VERSION ""

NS_ :

BS_:

BU_: APIM_CISM FCIMB RACM_RCIM DSP WCM DACMC HUD_ADV TRM_ITRM ACM GWM _delete APIM IPC GENERIC TSTR

BO_ 1056 SelectDriveModeData_HS3: 8 GWM
 SG_ AutoEpbButtnOn_B_Stat : 48|1@0+ (1,0) [0|1] "SED"  APIM,APIM_CISM
 SG_ PrkBrkElRleas_B_RqApa : 38|1@0+ (1,0) [0|0] "SED"  GENERIC
 SG_ AutoEpbMsgTxt_D_Rq : 58|3@0+ (1,0) [0|7] "SED"  APIM_CISM,APIM
 SG_ AutoEpbDsply_D_Stat : 37|2@0+ (1,0) [0|3] "SED"  APIM,APIM_CISM
 SG_ SelDrvMdePos12_B_Avail : 54|1@0+ (1,0) [0|1] "SED"  APIM_CISM,APIM,IPC
 SG_ SelDrvMdePos11_B_Avail : 55|1@0+ (1,0) [0|1] "SED"  APIM_CISM,APIM,IPC
 SG_ SelDrvMdePos10_B_Avail : 40|1@0+ (1,0) [0|1] "SED"  APIM_CISM,APIM,IPC
 SG_ SelDrvMdePos09_B_Avail : 41|1@0+ (1,0) [0|1] "SED"  APIM_CISM,APIM,IPC
 SG_ SelDrvMdePos08_B_Avail : 42|1@0+ (1,0) [0|1] "SED"  APIM_CISM,APIM,IPC
 SG_ SelDrvMdePos07_B_Avail : 43|1@0+ (1,0) [0|1] "SED"  APIM_CISM,APIM,IPC
 SG_ SelDrvMdePos06_B_Avail : 44|1@0+ (1,0) [0|1] "SED"  APIM_CISM,APIM,IPC
 SG_ SelDrvMdePos05_B_Avail : 45|1@0+ (1,0) [0|1] "SED"  APIM_CISM,APIM,IPC
 SG_ SelDrvMdePos04_B_Avail : 46|1@0+ (1,0) [0|1] "SED"  APIM_CISM,APIM,IPC
 SG_ SelDrvMdePos03_B_Avail : 47|1@0+ (1,0) [0|1] "SED"  APIM_CISM,APIM,IPC
 SG_ SelDrvMdePos02_B_Avail : 32|1@0+ (1,0) [0|1] "SED"  APIM_CISM,APIM,IPC
 SG_ SelDrvMdePos01_B_Avail : 24|1@0+ (1,0) [0|1] "SED"  APIM_CISM,APIM,IPC
 SG_ ActvDrvMde_D2_Stat : 53|5@0+ (1,0) [0|31] "SED"  APIM_CISM,HUD_ADV,APIM,DACMC,ACM,IPC
 SG_ SelDrvMde_D2_Rq : 63|5@0+ (1,0) [0|31] "SED"  APIM_CISM,APIM,IPC
 SG_ AwdMde_D_RqBrk : 35|3@0+ (1,0) [0|7] "SED"  GENERIC
 SG_ SelDrvMdeHmi03_D_Rq : 12|5@0+ (1,0) [0|31] "SED"  GENERIC
 SG_ SelDrvMdeMsgTxt2_D_Rq : 23|4@0+ (1,0) [0|15] "SED"  APIM_CISM,APIM
 SG_ SelDrvMdePt_D_Rq : 31|5@0+ (1,0) [0|31] "SED"  GENERIC
 SG_ SelDrvMdeMsgTxt_D_Rq : 19|4@0+ (1,0) [0|15] "SED"  IPC
 SG_ SelDrvMde_D_Stat : 26|2@0+ (1,0) [0|3] "SED"  APIM_CISM,APIM,IPC

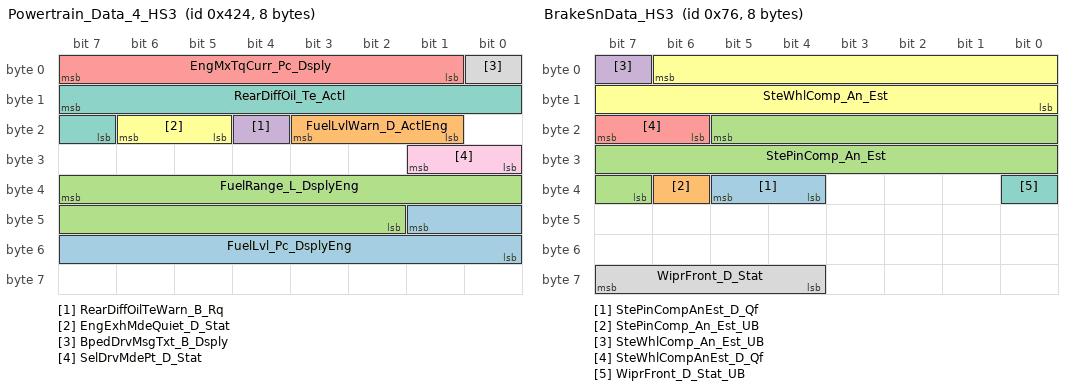
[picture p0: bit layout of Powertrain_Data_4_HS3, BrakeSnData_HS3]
BO_ 1060 Powertrain_Data_4_HS3: 8 GWM
 SG_ FuelLvl_Pc_DsplyEng : 41|10@0+ (0.108696,-5.217408) [-5.217408|105.9786] "percent"  APIM_CISM,APIM,IPC
 SG_ FuelLvlWarn_D_ActlEng : 19|3@0+ (1,0) [0|7] "SED"  APIM_CISM,APIM,IPC
 SG_ FuelRange_L_DsplyEng : 39|14@0+ (0.1,0) [0|1638.3] "kilometer"  IPC
 SG_ RearDiffOilTeWarn_B_Rq : 20|1@0+ (1,0) [0|1] "SED"  IPC
 SG_ EngMxTqCurr_Pc_Dsply : 7|7@0+ (1,0) [0|100] "percent"  IPC
 SG_ EngExhMdeQuiet_D_Stat : 22|2@0+ (1,0) [0|3] "SED"  APIM_CISM,ACM,IPC
 SG_ RearDiffOil_Te_Actl : 15|9@0+ (1,-40) [-40|470] "degC"  APIM_CISM,APIM,IPC
 SG_ BpedDrvMsgTxt_B_Dsply : 0|1@0+ (1,0) [0|1] "SED"  IPC
 SG_ SelDrvMdePt_D_Stat : 25|2@0+ (1,0) [0|3] "SED"  GENERIC

BO_ 118 BrakeSnData_HS3: 8 GWM
 SG_ StePinCompAnEst_D_Qf : 37|2@0+ (1,0) [0|3] "SED"  APIM,APIM_CISM,IPC
 SG_ StePinComp_An_Est_UB : 38|1@0+ (1,0) [0|1] "SED"  APIM,APIM_CISM,IPC
 SG_ StePinComp_An_Est : 21|15@0+ (0.1,-1600) [-1600|1676.7] "degrees"  APIM,APIM_CISM,IPC
 SG_ SteWhlComp_An_Est_UB : 7|1@0+ (1,0) [0|1] "SED"  APIM_CISM,APIM,IPC
 SG_ SteWhlCompAnEst_D_Qf : 23|2@0+ (1,0) [0|3] "SED"  IPC
 SG_ SteWhlComp_An_Est : 6|15@0+ (0.1,-1600) [-1600|1676.7] "deg"  APIM_CISM,APIM,IPC
 SG_ WiprFront_D_Stat_UB : 32|1@0+ (1,0) [0|1] "SED"  APIM_CISM,APIM
 SG_ WiprFront_D_Stat : 63|4@0+ (1,0) [0|15] "SED"  APIM_CISM,APIM

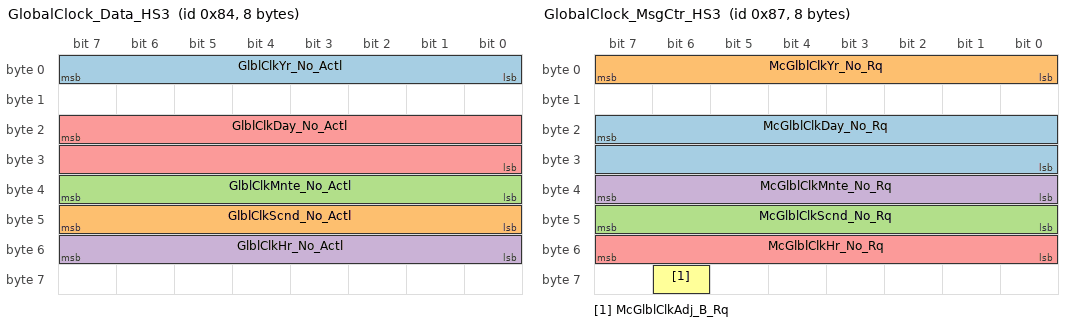
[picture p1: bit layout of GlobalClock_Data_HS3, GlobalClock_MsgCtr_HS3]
BO_ 132 GlobalClock_Data_HS3: 8 GWM
 SG_ GlblClkYr_No_Actl : 7|8@0+ (1,2000) [2000|2255] "year"  APIM_CISM,RACM_RCIM,HUD_ADV,APIM,IPC
 SG_ GlblClkScnd_No_Actl : 47|8@0+ (1,0) [0|255] "second"  APIM_CISM,RACM_RCIM,HUD_ADV,APIM,IPC
 SG_ GlblClkMnte_No_Actl : 39|8@0+ (1,0) [0|255] "minute"  APIM_CISM,RACM_RCIM,HUD_ADV,APIM,IPC
 SG_ GlblClkHr_No_Actl : 55|8@0+ (1,0) [0|255] "hour"  APIM_CISM,RACM_RCIM,HUD_ADV,APIM,IPC
 SG_ GlblClkDay_No_Actl : 23|16@0+ (1,0) [0|65535] "julian day"  APIM_CISM,RACM_RCIM,HUD_ADV,APIM,IPC

BO_ 135 GlobalClock_MsgCtr_HS3: 8 IPC
 SG_ McGlblClkDay_No_Rq : 23|16@0+ (1,0) [0|65535] "julian day"  GWM
 SG_ McGlblClkYr_No_Rq : 7|8@0+ (1,2000) [2000|2255] "year"  GWM
 SG_ McGlblClkScnd_No_Rq : 47|8@0+ (1,0) [0|255] "second"  GWM
 SG_ McGlblClkMnte_No_Rq : 39|8@0+ (1,0) [0|255] "minute"  GWM
 SG_ McGlblClkHr_No_Rq : 55|8@0+ (1,0) [0|255] "hour"  GWM
 SG_ McGlblClkAdj_B_Rq : 62|1@0+ (1,0) [0|1] "SED"  GWM

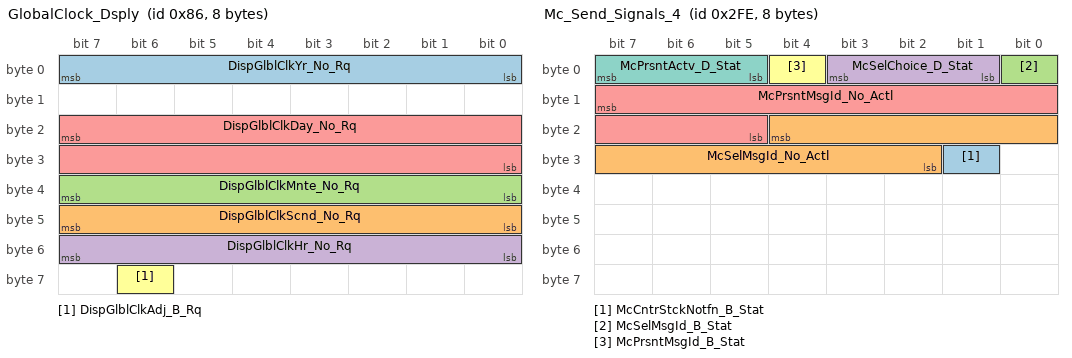
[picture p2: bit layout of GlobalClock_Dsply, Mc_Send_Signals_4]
BO_ 134 GlobalClock_Dsply: 8 APIM
 SG_ DispGlblClkYr_No_Rq : 7|8@0+ (1,2000) [2000|2255] "year"  IPC,GWM
 SG_ DispGlblClkScnd_No_Rq : 47|8@0+ (1,0) [0|255] "second"  IPC,GWM
 SG_ DispGlblClkMnte_No_Rq : 39|8@0+ (1,0) [0|255] "minute"  IPC,GWM
 SG_ DispGlblClkHr_No_Rq : 55|8@0+ (1,0) [0|255] "hour"  IPC,GWM
 SG_ DispGlblClkDay_No_Rq : 23|16@0+ (1,0) [0|65535] "julian day"  IPC,GWM
 SG_ DispGlblClkAdj_B_Rq : 62|1@0+ (1,0) [0|1] "SED"  IPC,GWM

BO_ 766 Mc_Send_Signals_4: 8 APIM
 SG_ McCntrStckNotfn_B_Stat : 25|1@0+ (1,0) [0|1] "SED"  IPC
 SG_ McSelMsgId_No_Actl : 20|11@0+ (1,0) [0|2047] "unitless"  IPC
 SG_ McSelMsgId_B_Stat : 0|1@0+ (1,0) [0|1] "SED"  IPC
 SG_ McSelChoice_D_Stat : 3|3@0+ (1,0) [0|7] "SED"  IPC
 SG_ McPrsntMsgId_No_Actl : 15|11@0+ (1,0) [0|2047] "unitless"  IPC
 SG_ McPrsntMsgId_B_Stat : 4|1@0+ (1,0) [0|1] "SED"  IPC
 SG_ McPrsntActv_D_Stat : 7|3@0+ (1,0) [0|7] "SED"  IPC

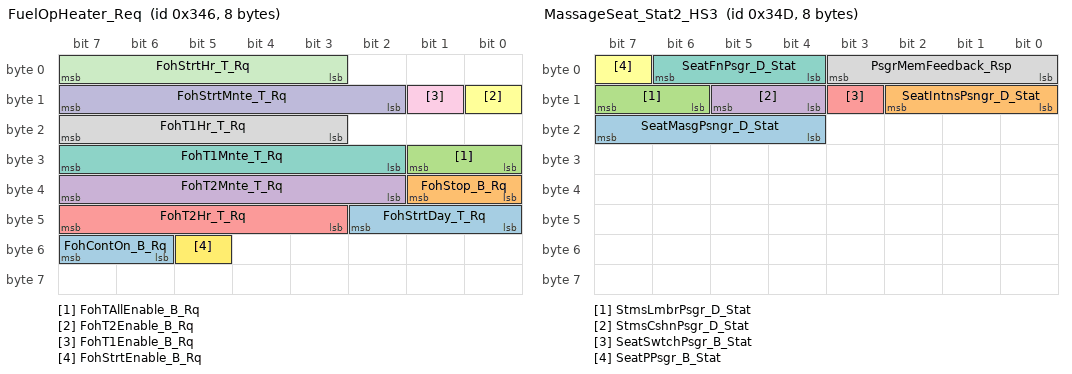
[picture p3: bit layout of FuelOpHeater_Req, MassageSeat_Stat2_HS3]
BO_ 838 FuelOpHeater_Req: 8 IPC
 SG_ FohStrtDay_T_Rq : 42|3@0+ (1,0) [0|7] "SED"  GWM
 SG_ FohStop_B_Rq : 33|2@0+ (1,0) [0|3] "SED"  GWM
 SG_ FohTAllEnable_B_Rq : 25|2@0+ (1,0) [0|3] "SED"  GWM
 SG_ FohT2Mnte_T_Rq : 39|6@0+ (1,0) [0|63] "minute"  GWM
 SG_ FohT2Hr_T_Rq : 47|5@0+ (1,0) [0|31] "hour"  GWM
 SG_ FohT2Enable_B_Rq : 8|1@0+ (1,0) [0|1] "SED"  GWM
 SG_ FohT1Mnte_T_Rq : 31|6@0+ (1,0) [0|63] "minute"  GWM
 SG_ FohT1Hr_T_Rq : 23|5@0+ (1,0) [0|31] "hour"  GWM
 SG_ FohT1Enable_B_Rq : 9|1@0+ (1,0) [0|1] "SED"  GWM
 SG_ FohStrtMnte_T_Rq : 15|6@0+ (1,0) [0|63] "minute"  GWM
 SG_ FohStrtHr_T_Rq : 7|5@0+ (1,0) [0|31] "hour"  GWM
 SG_ FohStrtEnable_B_Rq : 53|1@0+ (1,0) [0|1] "SED"  GWM
 SG_ FohContOn_B_Rq : 55|2@0+ (1,0) [0|3] "SED"  GWM

BO_ 559 ElecHorizon_Data2: 8 APIM
 SG_ EhData2_No_Actl : 7|64@0+ (1,0) [0|1.84467440737096E+019] "unitless"  HUD_ADV,GWM

BO_ 558 ElecHorizon_Data1: 8 APIM
 SG_ EhData1_No_Actl : 7|64@0+ (1,0) [0|1.84467440737096E+019] "unitless"  HUD_ADV,GWM

BO_ 939 ParkAid_Aud_Warn_Stat2_HS3: 8 GWM
 SG_ PrkAidSnsRlSide_D_Stat : 23|4@0+ (1,0) [0|15] "SED"  APIM_CISM,APIM,IPC
 SG_ SidePrkSnsR4_D_Stat : 55|4@0+ (1,0) [0|15] "SED"  APIM_CISM,APIM,IPC
 SG_ SidePrkSnsR3_D_Stat : 47|4@0+ (1,0) [0|15] "SED"  APIM_CISM,APIM,IPC
 SG_ SidePrkSnsL4_D_Stat : 43|4@0+ (1,0) [0|15] "SED"  APIM_CISM,APIM,IPC
 SG_ SidePrkSnsL3_D_Stat : 37|4@0+ (1,0) [0|15] "SED"  APIM_CISM,APIM,IPC
 SG_ PrkAidChime_D_Stat : 4|2@0+ (1,0) [0|3] "SED"  IPC
 SG_ PrkAidSnsRlCntr_D_Stat : 15|4@0+ (1,0) [0|15] "SED"  APIM_CISM,APIM,IPC
 SG_ PrkAidSnsRrCrnr_D_Stat : 31|4@0+ (1,0) [0|15] "SED"  APIM_CISM,APIM,IPC
 SG_ PrkAidSnsRrCntr_D_Stat : 19|4@0+ (1,0) [0|15] "SED"  APIM_CISM,APIM,IPC
 SG_ PrkAidSnsRlCrnr_D_Stat : 11|4@0+ (1,0) [0|15] "SED"  APIM_CISM,APIM,IPC
 SG_ PrkAidRear_D_Stat : 39|2@0+ (1,0) [0|3] "SED"  APIM_CISM,APIM,IPC
 SG_ PrkAidFront_D_Stat : 2|2@0+ (1,0) [0|3] "SED"  APIM_CISM,APIM,IPC
 SG_ PrkAid_D_Falt : 7|3@0+ (1,0) [0|7] "SED"  IPC
 SG_ PrkAidSnsRrSide_D_Stat : 27|4@0+ (1,0) [0|15] "SED"  APIM_CISM,APIM,IPC
 SG_ PrkAidLamp_D_Rq : 33|2@0+ (1,0) [0|3] "SED"  FCIMB
 SG_ ApaLongCtrlEnbl_D_Rq : 0|1@0+ (1,0) [0|1] "SED"  GENERIC
 SG_ ApaBrk_A_Rq : 63|8@0+ (0.05,-12.75) [-12.75|0] "m/sec^2"  GENERIC
 SG_ ApaBrk_D_Rq : 51|2@0+ (1,0) [0|3] "SED"  GENERIC

BO_ 938 ParkAid_Aud_Warn_Stat_HS3: 8 GWM
 SG_ SidePrkSnsR2_D_Stat : 59|4@0+ (1,0) [0|15] "SED"  APIM_CISM,APIM,IPC
 SG_ SidePrkSnsR1_D_Stat : 63|4@0+ (1,0) [0|15] "SED"  APIM_CISM,APIM,IPC
 SG_ SidePrkSnsL2_D_Stat : 51|4@0+ (1,0) [0|15] "SED"  APIM_CISM,APIM,IPC
 SG_ SidePrkSnsL1_D_Stat : 55|4@0+ (1,0) [0|15] "SED"  APIM_CISM,APIM,IPC
 SG_ ApaMde_D_Stat : 23|3@0+ (1,0) [0|7] "SED"  APIM_CISM,APIM,IPC
 SG_ ApaActvSd_D_Actl : 14|2@0+ (1,0) [0|3] "SED"  APIM_CISM,APIM,IPC
 SG_ PrkAidSwtch_B_Stat : 8|1@0+ (1,0) [0|1] "SED"  APIM_CISM,APIM,IPC
 SG_ PrkAidMsgTxt_D_Rq : 19|4@0+ (1,0) [0|15] "SED"  APIM_CISM,APIM,IPC
 SG_ ApaMde_D_Avail : 12|4@0+ (1,0) [0|15] "SED"  APIM_CISM,APIM
 SG_ PrkAidSnsFrSide_D_Stat : 43|4@0+ (1,0) [0|15] "SED"  APIM_CISM,APIM,IPC
 SG_ PrkAidSnsFrCrnr_D_Stat : 47|4@0+ (1,0) [0|15] "SED"  APIM_CISM,APIM,IPC
 SG_ PrkAidSnsFrCntr_D_Stat : 35|4@0+ (1,0) [0|15] "SED"  APIM_CISM,APIM,IPC
 SG_ PrkAidSnsFlSide_D_Stat : 39|4@0+ (1,0) [0|15] "SED"  APIM_CISM,APIM,IPC
 SG_ PrkAidSnsFlCrnr_D_Stat : 27|4@0+ (1,0) [0|15] "SED"  APIM_CISM,APIM,IPC
 SG_ PrkAidSnsFlCntr_D_Stat : 31|4@0+ (1,0) [0|15] "SED"  APIM,APIM_CISM,IPC
 SG_ RpaChime_D_Rq : 7|4@0+ (1,0) [0|15] "SED"  APIM_CISM,APIM,IPC
 SG_ FpaChime_D_Rq : 3|4@0+ (1,0) [0|15] "SED"  APIM_CISM,APIM,IPC
 SG_ PrkAidAudioMute_B_Rq : 15|1@0+ (1,0) [0|1] "SED"  IPC
 SG_ PrkBrkEl_B_RqFap : 20|1@0+ (1,0) [0|1] "SED"  GENERIC

BO_ 952 Tire_Pressure_Data_DRW_HS3: 8 GWM
 SG_ Tire_Press_IRR_Data : 23|16@0+ (1,0) [0|65533] "kilopascal"  APIM_CISM,APIM,IPC
 SG_ Tire_Press_ILR_Data : 7|16@0+ (1,0) [0|65533] "kilopascal"  APIM_CISM,APIM,IPC

BO_ 845 MassageSeat_Stat2_HS3: 8 GWM
 SG_ SeatMasgPsngr_D_Stat : 23|4@0+ (1,0) [0|15] "SED"  APIM_CISM,APIM
 SG_ SeatIntnsPsngr_D_Stat : 10|3@0+ (1,0) [0|7] "SED"  APIM_CISM,APIM
 SG_ StmsLmbrPsgr_D_Stat : 15|2@0+ (1,0) [0|3] "SED"  APIM_CISM,APIM
 SG_ StmsCshnPsgr_D_Stat : 13|2@0+ (1,0) [0|3] "SED"  APIM_CISM,APIM
 SG_ SeatSwtchPsgr_B_Stat : 11|1@0+ (1,0) [0|1] "SED"  APIM_CISM,APIM
 SG_ SeatPPsgr_B_Stat : 7|1@0+ (1,0) [0|1] "SED"  APIM_CISM,APIM
 SG_ SeatFnPsgr_D_Stat : 6|3@0+ (1,0) [0|7] "SED"  APIM_CISM,APIM
 SG_ PsgrMemFeedback_Rsp : 3|4@0+ (1,0) [0|15] "SED"  APIM_CISM,APIM

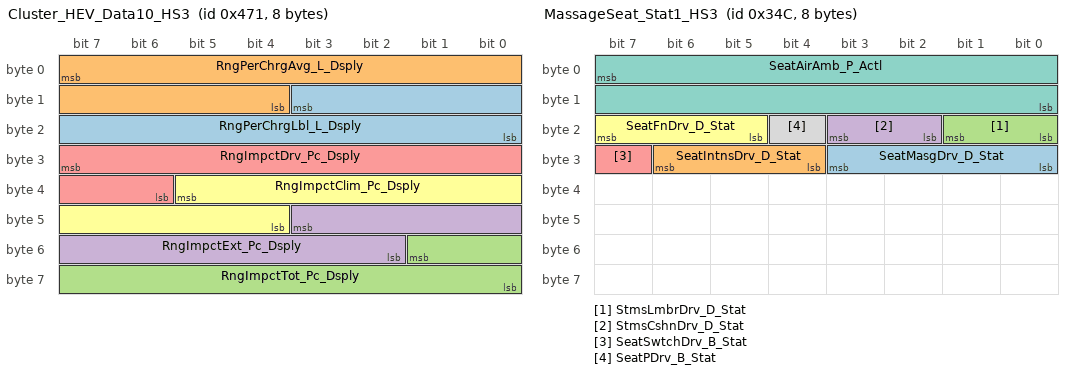
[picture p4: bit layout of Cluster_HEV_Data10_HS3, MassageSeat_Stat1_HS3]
BO_ 1137 Cluster_HEV_Data10_HS3: 8 GWM
 SG_ RngPerChrgLbl_L_Dsply : 11|12@0+ (0.1,0) [0|409.3] "km"  IPC
 SG_ RngPerChrgAvg_L_Dsply : 7|12@0+ (0.1,0) [0|409.3] "km"  APIM,IPC
 SG_ RngImpctTot_Pc_Dsply : 49|10@0+ (0.2,-102) [-102|102.4] "percent"  IPC
 SG_ RngImpctExt_Pc_Dsply : 43|10@0+ (0.2,-102) [-102|102.4] "percent"  IPC
 SG_ RngImpctDrv_Pc_Dsply : 31|10@0+ (0.2,-102) [-102|102.4] "percent"  IPC
 SG_ RngImpctClim_Pc_Dsply : 37|10@0+ (0.2,-102) [-102|102.4] "percent"  IPC

BO_ 1073 BodyEngGateway_1_HS3: 8 GWM
 SG_ AutoHoldMsgTxt_D_Rq : 62|4@0+ (1,0) [0|15] "SED"  IPC
 SG_ AutoHoldMde_D_Ind : 55|2@0+ (1,0) [0|3] "SED"  IPC
 SG_ SteEffort_D_Stat : 42|3@0+ (1,0) [0|7] "SED"  IPC
 SG_ TbsLamp_D_RqDsply : 33|2@0+ (1,0) [0|3] "SED"  IPC
 SG_ TrnMsgTxt_D_Rq : 30|4@0+ (1,0) [0|15] "SED"  IPC
 SG_ TrnGearNtmAllow_B_Stat : 22|1@0+ (1,0) [0|1] "SED"  APIM,IPC
 SG_ TrnGearMsgTxt_D_Rq : 20|5@0+ (1,0) [0|31] "SED"  APIM_CISM,IPC
 SG_ FuelFlw_Vl_ActlFoh : 7|16@0+ (25,0) [0|1638375] "microlitre"  APIM_CISM,APIM,IPC
 SG_ PdstrnAlrt_B_Falt_UB : 47|1@0+ (1,0) [0|1] "SED"  IPC
 SG_ PdstrnAlrt_B_Falt : 34|1@0+ (1,0) [0|1] "SED"  IPC
 SG_ TrnMsgTxt_D_Rq_UB : 26|1@0+ (1,0) [0|1] "SED"  IPC
 SG_ TrnMsgTxt2_D_Rq_UB : 25|1@0+ (1,0) [0|1] "SED"  IPC
 SG_ TrnGearNtmAllow_B_Stat_UB : 21|1@0+ (1,0) [0|1] "SED"  APIM,IPC
 SG_ TrnGearMsgTxt_D_Rq_UB : 31|1@0+ (1,0) [0|1] "SED"  APIM_CISM,APIM,IPC
 SG_ TbsLamp_D_RqDsply_UB : 24|1@0+ (1,0) [0|1] "SED"  IPC
 SG_ SteEffort_D_Stat_UB : 43|1@0+ (1,0) [0|1] "SED"  IPC
 SG_ RvrseMirrorChime_B_Rq_UB : 35|1@0+ (1,0) [0|1] "SED"  IPC
 SG_ FuelFlw_Vl_ActlFoh_UB : 23|1@0+ (1,0) [0|1] "SED"  APIM_CISM,APIM,IPC
 SG_ AutoHoldMsgTxt_D_Rq_UB : 58|1@0+ (1,0) [0|1] "SED"  IPC
 SG_ AutoHoldMde_D_Ind_UB : 63|1@0+ (1,0) [0|1] "SED"  IPC
 SG_ RvrseMirrorChime_B_Rq : 36|1@0+ (1,0) [0|1] "SED"  IPC
 SG_ TrnMsgTxt2_D_Rq : 39|3@0+ (1,0) [0|7] "SED"  IPC

BO_ 844 MassageSeat_Stat1_HS3: 8 GWM
 SG_ SeatMasgDrv_D_Stat : 27|4@0+ (1,0) [0|15] "SED"  APIM_CISM,APIM
 SG_ SeatIntnsDrv_D_Stat : 30|3@0+ (1,0) [0|7] "SED"  APIM_CISM,APIM
 SG_ StmsLmbrDrv_D_Stat : 17|2@0+ (1,0) [0|3] "SED"  APIM_CISM,APIM
 SG_ StmsCshnDrv_D_Stat : 19|2@0+ (1,0) [0|3] "SED"  APIM_CISM,APIM
 SG_ SeatSwtchDrv_B_Stat : 31|1@0+ (1,0) [0|1] "SED"  APIM_CISM,APIM
 SG_ SeatFnDrv_D_Stat : 23|3@0+ (1,0) [0|7] "SED"  APIM_CISM,APIM
 SG_ SeatAirAmb_P_Actl : 7|16@0+ (0.01,0) [0|655.35] "KiloPascal"  APIM_CISM,APIM
 SG_ SeatPDrv_B_Stat : 20|1@0+ (1,0) [0|1] "SED"  APIM_CISM,APIM

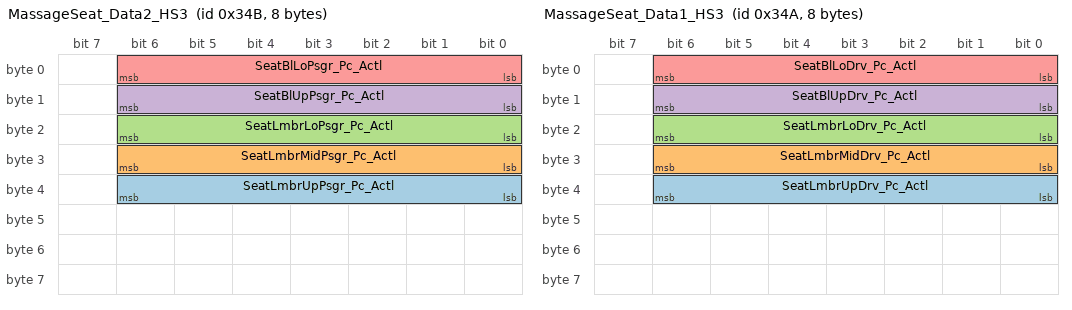
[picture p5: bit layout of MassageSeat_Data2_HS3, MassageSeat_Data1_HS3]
BO_ 843 MassageSeat_Data2_HS3: 8 GWM
 SG_ SeatLmbrUpPsgr_Pc_Actl : 38|7@0+ (1,0) [0|127] "Percent"  APIM_CISM,APIM
 SG_ SeatLmbrMidPsgr_Pc_Actl : 30|7@0+ (1,0) [0|127] "Percent"  APIM_CISM,APIM
 SG_ SeatLmbrLoPsgr_Pc_Actl : 22|7@0+ (1,0) [0|127] "Percent"  APIM_CISM,APIM
 SG_ SeatBlUpPsgr_Pc_Actl : 14|7@0+ (1,0) [0|126] "Percent"  APIM_CISM,APIM
 SG_ SeatBlLoPsgr_Pc_Actl : 6|7@0+ (1,0) [0|126] "Percent"  APIM_CISM,APIM

BO_ 842 MassageSeat_Data1_HS3: 8 GWM
 SG_ SeatLmbrUpDrv_Pc_Actl : 38|7@0+ (1,0) [0|127] "Percent"  APIM_CISM,APIM
 SG_ SeatLmbrMidDrv_Pc_Actl : 30|7@0+ (1,0) [0|127] "Percent"  APIM_CISM,APIM
 SG_ SeatLmbrLoDrv_Pc_Actl : 22|7@0+ (1,0) [0|127] "Percent"  APIM_CISM,APIM
 SG_ SeatBlUpDrv_Pc_Actl : 14|7@0+ (1,0) [0|126] "Percent"  APIM_CISM,APIM
 SG_ SeatBlLoDrv_Pc_Actl : 6|7@0+ (1,0) [0|126] "Percent"  APIM_CISM,APIM

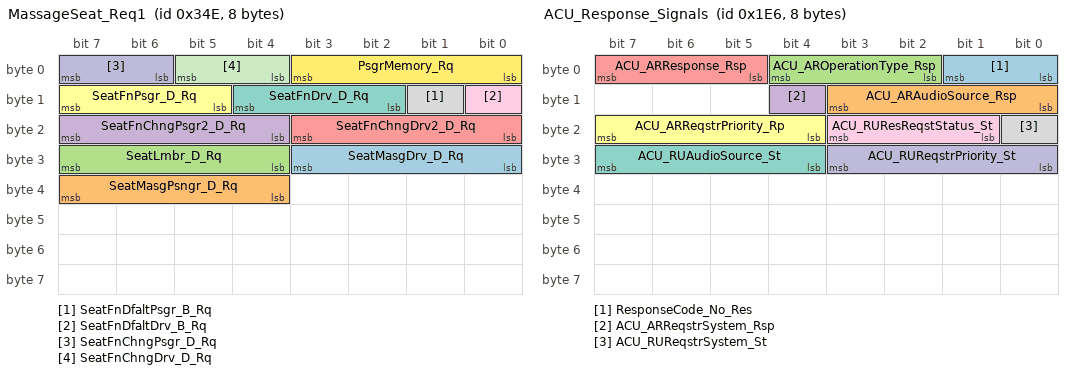
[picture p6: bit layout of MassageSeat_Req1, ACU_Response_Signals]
BO_ 846 MassageSeat_Req1: 8 APIM
 SG_ SeatMasgDrv_D_Rq : 27|4@0+ (1,0) [0|15] "SED"  GWM
 SG_ SeatMasgPsngr_D_Rq : 39|4@0+ (1,0) [0|15] "SED"  GWM
 SG_ SeatLmbr_D_Rq : 31|4@0+ (1,0) [0|15] "SED"  GWM
 SG_ SeatFnChngPsgr2_D_Rq : 23|4@0+ (1,0) [0|15] "SED"  GWM
 SG_ SeatFnChngDrv2_D_Rq : 19|4@0+ (1,0) [0|15] "SED"  GWM
 SG_ SeatFnPsgr_D_Rq : 15|3@0+ (1,0) [0|7] "SED"  GWM
 SG_ SeatFnDrv_D_Rq : 12|3@0+ (1,0) [0|7] "SED"  GWM
 SG_ SeatFnDfaltPsgr_B_Rq : 9|1@0+ (1,0) [0|1] "SED"  GWM
 SG_ SeatFnDfaltDrv_B_Rq : 8|1@0+ (1,0) [0|1] "SED"  GWM
 SG_ SeatFnChngPsgr_D_Rq : 7|2@0+ (1,0) [0|3] "SED"  GWM
 SG_ SeatFnChngDrv_D_Rq : 5|2@0+ (1,0) [0|3] "SED"  GWM
 SG_ PsgrMemory_Rq : 3|4@0+ (1,0) [0|15] "SED"  GWM

BO_ 935 Side_Detect_R_Stat_HS3: 8 GWM
 SG_ SodInnrRight_D_Stat : 20|2@0+ (1,0) [0|3] "SED"  APIM_CISM,GENERIC
 SG_ RbaCtaRight_D_Stat : 55|3@0+ (1,0) [0|7] "SED"  APIM_CISM,GENERIC
 SG_ LcwaRight_D_Stat : 52|3@0+ (1,0) [0|7] "SED"  APIM_CISM,GENERIC
 SG_ LcwaDetctRight2_B_Stat : 40|1@0+ (1,0) [0|1] "SED"  APIM_CISM,GENERIC
 SG_ LcwaDetctRight1_B_Stat : 41|1@0+ (1,0) [0|1] "SED"  APIM_CISM,GENERIC
 SG_ CtaInnrRight_D_Stat : 27|2@0+ (1,0) [0|3] "SED"  APIM_CISM,GENERIC
 SG_ CtaAlrtRight2_D_Stat : 30|3@0+ (1,0) [0|7] "SED"  APIM_CISM,IPC
 SG_ BttRight_D_Stat : 45|3@0+ (1,0) [0|7] "SED"  APIM_CISM,APIM,IPC
 SG_ BttRight_D_RqDrv : 47|2@0+ (1,0) [0|3] "SED"  APIM_CISM,APIM,IPC
 SG_ CtaBrkRightMsgTxt_B_Rq : 42|1@0+ (1,0) [0|1] "SED"  APIM_CISM,IPC
 SG_ CtaRightBrkEnbl_B_Rq : 31|1@0+ (1,0) [0|1] "SED"  APIM_CISM,GENERIC
 SG_ Side_Detect_R_Illum : 39|8@0+ (1,0) [0|255] "Percent"  APIM_CISM,IPC
 SG_ CtaSnsRight_D_Stat : 25|2@0+ (1,0) [0|3] "SED"  APIM_CISM,IPC
 SG_ CtaAlrtRight_D_Stat : 8|1@0+ (1,0) [0|1] "SED"  APIM_CISM,APIM,IPC
 SG_ CtaRight_D_Stat : 18|3@0+ (1,0) [0|7] "SED"  APIM_CISM,IPC
 SG_ SodRight_D_Stat : 15|3@0+ (1,0) [0|7] "SED"  APIM_CISM,IPC
 SG_ SodSnsRight_D_Stat : 12|2@0+ (1,0) [0|3] "SED"  APIM_CISM,IPC
 SG_ CtaRightBrkDecel_B_Rq : 7|1@0+ (1,0) [0|1] "SED"  APIM_CISM,GENERIC
 SG_ SodAlrtRight_D_Stat : 10|2@0+ (1,0) [0|3] "SED"  APIM_CISM,IPC
 SG_ SodDetctRight_D_Stat : 23|3@0+ (1,0) [0|7] "SED"  APIM_CISM,IPC
 SG_ SodWarnRight_Prd_Rq : 6|7@0+ (1,0) [0|127] "millisecond"  APIM_CISM,GENERIC

BO_ 934 Side_Detect_L_Stat_HS3: 8 GWM
 SG_ SodInnrLeft_D_Stat : 20|2@0+ (1,0) [0|3] "SED"  GENERIC
 SG_ RbaCtaLeft_D_Stat : 55|3@0+ (1,0) [0|7] "SED"  GENERIC
 SG_ LcwaDetctLeft2_B_Stat : 40|1@0+ (1,0) [0|1] "SED"  GENERIC
 SG_ LcwaDetctLeft1_B_Stat : 41|1@0+ (1,0) [0|1] "SED"  GENERIC
 SG_ CtaInnrLeft_D_Stat : 27|2@0+ (1,0) [0|3] "SED"  GENERIC
 SG_ LcwaLeft_D_Stat : 52|3@0+ (1,0) [0|7] "SED"  GENERIC
 SG_ CtaAlrtLeft2_D_Stat : 30|3@0+ (1,0) [0|7] "SED"  IPC
 SG_ BttLeft_D_Stat : 45|3@0+ (1,0) [0|7] "SED"  APIM,APIM_CISM,IPC
 SG_ BttLeft_D_RqDrv : 47|2@0+ (1,0) [0|3] "SED"  APIM_CISM,APIM,IPC
 SG_ CtaBrkLeftMsgTxt_B_Rq : 42|1@0+ (1,0) [0|1] "SED"  IPC
 SG_ CtaLeftBrkDecel_B_Rq : 7|1@0+ (1,0) [0|1] "SED"  GENERIC
 SG_ CtaLeftBrkEnbl_B_Rq : 31|1@0+ (1,0) [0|1] "SED"  GENERIC
 SG_ Side_Detect_L_Illum : 39|8@0+ (1,0) [0|255] "Percent"  IPC
 SG_ CtaSnsLeft_D_Stat : 25|2@0+ (1,0) [0|3] "SED"  IPC
 SG_ SodDetctLeft_D_Stat : 23|3@0+ (1,0) [0|7] "SED"  IPC
 SG_ CtaLeft_D_Stat : 18|3@0+ (1,0) [0|7] "SED"  IPC
 SG_ CtaAlrtLeft_D_Stat : 8|1@0+ (1,0) [0|1] "SED"  APIM_CISM,APIM,IPC
 SG_ SodLeft_D_Stat : 15|3@0+ (1,0) [0|7] "SED"  IPC
 SG_ SodSnsLeft_D_Stat : 12|2@0+ (1,0) [0|3] "SED"  IPC
 SG_ SodAlrtLeft_D_Stat : 10|2@0+ (1,0) [0|3] "SED"  IPC
 SG_ SodWarnLeft_Prd_Rq : 6|7@0+ (1,0) [0|127] "millisecond"  GENERIC

BO_ 486 ACU_Response_Signals: 8 ACM
 SG_ ResponseCode_No_Res : 1|2@0+ (1,0) [0|3] "SED"  APIM
 SG_ ACU_ARAudioSource_Rsp : 11|4@0+ (1,0) [0|15] "SED"  APIM,DSP,IPC
 SG_ ACU_AROperationType_Rsp : 4|3@0+ (1,0) [0|7] "SED"  APIM,DSP,IPC
 SG_ ACU_ARReqstrSystem_Rsp : 12|1@0+ (1,0) [0|1] "SED"  APIM,DSP,IPC
 SG_ ACU_ARResponse_Rsp : 7|3@0+ (1,0) [0|6] "SED"  APIM,DSP,IPC
 SG_ ACU_ARReqstrPriority_Rp : 23|4@0+ (1,0) [0|15] "SED"  APIM,DSP,IPC
 SG_ ACU_RUAudioSource_St : 31|4@0+ (1,0) [0|15] "SED"  GWM,RACM_RCIM,APIM,DSP,WCM,IPC
 SG_ ACU_RUReqstrSystem_St : 16|1@0+ (1,0) [0|1] "SED"  RACM_RCIM,APIM,DSP,IPC
 SG_ ACU_RUResReqstStatus_St : 19|3@0+ (1,0) [0|7] "SED"  GWM,RACM_RCIM,APIM,DSP,WCM,IPC
 SG_ ACU_RUReqstrPriority_St : 27|4@0+ (1,0) [0|15] "SED"  RACM_RCIM,APIM,DSP,WCM,IPC

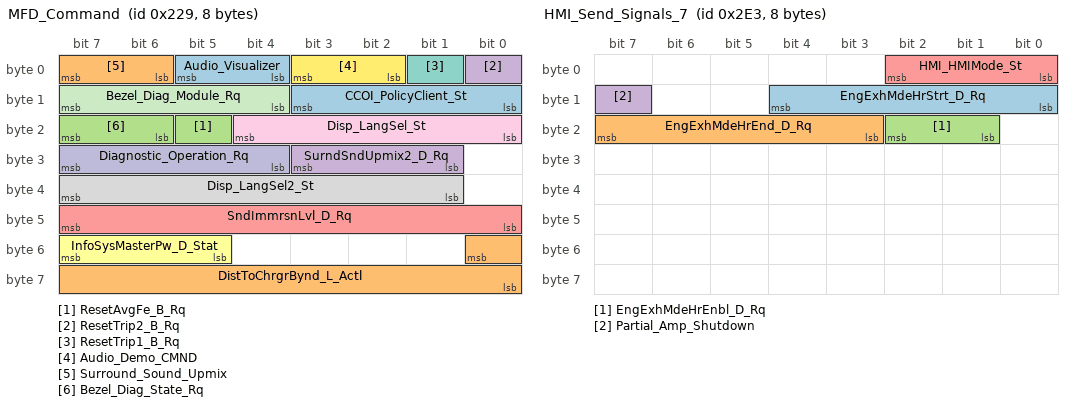
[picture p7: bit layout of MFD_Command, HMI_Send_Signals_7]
BO_ 553 MFD_Command: 8 APIM
 SG_ CCOI_PolicyClient_St : 11|4@0+ (1,0) [0|15] "SED"  GWM
 SG_ DistToChrgrBynd_L_Actl : 48|9@0+ (1,0) [0|509] "kilometer"  GWM
 SG_ ResetAvgFe_B_Rq : 21|1@0+ (1,0) [0|1] "SED"  IPC,GWM
 SG_ ResetTrip2_B_Rq : 0|1@0+ (1,0) [0|1] "SED"  GWM,IPC
 SG_ SndImmrsnLvl_D_Rq : 47|8@0+ (1,0) [0|255] "SED"  DSP,GWM
 SG_ InfoSysMasterPw_D_Stat : 55|3@0+ (1,0) [0|7] "SED"  GWM
 SG_ ResetTrip1_B_Rq : 1|1@0+ (1,0) [0|1] "SED"  GWM,IPC
 SG_ Disp_LangSel2_St : 39|7@0+ (1,0) [0|127] "SED"  GWM
 SG_ Disp_LangSel_St : 20|5@0+ (1,0) [0|31] "SED"  GWM,RACM_RCIM,IPC
 SG_ Diagnostic_Operation_Rq : 31|4@0+ (1,0) [0|15] "SED"  GWM,DSP,ACM
 SG_ Bezel_Diag_Module_Rq : 15|4@0+ (1,0) [0|15] "SED"  GWM,DSP,ACM
 SG_ Audio_Demo_CMND : 3|2@0+ (1,0) [0|3] "SED"  GWM,DSP,ACM
 SG_ Audio_Visualizer : 5|2@0+ (1,0) [0|3] "SED"  GWM,DSP,ACM
 SG_ Surround_Sound_Upmix : 7|2@0+ (1,0) [0|3] "SED"  GWM,DSP
 SG_ Bezel_Diag_State_Rq : 23|2@0+ (1,0) [0|3] "SED"  GWM,DSP,ACM
 SG_ SurndSndUpmix2_D_Rq : 27|3@0+ (1,0) [0|7] "SED"  GWM,DSP

BO_ 739 HMI_Send_Signals_7: 8 APIM
 SG_ EngExhMdeHrStrt_D_Rq : 12|5@0+ (1,0) [0|31] "SED"  GWM
 SG_ EngExhMdeHrEnd_D_Rq : 23|5@0+ (1,0) [0|31] "SED"  GWM
 SG_ EngExhMdeHrEnbl_D_Rq : 18|2@0+ (1,0) [0|3] "SED"  GWM
 SG_ Partial_Amp_Shutdown : 15|1@0+ (1,0) [0|1] "SED"  GWM,ACM
 SG_ HMI_HMIMode_St : 2|3@0+ (1,0) [0|7] "SED"  ACM,WCM,DSP,IPC,GWM

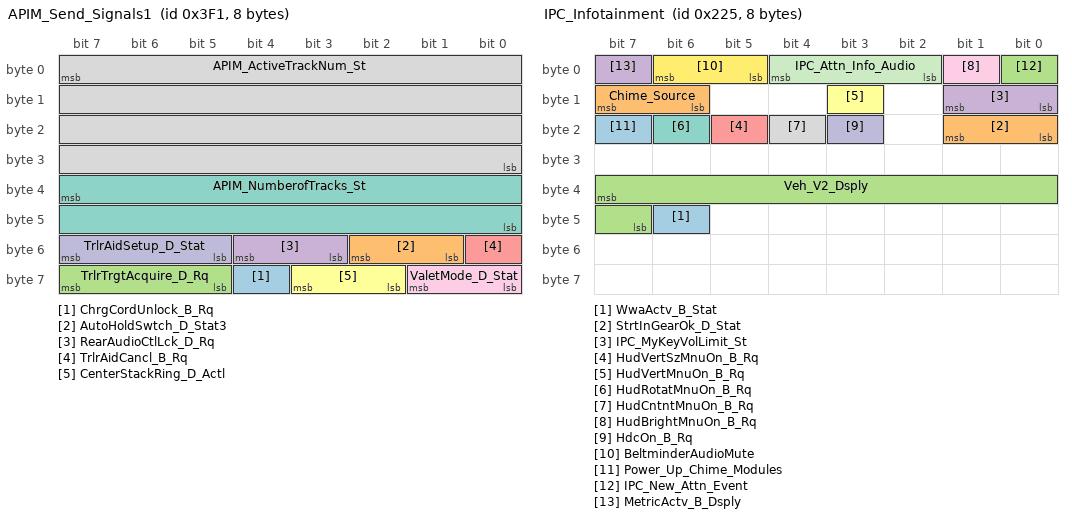
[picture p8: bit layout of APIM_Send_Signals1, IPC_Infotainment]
BO_ 1009 APIM_Send_Signals1: 8 APIM
 SG_ ChrgCordUnlock_B_Rq : 60|1@0+ (1,0) [0|1] "SED"  GWM
 SG_ AutoHoldSwtch_D_Stat3 : 50|2@0+ (1,0) [0|3] "SED"  GWM
 SG_ TrlrTrgtAcquire_D_Rq : 63|3@0+ (1,0) [0|7] "SED"  GWM
 SG_ RearAudioCtlLck_D_Rq : 52|2@0+ (1,0) [0|3] "SED"  RACM_RCIM
 SG_ TrlrAidCancl_B_Rq : 48|1@0+ (1,0) [0|1] "SED"  GWM
 SG_ CenterStackRing_D_Actl : 59|2@0+ (1,0) [0|3] "SED"  GWM
 SG_ APIM_NumberofTracks_St : 39|16@0+ (1,0) [0|65535] "unitless"  RACM_RCIM,GWM,HUD_ADV,IPC
 SG_ APIM_ActiveTrackNum_St : 7|32@0+ (1,0) [0|4294967295] "unitless"  RACM_RCIM,GWM,HUD_ADV,IPC
 SG_ ValetMode_D_Stat : 57|2@0+ (1,0) [0|3] "SED"  GWM
 SG_ TrlrAidSetup_D_Stat : 55|3@0+ (1,0) [0|7] "SED"  GWM,IPC

BO_ 531 DesiredTorqBrk_HS3: 8 GWM
 SG_ VehStop_D_Stat : 28|2@0+ (1,0) [0|3] "SED"  GENERIC
 SG_ TracCtlPtActv_B_Actl : 31|1@0+ (1,0) [0|1] "SED"  GENERIC
 SG_ PrkBrkYwLamp_D_Rq : 38|2@0+ (1,0) [0|3] "SED"  IPC
 SG_ PrkBrkRedLamp_D_Rq : 30|2@0+ (1,0) [0|3] "SED"  IPC
 SG_ PrkBrkMsgTxt_D_Rq : 36|4@0+ (1,0) [0|15] "SED"  IPC
 SG_ PrkBrkStatus : 26|3@0+ (1,0) [0|7] "SED"  APIM_CISM,APIM
 SG_ LscmbbMntr_B_Err : 17|1@0+ (1,0) [0|1] "SED"  IPC
 SG_ LscmbbBrkDis_B_Actl : 19|1@0+ (1,0) [0|1] "SED"  GENERIC
 SG_ StabCtlBrkActv_B_Actl : 23|1@0+ (1,0) [0|1] "SED"  APIM_CISM,APIM
 SG_ CmbbBrkPrchg_B_Actl : 59|1@0+ (1,0) [0|1] "SED"  TRM_ITRM
 SG_ CmbbBrkDecel_B_Actl : 58|1@0+ (1,0) [0|1] "SED"  TRM_ITRM
 SG_ CmbbBaSensInc_B_Actl : 57|1@0+ (1,0) [0|1] "SED"  GENERIC
 SG_ AccBrkWarm_B_Actl : 63|1@0+ (1,0) [0|1] "SED"  GENERIC
 SG_ AccBrkTotTqMn_B_Actl : 62|1@0+ (1,0) [0|1] "SED"  TRM_ITRM
 SG_ AccBrkPrchgActv_B_Actl : 61|1@0+ (1,0) [0|1] "SED"  GENERIC
 SG_ AccBrkDis_B_Actl : 44|1@0+ (1,0) [0|1] "SED"  GENERIC
 SG_ AccBrkDeny_B_Actl : 42|1@0+ (1,0) [0|1] "SED"  GENERIC
 SG_ AccBrkActv_B_Actl : 43|1@0+ (1,0) [0|1] "SED"  GENERIC
 SG_ PrplDrgCtlActv_B_Actl : 46|1@0+ (1,0) [0|1] "SED"  GENERIC
 SG_ PrplWhlTot_Tq_RqMx : 7|16@0+ (4,-131072) [-131072|131068] "Nm"  GENERIC
 SG_ AbsActv_B_Actl : 45|1@0+ (1,0) [0|1] "SED"  APIM_CISM,APIM,TRM_ITRM
 SG_ CmbbBrkDis_B_Actl : 56|1@0+ (1,0) [0|1] "SED"  GENERIC
 SG_ CmbbDeny_B_ActlBrk : 60|1@0+ (1,0) [0|1] "SED"  GENERIC
 SG_ CcDis_B_Cmd : 47|1@0+ (1,0) [0|1] "SED"  GENERIC
 SG_ VehLongOvrGnd_A_Est : 41|10@0+ (0.035,-17.9) [-17.9|17.835] "m/s^2"  TRM_ITRM
 SG_ AccStopActv_B_ActlBrk : 22|1@0+ (1,0) [0|1] "SED"  GENERIC
 SG_ AccDis_B_ActlEpb : 32|1@0+ (1,0) [0|1] "SED"  GENERIC
 SG_ LscmbbDeny_B_ActlBrk : 18|1@0+ (1,0) [0|1] "SED"  GENERIC
 SG_ LscmbbBrkDecel_B_Actl : 20|1@0+ (1,0) [0|1] "SED"  GENERIC
 SG_ LscmbbBaSensInc_B_Actl : 21|1@0+ (1,0) [0|1] "SED"  GENERIC
 SG_ LscmbBrkPrchg_B_Actl : 16|1@0+ (1,0) [0|1] "SED"  GENERIC
 SG_ VehicleStationary : 39|1@0+ (1,0) [0|1] "SED"  GENERIC

BO_ 702 PHONE_MC_WORD_Rx: 8 IPC
 SG_ PHONE_MC_WORD_Rx : 7|64@0+ (1,0) [0|1.84467440737096E+019] "unitless"  APIM_CISM,APIM

BO_ 711 MyKeySrvr_MyKeyClient_Word: 8 IPC
 SG_ MyKeySrvr_Clnt_Word_Tx : 7|64@0+ (1,0) [0|1.84467440737096E+019] "unitless"  APIM_CISM,APIM

BO_ 549 IPC_Infotainment: 8 IPC
 SG_ WwaActv_B_Stat : 46|1@0+ (1,0) [0|1] "SED"  APIM_CISM,GWM,ACM,APIM
 SG_ StrtInGearOk_D_Stat : 17|2@0+ (1,0) [0|3] "SED"  GWM
 SG_ Veh_V2_Dsply : 39|9@0+ (1,0) [0|511] "unitless"  APIM_CISM,APIM,GWM,HUD_ADV
 SG_ IPC_MyKeyVolLimit_St : 9|2@0+ (1,0) [0|3] "SED"  APIM_CISM,GWM,APIM,DSP,ACM
 SG_ HudVertSzMnuOn_B_Rq : 21|1@0+ (1,0) [0|1] "SED"  GWM,HUD_ADV
 SG_ HudVertMnuOn_B_Rq : 11|1@0+ (1,0) [0|1] "SED"  GWM,HUD_ADV
 SG_ HudRotatMnuOn_B_Rq : 22|1@0+ (1,0) [0|1] "SED"  GWM,HUD_ADV
 SG_ HudCntntMnuOn_B_Rq : 20|1@0+ (1,0) [0|1] "SED"  GWM,HUD_ADV
 SG_ HudBrightMnuOn_B_Rq : 1|1@0+ (1,0) [0|1] "SED"  GWM,HUD_ADV
 SG_ HdcOn_B_Rq : 19|1@0+ (1,0) [0|1] "SED"  GWM
 SG_ IPC_Attn_Info_Audio : 4|3@0+ (1,0) [0|7] "SED"  APIM_CISM,GWM,APIM,DSP,ACM
 SG_ BeltminderAudioMute : 6|2@0+ (1,0) [0|3] "SED"  APIM_CISM,GWM,APIM,DSP,ACM
 SG_ Power_Up_Chime_Modules : 23|1@0+ (1,0) [0|1] "SED"  APIM_CISM,GWM,DSP,ACM
 SG_ Chime_Source : 15|2@0+ (1,0) [0|3] "SED"  APIM_CISM,GWM,DSP,ACM
 SG_ IPC_New_Attn_Event : 0|1@0+ (1,0) [0|1] "SED"  APIM_CISM,GWM,APIM,DSP,ACM
 SG_ MetricActv_B_Dsply : 7|1@0+ (1,0) [0|1] "SED"  GWM,HUD_ADV,GENERIC

BO_ 765 Mc_Send_Signals_2: 8 IPC
 SG_ BalrSwtch_D_Stat : 57|2@0+ (1,0) [0|3] "SED"  GWM
 SG_ BalrMde_D_Rq : 59|2@0+ (1,0) [0|3] "SED"  GWM
 SG_ RstrnOnPsngr_D_RqMnu : 63|4@0+ (1,0) [0|15] "SED"  GWM
 SG_ WaitToStartLamp_D_Falt : 50|2@0+ (1,0) [0|3] "SED"  GWM
 SG_ EsaOn_B_Rq : 15|1@0+ (1,0) [0|1] "SED"  GWM
 SG_ BttOn_B_Rq : 26|1@0+ (1,0) [0|1] "SED"  GWM
 SG_ Btt_L_Actl : 39|7@0+ (0.1,0) [0|12.5] "meter"  GWM
 SG_ RearDiffLck_D_RqArb : 25|2@0+ (1,0) [0|3] "SED"  GWM
 SG_ AwdMde_D_RqArb : 47|3@0+ (1,0) [0|7] "SED"  GWM
 SG_ SelDrvMdeTxtReset_B_Rq : 40|1@0+ (1,0) [0|1] "SED"  GWM
 SG_ AutoTowAllw_D_RqMnu : 52|2@0+ (1,0) [0|3] "SED"  GWM
 SG_ DrvInputRequired_B_Rq : 32|1@0+ (1,0) [0|1] "SED"  GWM
 SG_ SelDrvMdeDsply_B_Avail : 41|1@0+ (1,0) [0|1] "SED"  GWM
 SG_ EngExhMdeQuiet_D_Rq : 17|2@0+ (1,0) [0|3] "SED"  GWM
 SG_ AirSusp_D_RqDrv : 31|2@0+ (1,0) [0|3] "SED"  GWM
 SG_ Mc_VehUntTrpCoUsrSel_St : 23|1@0+ (1,0) [0|1] "SED"  APIM_CISM,HUD_ADV,APIM,GWM
 SG_ Mc_VehUnitTempUsrSel_St : 22|1@0+ (1,0) [0|1] "SED"  APIM_CISM,HUD_ADV,APIM,RACM_RCIM,GWM
 SG_ Mc_VehDayNightUsrSel_St : 14|3@0+ (1,0) [0|7] "SED"  APIM_CISM,GWM,APIM,ACM
 SG_ Mc_VehTimeFrmtUsrSel_St : 1|2@0+ (1,0) [0|3] "SED"  APIM_CISM,GWM,HUD_ADV,APIM,RACM_RCIM,GENERIC
 SG_ Mc_VehThemeUsrSel_St : 11|4@0+ (1,0) [0|15] "SED"  APIM_CISM,GWM,APIM,GENERIC
 SG_ Mc_VehLangUsrSel_St : 7|6@0+ (1,0) [0|63] "SED"  APIM_CISM,HUD_ADV,APIM,ACM,GWM
 SG_ AwdRnge_D_ActlIpc : 29|3@0+ (1,0) [0|7] "SED"  GWM
 SG_ AwdDrvMde_D_Rq : 44|3@0+ (1,0) [0|7] "SED"  GWM
 SG_ EngExhMdeQuiet_D2_Rq : 55|3@0+ (1,0) [0|7] "SED"  GWM
 SG_ BrkLineLck_D_Rq : 19|2@0+ (1,0) [0|3] "SED"  GWM
 SG_ EdmSailMde_B_RqDrv : 48|1@0+ (1,0) [0|1] "SED"  GWM
 SG_ Running_Board_Cmd : 21|2@0+ (1,0) [0|3] "SED"  GWM

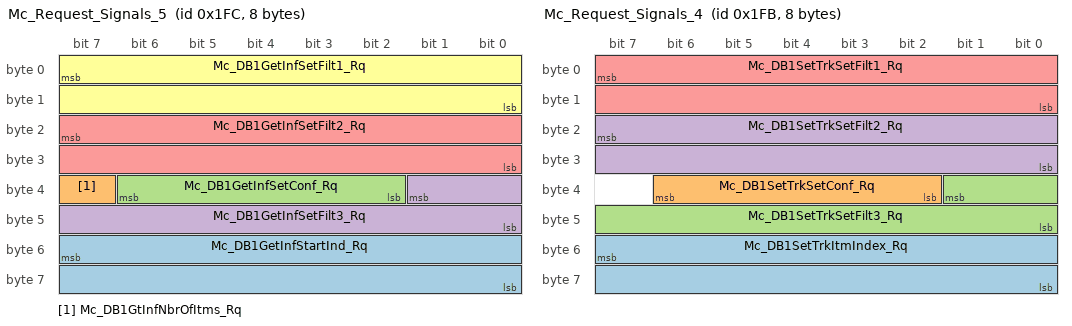
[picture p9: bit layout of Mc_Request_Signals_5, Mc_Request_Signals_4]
BO_ 508 Mc_Request_Signals_5: 8 IPC
 SG_ Mc_DB1GetInfStartInd_Rq : 55|16@0+ (1,0) [0|65535] "unitless"  ACM
 SG_ Mc_DB1GtInfNbrOfItms_Rq : 39|1@0+ (1,0) [0|1] "SED"  ACM
 SG_ Mc_DB1GetInfSetConf_Rq : 38|5@0+ (1,0) [0|31] "SED"  ACM
 SG_ Mc_DB1GetInfSetFilt3_Rq : 33|10@0+ (1,0) [0|1023] "unitless"  ACM
 SG_ Mc_DB1GetInfSetFilt2_Rq : 23|16@0+ (1,0) [0|65535] "unitless"  ACM
 SG_ Mc_DB1GetInfSetFilt1_Rq : 7|16@0+ (1,0) [0|65535] "unitless"  ACM

BO_ 507 Mc_Request_Signals_4: 8 IPC
 SG_ Mc_DB1SetTrkItmIndex_Rq : 55|16@0+ (1,0) [0|65535] "unitless"  ACM
 SG_ Mc_DB1SetTrkSetConf_Rq : 38|5@0+ (1,0) [0|31] "SED"  ACM
 SG_ Mc_DB1SetTrkSetFilt3_Rq : 33|10@0+ (1,0) [0|1023] "unitless"  ACM
 SG_ Mc_DB1SetTrkSetFilt2_Rq : 23|16@0+ (1,0) [0|65535] "unitless"  ACM
 SG_ Mc_DB1SetTrkSetFilt1_Rq : 7|16@0+ (1,0) [0|65535] "unitless"  ACM

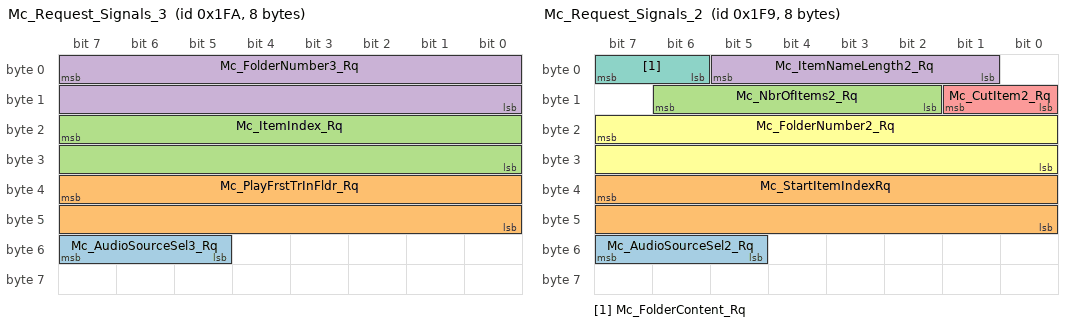
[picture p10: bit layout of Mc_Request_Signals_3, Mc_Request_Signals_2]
BO_ 506 Mc_Request_Signals_3: 8 IPC
 SG_ Mc_AudioSourceSel3_Rq : 55|3@0+ (1,0) [0|7] "SED"  ACM
 SG_ Mc_PlayFrstTrInFldr_Rq : 39|16@0+ (1,0) [0|65535] "unitless"  ACM
 SG_ Mc_ItemIndex_Rq : 23|16@0+ (1,0) [0|65535] "unitless"  ACM
 SG_ Mc_FolderNumber3_Rq : 7|16@0+ (1,0) [0|65535] "unitless"  ACM

BO_ 505 Mc_Request_Signals_2: 8 IPC
 SG_ Mc_AudioSourceSel2_Rq : 55|3@0+ (1,0) [0|7] "SED"  ACM
 SG_ Mc_StartItemIndexRq : 39|16@0+ (1,0) [0|65535] "unitless"  ACM
 SG_ Mc_NbrOfItems2_Rq : 14|5@0+ (1,0) [0|20] "SED"  ACM
 SG_ Mc_ItemNameLength2_Rq : 5|5@0+ (1,0) [0|20] "SED"  ACM
 SG_ Mc_CutItem2_Rq : 9|2@0+ (1,0) [0|3] "SED"  ACM
 SG_ Mc_FolderNumber2_Rq : 23|16@0+ (1,0) [0|65535] "unitless"  ACM
 SG_ Mc_FolderContent_Rq : 7|2@0+ (1,0) [0|3] "SED"  ACM

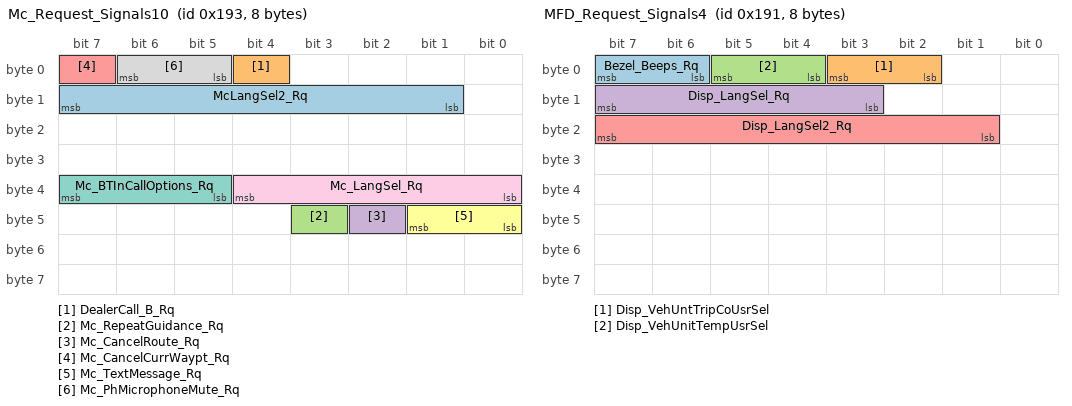
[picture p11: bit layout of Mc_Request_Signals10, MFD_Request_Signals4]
BO_ 403 Mc_Request_Signals10: 8 IPC
 SG_ McLangSel2_Rq : 15|7@0+ (1,0) [0|7] "SED"  APIM_CISM,APIM
 SG_ DealerCall_B_Rq : 4|1@0+ (1,0) [0|1] "SED"  APIM_CISM,APIM
 SG_ Mc_RepeatGuidance_Rq : 43|1@0+ (1,0) [0|1] "SED"  APIM_CISM,APIM
 SG_ Mc_CancelRoute_Rq : 42|1@0+ (1,0) [0|1] "SED"  APIM_CISM,APIM
 SG_ Mc_CancelCurrWaypt_Rq : 7|1@0+ (1,0) [0|1] "SED"  APIM_CISM,APIM
 SG_ Mc_TextMessage_Rq : 41|2@0+ (1,0) [0|3] "SED"  APIM_CISM,APIM
 SG_ Mc_BTInCallOptions_Rq : 39|3@0+ (1,0) [0|7] "SED"  APIM_CISM,APIM
 SG_ Mc_PhMicrophoneMute_Rq : 6|2@0+ (1,0) [0|3] "SED"  APIM_CISM,APIM
 SG_ Mc_LangSel_Rq : 36|5@0+ (1,0) [0|31] "SED"  APIM_CISM,APIM

BO_ 401 MFD_Request_Signals4: 8 APIM
 SG_ Bezel_Beeps_Rq : 7|2@0+ (1,0) [0|3] "SED"  FCIMB,GWM
 SG_ Disp_VehUntTripCoUsrSel : 3|2@0+ (1,0) [0|3] "SED"  IPC
 SG_ Disp_VehUnitTempUsrSel : 5|2@0+ (1,0) [0|3] "SED"  IPC
 SG_ Disp_LangSel_Rq : 15|5@0+ (1,0) [0|31] "SED"  IPC
 SG_ Disp_LangSel2_Rq : 23|7@0+ (1,0) [0|127] "SED"  IPC

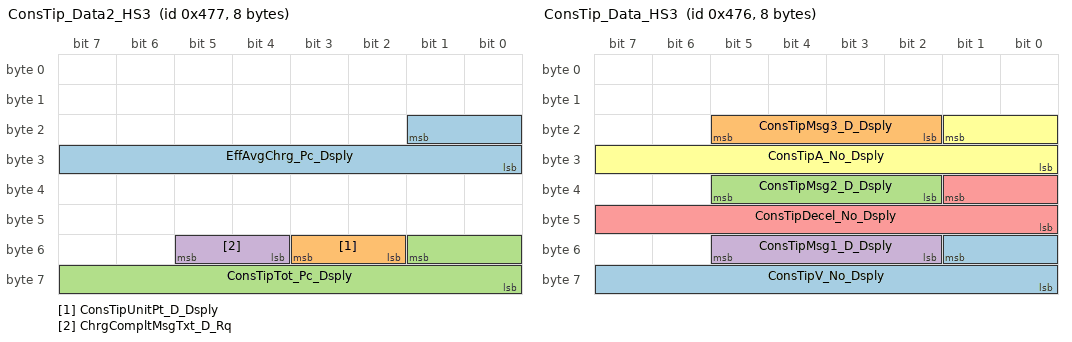
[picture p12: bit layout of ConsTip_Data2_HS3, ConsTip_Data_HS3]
BO_ 1143 ConsTip_Data2_HS3: 8 GWM
 SG_ EffAvgChrg_Pc_Dsply : 17|10@0+ (0.1,0) [0|102.3] "percent"  IPC
 SG_ ConsTipUnitPt_D_Dsply : 51|2@0+ (1,0) [0|3] "SED"  APIM_CISM,IPC,APIM
 SG_ ConsTipTot_Pc_Dsply : 49|10@0+ (0.1,0) [0|102.1] "percent"  IPC
 SG_ ChrgCompltMsgTxt_D_Rq : 53|2@0+ (1,0) [0|3] "SED"  APIM_CISM,APIM,IPC

BO_ 1142 ConsTip_Data_HS3: 8 GWM
 SG_ ConsTipV_No_Dsply : 49|10@0+ (0.1,0) [0|102.1] "percent"  APIM_CISM,IPC,APIM
 SG_ ConsTipMsg3_D_Dsply : 21|4@0+ (1,0) [0|15] "SED"  APIM_CISM,IPC,APIM
 SG_ ConsTipMsg2_D_Dsply : 37|4@0+ (1,0) [0|15] "SED"  APIM_CISM,IPC,APIM
 SG_ ConsTipMsg1_D_Dsply : 53|4@0+ (1,0) [0|15] "SED"  APIM_CISM,IPC,APIM
 SG_ ConsTipDecel_No_Dsply : 33|10@0+ (0.1,0) [0|102.1] "percent"  APIM_CISM,IPC,APIM
 SG_ ConsTipA_No_Dsply : 17|10@0+ (0.1,0) [0|102.1] "percent"  APIM_CISM,IPC,APIM

BO_ 947 OutsideAirTempStat: 8 GWM
 SG_ Outside_Air_Temp_Stat_UB : 48|1@0+ (1,0) [0|1] "SED"  APIM_CISM,APIM,WCM,IPC
 SG_ Outside_Air_Temp_Stat : 39|8@0+ (0.5,-40) [-40|86.5] "Degrees C"  APIM_CISM,APIM,WCM,IPC

BO_ 973 Traffic_RecogitionData_HS3: 8 GWM
 SG_ LaSysOffStat_D_Dsply : 58|2@0+ (1,0) [0|3] "SED"  IPC
 SG_ TsrVl1RstrcMsgTxt2_D_Rq : 51|3@0+ (1,0) [0|7] "SED"  HUD_ADV,IPC
 SG_ TsrVl2RstrcMsgTxt2_D_Rq : 63|3@0+ (1,0) [0|7] "SED"  HUD_ADV,IPC
 SG_ TsrVl2PrmntMsgTxt_D_Rq : 60|2@0+ (1,0) [0|3] "SED"  HUD_ADV,IPC
 SG_ TsrVl1PrmntMsgTxt_D_Rq : 41|2@0+ (1,0) [0|3] "SED"  HUD_ADV,IPC
 SG_ TsrOvtkMsgTxt2_D_Rq : 55|4@0+ (1,0) [0|15] "SED"  HUD_ADV,IPC
 SG_ WwaWarn_B_Rq : 48|1@0+ (1,0) [0|1] "SED"  HUD_ADV,IPC
 SG_ TsrVlUnitMsgTxt_D_Rq : 43|2@0+ (1,0) [0|3] "SED"  APIM_CISM,HUD_ADV,APIM,IPC
 SG_ TsrVLim2MsgTxt_D_Rq : 39|8@0+ (1,0) [0|255] "SED"  HUD_ADV,IPC
 SG_ TsrVLim1MsgTxt_D_Rq : 31|8@0+ (1,0) [0|255] "SED"  HUD_ADV,IPC
 SG_ TsrVl2StatMsgTxt_D_Rq : 47|2@0+ (1,0) [0|3] "SED"  HUD_ADV,IPC
 SG_ TsrVl2RstrcMsgTxt_D_Rq : 17|2@0+ (1,0) [0|3] "SED"  IPC
 SG_ TsrVl1StatMsgTxt_D_Rq : 21|2@0+ (1,0) [0|3] "SED"  HUD_ADV,IPC
 SG_ TsrVl1RstrcMsgTxt_D_Rq : 23|2@0+ (1,0) [0|3] "SED"  IPC
 SG_ TsrStatMsgTxt_D_Rq : 10|3@0+ (1,0) [0|7] "SED"  IPC
 SG_ TsrOvtkStatMsgTxt_D_Rq : 1|2@0+ (1,0) [0|3] "SED"  HUD_ADV,IPC
 SG_ TsrOvtkMsgTxt_D_Rq : 15|3@0+ (1,0) [0|7] "SED"  HUD_ADV,IPC
 SG_ TsrOswWarnMsgTxt_D_Rq : 3|2@0+ (1,0) [0|3] "SED"  HUD_ADV,IPC
 SG_ TsrMsgTxt_D_Rq : 7|4@0+ (1,0) [0|15] "SED"  IPC

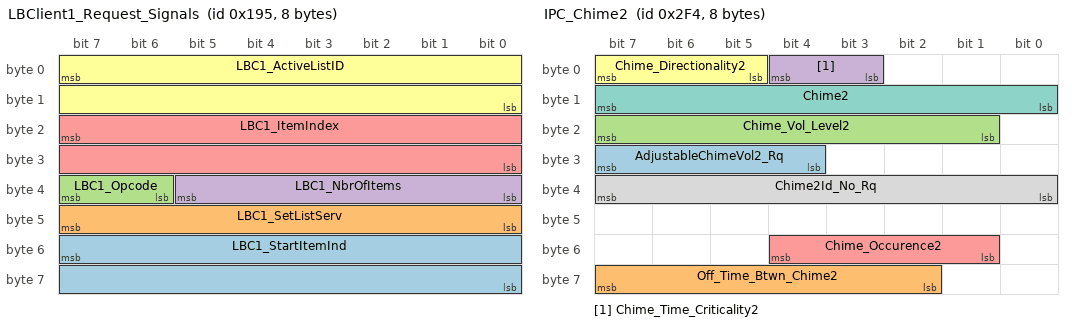
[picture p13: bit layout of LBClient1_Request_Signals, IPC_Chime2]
BO_ 405 LBClient1_Request_Signals: 8 IPC
 SG_ LBC1_StartItemInd : 55|16@0+ (1,0) [0|65535] "unitless"  APIM_CISM,ACM,APIM
 SG_ LBC1_SetListServ : 47|8@0+ (1,0) [0|255] "unitless"  APIM_CISM,ACM,APIM
 SG_ LBC1_Opcode : 39|2@0+ (1,0) [0|3] "SED"  APIM_CISM,ACM,APIM
 SG_ LBC1_NbrOfItems : 37|6@0+ (1,0) [0|63] "unitless"  APIM_CISM,ACM,APIM
 SG_ LBC1_ItemIndex : 23|16@0+ (1,0) [0|65535] "unitless"  APIM_CISM,ACM,APIM
 SG_ LBC1_ActiveListID : 7|16@0+ (1,0) [0|65535] "unitless"  APIM_CISM,APIM,ACM

BO_ 756 IPC_Chime2: 8 IPC
 SG_ AdjustableChimeVol2_Rq : 31|4@0+ (1,0) [0|15] "SED"  APIM_CISM,ACM,DSP
 SG_ Off_Time_Btwn_Chime2 : 63|6@0+ (1,0) [0|52] "unitless"  APIM_CISM,ACM,DSP
 SG_ Chime_Vol_Level2 : 23|7@0+ (1,0) [0|127] "unitless"  APIM_CISM,ACM,DSP
 SG_ Chime_Time_Criticality2 : 4|2@0+ (1,0) [0|3] "SED"  APIM_CISM,ACM,DSP
 SG_ Chime_Occurence2 : 52|4@0+ (1,0) [0|15] "SED"  APIM_CISM,ACM,DSP
 SG_ Chime_Directionality2 : 7|3@0+ (1,0) [0|7] "SED"  APIM_CISM,ACM,DSP
 SG_ Chime2 : 15|8@0+ (1,0) [0|255] "unitless"  APIM_CISM,ACM,DSP
 SG_ Chime2Id_No_Rq : 39|8@0+ (1,0) [0|255] "SED"  APIM_CISM,DSP,ACM

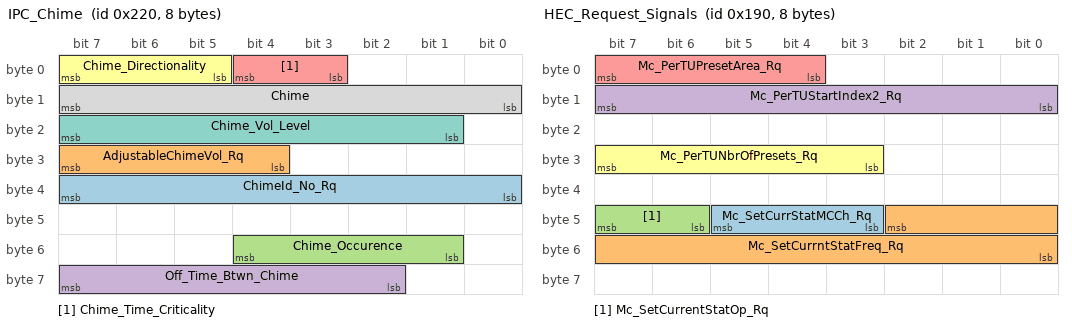
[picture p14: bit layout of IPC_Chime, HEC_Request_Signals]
BO_ 544 IPC_Chime: 8 IPC
 SG_ ChimeId_No_Rq : 39|8@0+ (1,0) [0|255] "SED"  ACM
 SG_ AdjustableChimeVol_Rq : 31|4@0+ (1,0) [0|15] "SED"  ACM,DSP
 SG_ Chime_Occurence : 52|4@0+ (1,0) [0|15] "SED"  APIM_CISM,DSP,ACM
 SG_ Off_Time_Btwn_Chime : 63|6@0+ (1,0) [0|52] "unitless"  APIM_CISM,DSP,ACM
 SG_ Chime_Time_Criticality : 4|2@0+ (1,0) [0|3] "SED"  APIM_CISM,DSP,ACM
 SG_ Chime_Directionality : 7|3@0+ (1,0) [0|7] "SED"  APIM_CISM,DSP,ACM
 SG_ Chime_Vol_Level : 23|7@0+ (1,0) [0|127] "unitless"  APIM_CISM,DSP,ACM
 SG_ Chime : 15|8@0+ (1,0) [0|255] "unitless"  APIM_CISM,DSP,ACM

BO_ 291 HEC_Response_Signals: 8 IPC
 SG_ LangUpdate_Rsp : 7|2@0+ (1,0) [0|3] "SED"  APIM_CISM,APIM

BO_ 400 HEC_Request_Signals: 8 IPC
 SG_ Mc_SetCurrStatMCCh_Rq : 45|3@0+ (1,0) [0|7] "SED"  ACM
 SG_ Mc_SetCurrntStatFreq_Rq : 42|11@0+ (1,0) [0|1557] "unitless"  ACM
 SG_ Mc_SetCurrentStatOp_Rq : 47|2@0+ (1,0) [0|3] "SED"  ACM
 SG_ Mc_PerTUStartIndex2_Rq : 15|8@0+ (1,0) [0|255] "unitless"  ACM,APIM_CISM,APIM
 SG_ Mc_PerTUPresetArea_Rq : 7|4@0+ (1,0) [0|15] "SED"  ACM,APIM_CISM,APIM
 SG_ Mc_PerTUNbrOfPresets_Rq : 31|5@0+ (1,0) [0|31] "SED"  ACM,APIM_CISM,APIM

BO_ 647 HEC_DispDimm: 8 IPC
 SG_ HEC_BTIncomingCall_Rq : 23|2@0+ (1,0) [0|3] "SED"  APIM
 SG_ HEC_BTEndTelService_Rq : 3|2@0+ (1,0) [0|3] "SED"  APIM

BO_TX_BU_ 134 : APIM_CISM,APIM;
BO_TX_BU_ 558 : APIM_CISM,APIM;
BO_TX_BU_ 846 : APIM_CISM,APIM;
BO_TX_BU_ 553 : APIM_CISM,APIM;
BO_TX_BU_ 739 : APIM_CISM,APIM;
BO_TX_BU_ 1009 : APIM_CISM,APIM;
BO_TX_BU_ 401 : APIM_CISM,APIM;
CM_ SG_ 118 SteWhlCompAnEst_D_Qf "Legacy signal not supported, reserving bit locations for commodity BCM, PAM, RCM, APIM dbc files.  GWM to Tx Init value, no valid data. ";
CM_ SG_ 118 SteWhlComp_An_Est "Legacy signal not supported, reserving bit locations for commodity BCM, PAM, RCM, APIM dbc files.  GWM to Tx Init value, no valid data. ";
CM_ BO_ 134 "FCDIM APIM TX";
CM_ BO_ 559 "APIM Tx";
CM_ BO_ 558 "APIM Tx";
CM_ SG_ 1073 TrnGearNtmAllow_B_Stat "Signal not transmitted on vehicles that do not have shift by wire.";
CM_ SG_ 1073 TrnGearMsgTxt_D_Rq "Signal not transmitted on vehicles that do not have shift by wire.";
CM_ SG_ 1073 FuelFlw_Vl_ActlFoh "Signal not transmitted on vehicles that do not have the Fuel operated heater feature.";
CM_ BO_ 846 "APIM Tx";
CM_ SG_ 935 CtaInnrRight_D_Stat "IPCGenSigTimeoutTime=1600";
CM_ SG_ 935 Side_Detect_R_Illum "DDMGenSigTimeoutTime=2000";
CM_ SG_ 935 SodRight_D_Stat "IPCGenSigTimeoutTime=1600";
CM_ SG_ 935 SodSnsRight_D_Stat "IPCGenSigTimeoutTime=1600";
CM_ SG_ 935 SodAlrtRight_D_Stat "DDMGenSigTimeoutTime=2000";
CM_ SG_ 934 CtaInnrLeft_D_Stat "IPCGenSigTimeoutTime=1600";
CM_ SG_ 934 Side_Detect_L_Illum "DDMGenSigTimeoutTime=2000";
CM_ SG_ 934 SodLeft_D_Stat "IPCGenSigTimeoutTime=1600";
CM_ SG_ 934 SodSnsLeft_D_Stat "IPCGenSigTimeoutTime=1600";
CM_ SG_ 934 SodAlrtLeft_D_Stat "DDMGenSigTimeoutTime=2000";
CM_ BO_ 486 "ACM Tx";
CM_ SG_ 486 ACU_ARAudioSource_Rsp "Object Audio Management AudioClient.AudioRequest.Requested Audio Source";
CM_ SG_ 486 ACU_AROperationType_Rsp "Object Audio Management AudioClient.AudioRequest.Operation Type";
CM_ SG_ 486 ACU_ARReqstrSystem_Rsp "Object Audio Management AudioClient.AudioRequest.Requester System";
CM_ SG_ 486 ACU_ARResponse_Rsp "Object Audio Management AudioClient.AudioRequest.Response";
CM_ SG_ 486 ACU_ARReqstrPriority_Rp "AR = Audio Request (this signal belongs to the logical signal AudioRequest.Rsp)
Object = AudioClient
Logical Signal = AudioRequest
Parameter = Requester Priority

Disc shall be used for both CD and MC";
CM_ SG_ 486 ACU_RUAudioSource_St "Object Audio Management Audio Client.ResourceUpdate.Requested Audio Source
";
CM_ SG_ 486 ACU_RUReqstrSystem_St "Object Audio Management Audio Client.ResourceUpdate.Requester System";
CM_ SG_ 486 ACU_RUResReqstStatus_St "Object Audio Management Audio Client.ResourceUpdate.Resource Request Status";
CM_ SG_ 486 ACU_RUReqstrPriority_St "Object Audio Management Audio Client.ResourceUpdate.Requester Priority";
CM_ BO_ 553 "FCDIM, APIM Tx";
CM_ SG_ 553 SndImmrsnLvl_D_Rq "ImmersionLevel_D_Rq";
CM_ SG_ 553 Disp_LangSel2_St "Reference GSDB for encoding: 009522/B;2-ZZ_LangSel";
CM_ SG_ 553 Disp_LangSel_St "Object.VehicleSettings.Disp_LangSel.St.Language";
CM_ SG_ 553 Diagnostic_Operation_Rq "Object:BezelDiagnostics.MFD_Bezel_Diagnostic.St";
CM_ SG_ 553 Bezel_Diag_Module_Rq "Object:BezelDiagnostics.MFD_Bezel_Diagnostic.St";
CM_ SG_ 553 Audio_Demo_CMND "Object. AudioSettings.Audio Demo_CMND";
CM_ SG_ 553 Audio_Visualizer "Object.AudioSettings.Audio_Visualizer
";
CM_ SG_ 553 Surround_Sound_Upmix "Object.AudioSettings.Surround_Sound_Upmix

";
CM_ SG_ 553 Bezel_Diag_State_Rq "Object:BezelDiagnostics.MFD_Bezel_Diagnostic.Rq";
CM_ SG_ 553 SurndSndUpmix2_D_Rq "Object:Surround_Sound_Upmix2_Rq";
CM_ BO_ 739 "FCDIM Tx";
CM_ SG_ 739 Partial_Amp_Shutdown "Method Partial_Amp_Shutdown";
CM_ SG_ 739 HMI_HMIMode_St "Object ACU System Master.HMIMode
OR
Object NAV System Master.HMIMode

Refer Method HMIAudioMode in the SPSS";
CM_ BO_ 1009 "APIM Tx";
CM_ SG_ 1009 CenterStackRing_D_Actl "The Center Stack sends the CPLR a signal to turn On or Off the light Ring, This is a customer selectable preference switch";
CM_ SG_ 1009 APIM_NumberofTracks_St "Object NumberofTracks";
CM_ SG_ 1009 APIM_ActiveTrackNum_St "Object.ActiveTrackNum";
CM_ BO_ 531 "IC is NOT to use data in this message for displays, Used data from 415 instead.";
CM_ SG_ 531 VehLongOvrGnd_A_Est "CCMGenSigTimeoutTime=1000";
CM_ SG_ 702 PHONE_MC_WORD_Rx "MM ISO 15765-2 Message Catalogue
Section MC - PHONE";
CM_ SG_ 711 MyKeySrvr_Clnt_Word_Tx "TP-LOG-GTPC-201379-SID-7C";
CM_ BO_ 549 "Method IPC _Infotainment";
CM_ SG_ 549 BeltminderAudioMute "Object.MyKey.BeltMinderAudioMute.St";
CM_ SG_ 549 Power_Up_Chime_Modules "Object.AlertMethod.IPC _Infotainment";
CM_ SG_ 549 Chime_Source "Object.AlertMethod.IPC_infotainment";
CM_ SG_ 765 Mc_VehUntTrpCoUsrSel_St "Object.VehicleSettings.Disp_Miles_Kilometers.Rq";
CM_ SG_ 765 Mc_VehUnitTempUsrSel_St "Object.VehicleSettings.Disp_Temperature.Rq";
CM_ SG_ 765 Mc_VehDayNightUsrSel_St "Object.BodyInterface.Settings.VehicleDayNightUserSelection
Object.BodyInterface.Status.AMDayNightSensitivity";
CM_ SG_ 765 Mc_VehTimeFrmtUsrSel_St "Object.BodyInterface.Settings.VehicleTimeFormatUserSelection";
CM_ SG_ 765 Mc_VehThemeUsrSel_St "Object.BodyInterface.Settings.VehicleThemeUserSelection";
CM_ SG_ 765 Mc_VehLangUsrSel_St "Object.BodyInterface.Settings.VehicleLanguageUserSelection
Object Vehicle Settings.Disp_LangSel
";
CM_ SG_ 508 Mc_DB1GetInfStartInd_Rq "Object Media Player iPod.GetMDBInfo.MDBStartItemInd
";
CM_ SG_ 508 Mc_DB1GtInfNbrOfItms_Rq "Object Media Player iPod.GetMDBInfo.MDBNbrOfItems
";
CM_ SG_ 508 Mc_DB1GetInfSetConf_Rq "Object Media Player iPod.GetMDBInfo.MDBSetFilterConf
";
CM_ SG_ 508 Mc_DB1GetInfSetFilt3_Rq "Object Media Player iPod.GetMDBInfo.MDBSetFilter3
";
CM_ SG_ 508 Mc_DB1GetInfSetFilt2_Rq "Object Media Player iPod.GetMDBInfo.MDBSetFilter2
";
CM_ SG_ 508 Mc_DB1GetInfSetFilt1_Rq "Object Media Player iPod.GetMDBInfo.MDBSetFilter1 ";
CM_ SG_ 507 Mc_DB1SetTrkItmIndex_Rq "Object Media Player iPod.MDBSetTrack.MDBItemIndex
";
CM_ SG_ 507 Mc_DB1SetTrkSetConf_Rq "Object Media Player iPod.MDBSetTrack.MDBSetFilterConf";
CM_ SG_ 507 Mc_DB1SetTrkSetFilt3_Rq "Object Media Player iPod.MDBSetTrack.MDBSetFilter3";
CM_ SG_ 507 Mc_DB1SetTrkSetFilt2_Rq "Object Media Player iPod.MDBSetTrack.MDBSetFilter2";
CM_ SG_ 507 Mc_DB1SetTrkSetFilt1_Rq "Object Media Player iPod.MDBSetTrack.MDBSetFilter1";
CM_ SG_ 506 Mc_AudioSourceSel3_Rq "Object Media Player BTAudio.GetDetailedMPInfo.AudioSource
Object Media Player BTAudio.PlayFirstTrackInFolder.AudioSource
Object Media Player USB.GetDetailedMPInfo.AudioSource
Object Media Player USB.PlayFirstTrackInFolder.AudioSource";
CM_ SG_ 506 Mc_PlayFrstTrInFldr_Rq "Object Media Player BTAudio.PlayFirstTrackInFolder.FolderNumber
Object Media Player USB.PlayFirstTrackinFolder.FolderNumber

$FFFF: Inactive";
CM_ SG_ 506 Mc_ItemIndex_Rq "Object Media Player BTAudio.GetDetailedMPInfo.ItemIndex
Object Media Player USB.GetDetailedMPInfo.ItemIndex";
CM_ SG_ 506 Mc_FolderNumber3_Rq "Object Media Player BTAudio.GetDetailedMPInfo.FolderNumber
Object Media Player USB.GetDetailedMPInfo.FolderNumber";
CM_ SG_ 505 Mc_AudioSourceSel2_Rq "Object Media Player BTAudio.GetMPInfo.AudioSouce
Object Media Player USB.GetMPInfo.AudioSouce
Object Media Player SDCard.GetMPInfo.AudioSouce";
CM_ SG_ 505 Mc_StartItemIndexRq "Object Media Player BTAudio.GetMPInfo.StartingItemIndex
Object Media Player USB.GetMPInfo.StartingItemIndex
Object Media Player SDCard.GetMPInfo.StartingItemIndex

$FFFF: Inactive";
CM_ SG_ 505 Mc_NbrOfItems2_Rq "Object Media Player BTAudio.GetMPInfo.NbrOfItems
Object Media Player USB.GetMPInfo.NbrOfItems
Object Media Player SDCard.GetMPInfo.NbrOfItems";
CM_ SG_ 505 Mc_ItemNameLength2_Rq "Object Media Player BTAudio.GetMPInfo.ItemNameLength
Object Media Player USB.GetMPInfo.ItemNameLength
Object Media Player SDCard.GetMPInfo.ItemNameLength";
CM_ SG_ 505 Mc_CutItem2_Rq "Object Media Player BTAudio.GetMPInfo.CutItemName
Object Media Player USB.GetMPInfo.CutItemName
Object Media Player SDCard.GetMPInfo.CutItemName";
CM_ SG_ 505 Mc_FolderNumber2_Rq "Object Media Player BTAudio.GetMPInfo.FolderNumber 
Object Media Player USB.GetMPInfo.FolderNumber
Object Media Player SDCard.GetMPInfo.FolderNumber

$FFFF: Inactive";
CM_ SG_ 505 Mc_FolderContent_Rq "Object Media Player USB.GetMPInfo.FolderContent
Object Media Player SDCard.GetMPInfo.FolderContent

Note: Value table entries were truncated from:
$0: RequestContentFromParameterFolderNumber
$1: RequestContentFromParentFolderOfParameterFolderNumber";
CM_ SG_ 403 Mc_RepeatGuidance_Rq "Object.NavigationRepeater.Guidance_Repeat.Rq.RepeatGuidance";
CM_ SG_ 403 Mc_CancelRoute_Rq "Object.NavigationRepater.CancelRoute.Rq.CancelRoute";
CM_ SG_ 403 Mc_CancelCurrWaypt_Rq "Object.NavigationRepeater.CancelCurrentWayPoint.Rq.Cancelwaypoint";
CM_ SG_ 403 Mc_TextMessage_Rq "Object. BTPhoneClient.TextMessage.Rq";
CM_ SG_ 403 Mc_BTInCallOptions_Rq "Object.BTPhoneClient.BTInCallOptions.Rq.SingleParam";
CM_ SG_ 403 Mc_PhMicrophoneMute_Rq "Object Blueetoth Phone.PhMicrophoneMute";
CM_ SG_ 403 Mc_LangSel_Rq "Object.VehicleSettings.Disp_LangSel.Rq.Language";
CM_ BO_ 401 "APIM Tx";
CM_ SG_ 401 Bezel_Beeps_Rq "Vehicle Settings";
CM_ SG_ 401 Disp_VehUntTripCoUsrSel "Obect.VehicleSettings.Disp_Miles_Kilometers.Rq.Mode";
CM_ SG_ 401 Disp_VehUnitTempUsrSel "Obect.VehicleSettings.Disp_Temperature.Rq.Mode";
CM_ SG_ 401 Disp_LangSel_Rq "Object.VehicleSettings.Disp_LangSel.Rq.Language";
CM_ SG_ 401 Disp_LangSel2_Rq "Reference GSDB for encoding: 009522/B;2-ZZ_LangSel";
CM_ BO_ 947 "Reserve InfoCAN Legacy signals from $3B3";
CM_ SG_ 947 Outside_Air_Temp_Stat "Filtered value, i.e. same as disply for customer";
CM_ SG_ 405 LBC1_StartItemInd "Object. ListBrowser.ItemInf.Rq.StartItemInd
0x0000:Inactive
0x0001:1
0xFFFE:65634
0xFFFF:Reserved";
CM_ SG_ 405 LBC1_SetListServ "Object. ListBrowser.ItemInf.Rq.SetListServ
0x00:Inactive
0x01:ServerID_1
0xFF:ALL";
CM_ SG_ 405 LBC1_Opcode "Object. ListBrowser.ItemInf.Rq.Opcode";
CM_ SG_ 405 LBC1_NbrOfItems "Object. ListBrowser.ItemInf.Rq.NbrOfItems
0x00:Inactive
0x01:1Item
0x3F:63Items";
CM_ SG_ 405 LBC1_ItemIndex "Object. ListBrowser.ItemInf.Rq.ItemIndex
0x0000:BrowseActiveListID
0x0001:EntryIndex_1
0xFFFF:ParentOfActiveListID";
CM_ SG_ 405 LBC1_ActiveListID "Object. ListBrowser.ItemInf.Rq.ActiveListID
0x0000:Root
0xFFFF:Reserved";
CM_ BO_ 756 "IPC_Chime2";
CM_ SG_ 756 Off_Time_Btwn_Chime2 "Object.AlertMethod.IPC_Chime
0x0 Inactive
0x1 Continuously (repeat continuously) 
0x2 5 msec
0x3 10 msec
0x4 15 msec
0x5 20 msec
0x6 40 msec
0x7 60 msec (increment is 20 msec steps until 800 msec)
cont....Refer SPSS for rest of encodings";
CM_ SG_ 756 Chime_Vol_Level2 "Object.AlertMethod. IPC_Chime
0x0 Inactive (no change to stored chime volume - 100% of stored chime volume)
0x1 99% (of stored chime volume)
....
0x63 1% (of stored chime volume)
0x64 Reserved";
CM_ SG_ 756 Chime_Time_Criticality2 "Object.AlertMethod. IPC_Chime";
CM_ SG_ 756 Chime_Occurence2 "Object.AlertMethod. IPC_Chime";
CM_ SG_ 756 Chime_Directionality2 "Object.AlertMethod. IPC_Chime";
CM_ SG_ 756 Chime2 "Object.AlertMethod. IPC_Chime
0x0 No_Chime  (note: if >No Chime< is selected then ignore other signals in this message)
0x1 Chime_1
0x2 Chime_2
0x3 Chime_3
cont.
0x3F Chime_63

";
CM_ BO_ 544 "Method IPC_Chime";
CM_ SG_ 544 Chime_Occurence "Object.AlertMethod. IPC_Chime";
CM_ SG_ 544 Off_Time_Btwn_Chime "Object.AlertMethod.IPC_Chime
0x0 Inactive
0x1 Continuously (repeat continuously) 
0x2 5 msec
0x3 10 msec
0x4 15 msec
0x5 20 msec
0x6 40 msec
0x7 60 msec (increment is 20 msec steps until 800 msec)
cont....Refer SPSS for rest of the encodings.
";
CM_ SG_ 544 Chime_Time_Criticality "Object.AlertMethod. IPC_Chime";
CM_ SG_ 544 Chime_Directionality "Object.AlertMethod. IPC_Chime";
CM_ SG_ 544 Chime_Vol_Level "Object.AlertMethod. IPC_Chime
0x0 Inactive (no change to stored chime volume - 100% of stored chime volume)
0x1 99% (of stored chime volume)
....
0x63 1% (of stored chime volume)
0x64 Reserved";
CM_ SG_ 544 Chime "Object.AlertMethod. IPC_Chime
0x0 No_Chime  (note: if >No Chime< is selected then ignore other signals in this message)
0x1 Chime_1
0x2 Chime_2
0x3 Chime_3
cont.
0x3F Chime_63
";
CM_ SG_ 291 LangUpdate_Rsp "Object. LanguageUpdate.Rsp";
CM_ SG_ 400 Mc_SetCurrStatMCCh_Rq "Object Tuner.SetCurrentStation.MCChannel";
CM_ SG_ 400 Mc_SetCurrntStatFreq_Rq "Object Tuner.SetCurrentStat.Request.Frequency

AM: Freq = 153+ Offset kHz.
Offset 0..1557

FM: Freq = 76+ Offset*0.05 MHz. Offset 0..640
Selected tuned band determine frequency (kHz or MHz).";
CM_ SG_ 400 Mc_SetCurrentStatOp_Rq "Object Tuner.SetCurrentStat.Request.Operation";
CM_ SG_ 400 Mc_PerTUStartIndex2_Rq "Object Personalization. DAB.GetTUPresetInfo.StartIndex2

$1-$FF: Preset 1 to 255";
CM_ SG_ 400 Mc_PerTUPresetArea_Rq "Object Personalization.DAB.GetTUPresetInfo.PresetArea

$5: Get AMAST (MW) Preset Data
$6: Get AM (LW) Preset Data";
CM_ SG_ 400 Mc_PerTUNbrOfPresets_Rq "Object Personalization. DAB.GetTUPresetInfo.NumberOfPresets

$1-$1E: Preset 1 to 30";
CM_ SG_ 647 HEC_BTIncomingCall_Rq "Object Bluetooth Phone.BTIncomingCall";
CM_ SG_ 647 HEC_BTEndTelService_Rq "Object Bluetooth Phone.BTEndTelService";
BA_DEF_ BO_  "FrameRouting" STRING ;
BA_DEF_ BO_  "FrameGatewayNetwork" STRING ;
BA_DEF_ BO_  "NetworkInitialization" ENUM  "No","Yes";
BA_DEF_ BO_  "FrameGatewayId" HEX 0 1407;
BA_DEF_ BO_  "EventRateOfChange" INT 10 10000;
BA_DEF_ BO_  "GenMsgStartDelayTime" INT 0 10000;
BA_DEF_ BO_  "GenMsgNrOfRepetition" INT 0 100;
BA_DEF_ BO_  "GenMsgDelayTime" INT 0 1000;
BA_DEF_ BO_  "GenMsgCycleTime" INT 0 100000;
BA_DEF_ BO_  "GenMsgSendType" ENUM  "FixedPeriodic","Event","EnabledPeriodic","NotUsed","NotUsed","EventPeriodic","NotUsed","NotUsed","NoMsgSendType";
BA_DEF_ SG_  "U_U55X_MY2022_Tx" ENUM  "No","Yes";
BA_DEF_ SG_  "U_CD542_MY2021_Tx" ENUM  "No","Yes";
BA_DEF_ SG_  "ECGUsedTxSignal" ENUM  "No","Yes";
BA_DEF_ SG_  "U_T6_MCA_MY2020_Tx" ENUM  "No","Yes";
BA_DEF_ SG_  "U_P702_MY2021_Tx" ENUM  "No","Yes";
BA_DEF_ SG_  "U_CX727_MY2021_Tx" ENUM  "No","Yes";
BA_DEF_ SG_  "U_FNV2_IVI_Rx" ENUM  "No","Yes";
BA_DEF_ SG_  "U_U55X_MY2022_Rx" ENUM  "No","Yes";
BA_DEF_ SG_  "U_CD542_MY2021_Rx" ENUM  "No","Yes";
BA_DEF_ SG_  "ECGUsedRxSignal" ENUM  "No","Yes";
BA_DEF_ SG_  "U_T6_MCA_MY2020_Rx" ENUM  "No","Yes";
BA_DEF_ SG_  "U_P702_MY2021_Rx" ENUM  "No","Yes";
BA_DEF_ SG_  "U_CX727_MY2021_Rx" ENUM  "No","Yes";
BA_DEF_ SG_  "GenSigStartValue" HEX 0 268435455;
BA_DEF_ SG_  "MetaData" ENUM  "No","Yes";
BA_DEF_ SG_  "ContentDependant" ENUM  "No","Yes";
BA_DEF_ SG_  "GenSigStartValueInteger" INT 0 1000000000;
BA_DEF_ SG_  "UsedOnPgmDBC" ENUM  "No","Yes";
BA_DEF_ SG_  "WakeupSignal" ENUM  "No","Yes";
BA_DEF_ SG_  "GenSigInactiveValue" INT 0 100000;
BA_DEF_ SG_  "GenSigSendType" ENUM  "Cyclic","OnWrite","vector_leerstring","OnChange","vector_leerstring","IfActive","vector_leerstring","NoSigSendType";
BA_DEF_ BO_  "OvtpPushApplication" ENUM  "FALSE","TRUE";
BA_DEF_ BO_  "SCP_FreshnessValueLength" INT 0 512;
BA_DEF_ BO_  "SCP_FreshnessValueTxLength" INT 0 512;
BA_DEF_ BO_  "SCP_AuthInfoTxLength" INT 0 512;
BA_DEF_ BO_  "GenMsgRoutingTimeoutTime" INT 0 5000;
BA_DEF_ BO_  "MessageGateway" ENUM  "No","Yes";
BA_DEF_ BO_  "NmAsrMessage" ENUM  "No","Yes";
BA_DEF_ BO_  "DiagState" ENUM  "No","Yes";
BA_DEF_ BO_  "TpTxIndex" INT 0 536870911;
BA_DEF_ BO_  "DiagRequest" ENUM  "No","Yes";
BA_DEF_ BO_  "DiagResponse" ENUM  "No","Yes";
BA_DEF_ BO_  "GenMsgILSupport" ENUM  "No","Yes";
BA_DEF_DEF_  "FrameRouting" "";
BA_DEF_DEF_  "FrameGatewayNetwork" "NONE";
BA_DEF_DEF_  "NetworkInitialization" "Yes";
BA_DEF_DEF_  "FrameGatewayId" 0;
BA_DEF_DEF_  "EventRateOfChange" 10000;
BA_DEF_DEF_  "GenMsgStartDelayTime" 0;
BA_DEF_DEF_  "GenMsgNrOfRepetition" 1;
BA_DEF_DEF_  "GenMsgDelayTime" 20;
BA_DEF_DEF_  "GenMsgCycleTime" 0;
BA_DEF_DEF_  "GenMsgSendType" "NoMsgSendType";
BA_DEF_DEF_  "U_U55X_MY2022_Tx" "No";
BA_DEF_DEF_  "U_CD542_MY2021_Tx" "No";
BA_DEF_DEF_  "ECGUsedTxSignal" "No";
BA_DEF_DEF_  "U_T6_MCA_MY2020_Tx" "No";
BA_DEF_DEF_  "U_P702_MY2021_Tx" "No";
BA_DEF_DEF_  "U_CX727_MY2021_Tx" "No";
BA_DEF_DEF_  "U_FNV2_IVI_Rx" "No";
BA_DEF_DEF_  "U_U55X_MY2022_Rx" "No";
BA_DEF_DEF_  "U_CD542_MY2021_Rx" "No";
BA_DEF_DEF_  "ECGUsedRxSignal" "No";
BA_DEF_DEF_  "U_T6_MCA_MY2020_Rx" "No";
BA_DEF_DEF_  "U_P702_MY2021_Rx" "No";
BA_DEF_DEF_  "U_CX727_MY2021_Rx" "No";
BA_DEF_DEF_  "GenSigStartValue" 0;
BA_DEF_DEF_  "MetaData" "No";
BA_DEF_DEF_  "ContentDependant" "No";
BA_DEF_DEF_  "GenSigStartValueInteger" 0;
BA_DEF_DEF_  "UsedOnPgmDBC" "Yes";
BA_DEF_DEF_  "WakeupSignal" "No";
BA_DEF_DEF_  "GenSigInactiveValue" 0;
BA_DEF_DEF_  "GenSigSendType" "NoSigSendType";
BA_DEF_DEF_  "OvtpPushApplication" "FALSE";
BA_DEF_DEF_  "SCP_FreshnessValueLength" 64;
BA_DEF_DEF_  "SCP_FreshnessValueTxLength" 11;
BA_DEF_DEF_  "SCP_AuthInfoTxLength" 53;
BA_DEF_DEF_  "GenMsgRoutingTimeoutTime" 0;
BA_DEF_DEF_  "MessageGateway" "No";
BA_DEF_DEF_  "NmAsrMessage" "No";
BA_DEF_DEF_  "DiagState" "No";
BA_DEF_DEF_  "TpTxIndex" 0;
BA_DEF_DEF_  "DiagRequest" "No";
BA_DEF_DEF_  "DiagResponse" "No";
BA_DEF_DEF_  "GenMsgILSupport" "Yes";
BA_ "FrameRouting" BO_ 1056 "FD1_CAN,0x420;";
BA_ "FrameGatewayNetwork" BO_ 1056 "FD1_CAN";
BA_ "FrameGatewayId" BO_ 1056 1056;
BA_ "GenMsgCycleTime" BO_ 1060 1000;
BA_ "GenMsgSendType" BO_ 1060 5;
BA_ "GenMsgRoutingTimeoutTime" BO_ 1060 300;
BA_ "MessageGateway" BO_ 1060 1;
BA_ "GenMsgDelayTime" BO_ 118 10;
BA_ "GenMsgCycleTime" BO_ 118 20;
BA_ "GenMsgSendType" BO_ 118 0;
BA_ "FrameRouting" BO_ 132 "HS1_CAN,0x84;";
BA_ "FrameGatewayNetwork" BO_ 132 "HS1_CAN";
BA_ "FrameGatewayId" BO_ 132 132;
BA_ "GenMsgSendType" BO_ 135 1;
BA_ "GenMsgSendType" BO_ 134 1;
BA_ "GenMsgCycleTime" BO_ 766 1000;
BA_ "GenMsgSendType" BO_ 766 5;
BA_ "GenMsgCycleTime" BO_ 838 100;
BA_ "GenMsgSendType" BO_ 838 0;
BA_ "GenMsgSendType" BO_ 559 1;
BA_ "GenMsgSendType" BO_ 558 1;
BA_ "FrameRouting" BO_ 939 "FD1_CAN,0x3AB;HS2_CAN,0x3AB";
BA_ "FrameRouting" BO_ 938 "FD1_CAN,0x3AA;HS2_CAN,0x3AA";
BA_ "FrameRouting" BO_ 952 "HS1_CAN,0x3B8;";
BA_ "FrameGatewayNetwork" BO_ 952 "HS1_CAN";
BA_ "FrameGatewayId" BO_ 952 952;
BA_ "FrameRouting" BO_ 845 "MS1_CAN,0x34D;";
BA_ "FrameGatewayNetwork" BO_ 845 "MS1_CAN";
BA_ "FrameGatewayId" BO_ 845 845;
BA_ "FrameRouting" BO_ 1137 "FD1_CAN,0x471;HS1_CAN,0x471";
BA_ "GenMsgCycleTime" BO_ 1073 1000;
BA_ "GenMsgSendType" BO_ 1073 5;
BA_ "FrameRouting" BO_ 844 "MS1_CAN,0x34C;";
BA_ "FrameGatewayNetwork" BO_ 844 "MS1_CAN";
BA_ "FrameGatewayId" BO_ 844 844;
BA_ "FrameRouting" BO_ 843 "MS1_CAN,0x34B;";
BA_ "FrameGatewayNetwork" BO_ 843 "MS1_CAN";
BA_ "FrameGatewayId" BO_ 843 843;
BA_ "FrameRouting" BO_ 842 "MS1_CAN,0x34A;";
BA_ "FrameGatewayNetwork" BO_ 842 "MS1_CAN";
BA_ "FrameGatewayId" BO_ 842 842;
BA_ "GenMsgCycleTime" BO_ 846 1000;
BA_ "GenMsgSendType" BO_ 846 5;
BA_ "FrameRouting" BO_ 935 "FD1_CAN,0x3A7;MS1_CAN,0x3A7";
BA_ "FrameRouting" BO_ 934 "FD1_CAN,0x3A6;MS1_CAN,0x3A6";
BA_ "GenMsgSendType" BO_ 486 1;
BA_ "GenMsgCycleTime" BO_ 553 1000;
BA_ "GenMsgSendType" BO_ 553 5;
BA_ "GenMsgCycleTime" BO_ 739 1000;
BA_ "GenMsgSendType" BO_ 739 5;
BA_ "GenMsgCycleTime" BO_ 1009 1000;
BA_ "GenMsgSendType" BO_ 1009 5;
BA_ "FrameRouting" BO_ 531 "FD1_CAN,0x213;";
BA_ "FrameGatewayNetwork" BO_ 531 "FD1_CAN";
BA_ "FrameGatewayId" BO_ 531 531;
BA_ "GenMsgRoutingTimeoutTime" BO_ 531 60;
BA_ "MessageGateway" BO_ 531 1;
BA_ "TpTxIndex" BO_ 702 17;
BA_ "TpTxIndex" BO_ 711 24;
BA_ "GenMsgCycleTime" BO_ 549 1000;
BA_ "GenMsgSendType" BO_ 549 5;
BA_ "GenMsgCycleTime" BO_ 765 1000;
BA_ "GenMsgSendType" BO_ 765 5;
BA_ "GenMsgSendType" BO_ 508 1;
BA_ "GenMsgSendType" BO_ 507 1;
BA_ "GenMsgSendType" BO_ 506 1;
BA_ "GenMsgSendType" BO_ 505 1;
BA_ "GenMsgSendType" BO_ 403 1;
BA_ "GenMsgSendType" BO_ 401 1;
BA_ "FrameRouting" BO_ 1143 "FD1_CAN,0x477;HS1_CAN,0x477";
BA_ "FrameRouting" BO_ 1142 "FD1_CAN,0x476;HS1_CAN,0x476";
BA_ "GenMsgCycleTime" BO_ 947 1000;
BA_ "GenMsgSendType" BO_ 947 5;
BA_ "FrameRouting" BO_ 973 "FD1_CAN,0x3CD;HS2_CAN,0x3CD";
BA_ "GenMsgSendType" BO_ 405 1;
BA_ "GenMsgCycleTime" BO_ 756 1000;
BA_ "GenMsgSendType" BO_ 756 5;
BA_ "GenMsgCycleTime" BO_ 544 1000;
BA_ "GenMsgSendType" BO_ 544 5;
BA_ "GenMsgSendType" BO_ 291 1;
BA_ "GenMsgSendType" BO_ 400 1;
BA_ "GenMsgCycleTime" BO_ 647 200;
BA_ "GenMsgSendType" BO_ 647 5;
BA_ "U_CD542_MY2021_Rx" SG_ 1056 AutoEpbButtnOn_B_Stat 1;
BA_ "U_T6_MCA_MY2020_Rx" SG_ 1056 AutoEpbButtnOn_B_Stat 1;
BA_ "U_CD542_MY2021_Rx" SG_ 1056 AutoEpbMsgTxt_D_Rq 1;
BA_ "U_T6_MCA_MY2020_Rx" SG_ 1056 AutoEpbMsgTxt_D_Rq 1;
BA_ "U_CD542_MY2021_Rx" SG_ 1056 AutoEpbDsply_D_Stat 1;
BA_ "U_T6_MCA_MY2020_Rx" SG_ 1056 AutoEpbDsply_D_Stat 1;
BA_ "U_CD542_MY2021_Rx" SG_ 1056 SelDrvMdePos12_B_Avail 1;
BA_ "U_P702_MY2021_Rx" SG_ 1056 SelDrvMdePos12_B_Avail 1;
BA_ "U_T6_MCA_MY2020_Rx" SG_ 1056 SelDrvMdePos12_B_Avail 1;
BA_ "U_CD542_MY2021_Rx" SG_ 1056 SelDrvMdePos11_B_Avail 1;
BA_ "U_T6_MCA_MY2020_Rx" SG_ 1056 SelDrvMdePos11_B_Avail 1;
BA_ "U_P702_MY2021_Rx" SG_ 1056 SelDrvMdePos11_B_Avail 1;
BA_ "U_CD542_MY2021_Rx" SG_ 1056 SelDrvMdePos10_B_Avail 1;
BA_ "U_T6_MCA_MY2020_Rx" SG_ 1056 SelDrvMdePos10_B_Avail 1;
BA_ "U_P702_MY2021_Rx" SG_ 1056 SelDrvMdePos10_B_Avail 1;
BA_ "U_CD542_MY2021_Rx" SG_ 1056 SelDrvMdePos09_B_Avail 1;
BA_ "U_T6_MCA_MY2020_Rx" SG_ 1056 SelDrvMdePos09_B_Avail 1;
BA_ "U_P702_MY2021_Rx" SG_ 1056 SelDrvMdePos09_B_Avail 1;
BA_ "U_CD542_MY2021_Rx" SG_ 1056 SelDrvMdePos08_B_Avail 1;
BA_ "U_T6_MCA_MY2020_Rx" SG_ 1056 SelDrvMdePos08_B_Avail 1;
BA_ "U_P702_MY2021_Rx" SG_ 1056 SelDrvMdePos08_B_Avail 1;
BA_ "U_CD542_MY2021_Rx" SG_ 1056 SelDrvMdePos07_B_Avail 1;
BA_ "U_T6_MCA_MY2020_Rx" SG_ 1056 SelDrvMdePos07_B_Avail 1;
BA_ "U_P702_MY2021_Rx" SG_ 1056 SelDrvMdePos07_B_Avail 1;
BA_ "U_CD542_MY2021_Rx" SG_ 1056 SelDrvMdePos06_B_Avail 1;
BA_ "U_T6_MCA_MY2020_Rx" SG_ 1056 SelDrvMdePos06_B_Avail 1;
BA_ "U_P702_MY2021_Rx" SG_ 1056 SelDrvMdePos06_B_Avail 1;
BA_ "U_CD542_MY2021_Rx" SG_ 1056 SelDrvMdePos05_B_Avail 1;
BA_ "U_T6_MCA_MY2020_Rx" SG_ 1056 SelDrvMdePos05_B_Avail 1;
BA_ "U_P702_MY2021_Rx" SG_ 1056 SelDrvMdePos05_B_Avail 1;
BA_ "U_CD542_MY2021_Rx" SG_ 1056 SelDrvMdePos04_B_Avail 1;
BA_ "U_T6_MCA_MY2020_Rx" SG_ 1056 SelDrvMdePos04_B_Avail 1;
BA_ "U_P702_MY2021_Rx" SG_ 1056 SelDrvMdePos04_B_Avail 1;
BA_ "U_CD542_MY2021_Rx" SG_ 1056 SelDrvMdePos03_B_Avail 1;
BA_ "U_T6_MCA_MY2020_Rx" SG_ 1056 SelDrvMdePos03_B_Avail 1;
BA_ "U_P702_MY2021_Rx" SG_ 1056 SelDrvMdePos03_B_Avail 1;
BA_ "U_CD542_MY2021_Rx" SG_ 1056 SelDrvMdePos02_B_Avail 1;
BA_ "U_T6_MCA_MY2020_Rx" SG_ 1056 SelDrvMdePos02_B_Avail 1;
BA_ "U_P702_MY2021_Rx" SG_ 1056 SelDrvMdePos02_B_Avail 1;
BA_ "U_CD542_MY2021_Rx" SG_ 1056 SelDrvMdePos01_B_Avail 1;
BA_ "U_T6_MCA_MY2020_Rx" SG_ 1056 SelDrvMdePos01_B_Avail 1;
BA_ "U_P702_MY2021_Rx" SG_ 1056 SelDrvMdePos01_B_Avail 1;
BA_ "U_P702_MY2021_Rx" SG_ 1056 ActvDrvMde_D2_Stat 1;
BA_ "U_CD542_MY2021_Rx" SG_ 1056 ActvDrvMde_D2_Stat 1;
BA_ "U_T6_MCA_MY2020_Rx" SG_ 1056 ActvDrvMde_D2_Stat 1;
BA_ "GenSigStartValue" SG_ 1056 ActvDrvMde_D2_Stat 31;
BA_ "GenSigStartValueInteger" SG_ 1056 ActvDrvMde_D2_Stat 31;
BA_ "U_CD542_MY2021_Rx" SG_ 1056 SelDrvMde_D2_Rq 1;
BA_ "U_T6_MCA_MY2020_Rx" SG_ 1056 SelDrvMde_D2_Rq 1;
BA_ "U_P702_MY2021_Rx" SG_ 1056 SelDrvMde_D2_Rq 1;
BA_ "GenSigStartValue" SG_ 1056 SelDrvMde_D2_Rq 31;
BA_ "GenSigStartValueInteger" SG_ 1056 SelDrvMde_D2_Rq 31;
BA_ "GenSigStartValue" SG_ 1056 AwdMde_D_RqBrk 5;
BA_ "GenSigStartValueInteger" SG_ 1056 AwdMde_D_RqBrk 5;
BA_ "U_T6_MCA_MY2020_Rx" SG_ 1056 SelDrvMdeMsgTxt2_D_Rq 1;
BA_ "U_CD542_MY2021_Rx" SG_ 1056 SelDrvMdeMsgTxt_D_Rq 1;
BA_ "U_T6_MCA_MY2020_Rx" SG_ 1056 SelDrvMdeMsgTxt_D_Rq 1;
BA_ "U_P702_MY2021_Rx" SG_ 1056 SelDrvMdeMsgTxt_D_Rq 1;
BA_ "U_CD542_MY2021_Rx" SG_ 1056 SelDrvMde_D_Stat 1;
BA_ "U_T6_MCA_MY2020_Rx" SG_ 1056 SelDrvMde_D_Stat 1;
BA_ "U_P702_MY2021_Rx" SG_ 1056 SelDrvMde_D_Stat 1;
BA_ "U_CD542_MY2021_Rx" SG_ 1060 FuelLvl_Pc_DsplyEng 1;
BA_ "U_T6_MCA_MY2020_Rx" SG_ 1060 FuelLvl_Pc_DsplyEng 1;
BA_ "U_P702_MY2021_Rx" SG_ 1060 FuelLvl_Pc_DsplyEng 1;
BA_ "GenSigStartValueInteger" SG_ 1060 FuelLvl_Pc_DsplyEng 48;
BA_ "U_CD542_MY2021_Rx" SG_ 1060 FuelLvlWarn_D_ActlEng 1;
BA_ "U_T6_MCA_MY2020_Rx" SG_ 1060 FuelLvlWarn_D_ActlEng 1;
BA_ "U_P702_MY2021_Rx" SG_ 1060 FuelLvlWarn_D_ActlEng 1;
BA_ "GenSigSendType" SG_ 1060 FuelLvlWarn_D_ActlEng 3;
BA_ "U_CD542_MY2021_Rx" SG_ 1060 FuelRange_L_DsplyEng 1;
BA_ "U_T6_MCA_MY2020_Rx" SG_ 1060 FuelRange_L_DsplyEng 1;
BA_ "U_P702_MY2021_Rx" SG_ 1060 FuelRange_L_DsplyEng 1;
BA_ "U_CD542_MY2021_Rx" SG_ 1060 RearDiffOilTeWarn_B_Rq 1;
BA_ "U_T6_MCA_MY2020_Rx" SG_ 1060 RearDiffOilTeWarn_B_Rq 1;
BA_ "GenSigSendType" SG_ 1060 RearDiffOilTeWarn_B_Rq 3;
BA_ "U_CD542_MY2021_Rx" SG_ 1060 EngMxTqCurr_Pc_Dsply 1;
BA_ "U_T6_MCA_MY2020_Rx" SG_ 1060 EngMxTqCurr_Pc_Dsply 1;
BA_ "U_P702_MY2021_Rx" SG_ 1060 EngExhMdeQuiet_D_Stat 1;
BA_ "U_CD542_MY2021_Rx" SG_ 1060 EngExhMdeQuiet_D_Stat 1;
BA_ "U_T6_MCA_MY2020_Rx" SG_ 1060 EngExhMdeQuiet_D_Stat 1;
BA_ "GenSigSendType" SG_ 1060 EngExhMdeQuiet_D_Stat 3;
BA_ "GenSigStartValue" SG_ 1060 EngExhMdeQuiet_D_Stat 2;
BA_ "GenSigStartValueInteger" SG_ 1060 EngExhMdeQuiet_D_Stat 2;
BA_ "U_P702_MY2021_Rx" SG_ 1060 RearDiffOil_Te_Actl 1;
BA_ "U_CD542_MY2021_Rx" SG_ 1060 RearDiffOil_Te_Actl 1;
BA_ "U_T6_MCA_MY2020_Rx" SG_ 1060 RearDiffOil_Te_Actl 1;
BA_ "GenSigStartValue" SG_ 1060 RearDiffOil_Te_Actl 77;
BA_ "GenSigStartValueInteger" SG_ 1060 RearDiffOil_Te_Actl 77;
BA_ "U_CD542_MY2021_Rx" SG_ 1060 BpedDrvMsgTxt_B_Dsply 1;
BA_ "U_T6_MCA_MY2020_Rx" SG_ 1060 BpedDrvMsgTxt_B_Dsply 1;
BA_ "U_P702_MY2021_Rx" SG_ 1060 BpedDrvMsgTxt_B_Dsply 1;
BA_ "GenSigSendType" SG_ 1060 BpedDrvMsgTxt_B_Dsply 3;
BA_ "GenSigSendType" SG_ 1060 SelDrvMdePt_D_Stat 3;
BA_ "U_T6_MCA_MY2020_Rx" SG_ 118 StePinCompAnEst_D_Qf 1;
BA_ "U_P702_MY2021_Rx" SG_ 118 StePinCompAnEst_D_Qf 1;
BA_ "GenSigStartValue" SG_ 118 StePinCompAnEst_D_Qf 1;
BA_ "GenSigStartValueInteger" SG_ 118 StePinCompAnEst_D_Qf 1;
BA_ "U_T6_MCA_MY2020_Rx" SG_ 118 StePinComp_An_Est_UB 1;
BA_ "U_P702_MY2021_Rx" SG_ 118 StePinComp_An_Est_UB 1;
BA_ "U_T6_MCA_MY2020_Rx" SG_ 118 StePinComp_An_Est 1;
BA_ "U_P702_MY2021_Rx" SG_ 118 StePinComp_An_Est 1;
BA_ "GenSigStartValueInteger" SG_ 118 StePinComp_An_Est 16000;
BA_ "U_P702_MY2021_Rx" SG_ 118 SteWhlComp_An_Est_UB 1;
BA_ "U_CD542_MY2021_Rx" SG_ 118 SteWhlComp_An_Est_UB 1;
BA_ "U_T6_MCA_MY2020_Rx" SG_ 118 SteWhlComp_An_Est_UB 1;
BA_ "U_CD542_MY2021_Rx" SG_ 118 SteWhlCompAnEst_D_Qf 1;
BA_ "U_T6_MCA_MY2020_Rx" SG_ 118 SteWhlCompAnEst_D_Qf 1;
BA_ "MetaData" SG_ 118 SteWhlCompAnEst_D_Qf 1;
BA_ "ContentDependant" SG_ 118 SteWhlCompAnEst_D_Qf 1;
BA_ "U_P702_MY2021_Rx" SG_ 118 SteWhlComp_An_Est 1;
BA_ "U_CD542_MY2021_Rx" SG_ 118 SteWhlComp_An_Est 1;
BA_ "U_T6_MCA_MY2020_Rx" SG_ 118 SteWhlComp_An_Est 1;
BA_ "ContentDependant" SG_ 118 SteWhlComp_An_Est 1;
BA_ "U_CD542_MY2021_Rx" SG_ 118 WiprFront_D_Stat_UB 1;
BA_ "U_T6_MCA_MY2020_Rx" SG_ 118 WiprFront_D_Stat_UB 1;
BA_ "U_P702_MY2021_Rx" SG_ 118 WiprFront_D_Stat_UB 1;
BA_ "U_CD542_MY2021_Rx" SG_ 118 WiprFront_D_Stat 1;
BA_ "U_T6_MCA_MY2020_Rx" SG_ 118 WiprFront_D_Stat 1;
BA_ "U_P702_MY2021_Rx" SG_ 118 WiprFront_D_Stat 1;
BA_ "GenSigStartValue" SG_ 118 WiprFront_D_Stat 15;
BA_ "GenSigStartValueInteger" SG_ 118 WiprFront_D_Stat 15;
BA_ "U_CD542_MY2021_Rx" SG_ 132 GlblClkYr_No_Actl 1;
BA_ "U_T6_MCA_MY2020_Rx" SG_ 132 GlblClkYr_No_Actl 1;
BA_ "U_P702_MY2021_Rx" SG_ 132 GlblClkYr_No_Actl 1;
BA_ "U_P702_MY2021_Rx" SG_ 132 GlblClkScnd_No_Actl 1;
BA_ "U_CD542_MY2021_Rx" SG_ 132 GlblClkScnd_No_Actl 1;
BA_ "U_T6_MCA_MY2020_Rx" SG_ 132 GlblClkScnd_No_Actl 1;
BA_ "U_P702_MY2021_Rx" SG_ 132 GlblClkMnte_No_Actl 1;
BA_ "U_CD542_MY2021_Rx" SG_ 132 GlblClkMnte_No_Actl 1;
BA_ "U_T6_MCA_MY2020_Rx" SG_ 132 GlblClkMnte_No_Actl 1;
BA_ "U_P702_MY2021_Rx" SG_ 132 GlblClkHr_No_Actl 1;
BA_ "U_CD542_MY2021_Rx" SG_ 132 GlblClkHr_No_Actl 1;
BA_ "U_T6_MCA_MY2020_Rx" SG_ 132 GlblClkHr_No_Actl 1;
BA_ "U_CD542_MY2021_Rx" SG_ 132 GlblClkDay_No_Actl 1;
BA_ "U_T6_MCA_MY2020_Rx" SG_ 132 GlblClkDay_No_Actl 1;
BA_ "U_P702_MY2021_Rx" SG_ 132 GlblClkDay_No_Actl 1;
BA_ "U_CD542_MY2021_Tx" SG_ 135 McGlblClkDay_No_Rq 1;
BA_ "U_T6_MCA_MY2020_Tx" SG_ 135 McGlblClkDay_No_Rq 1;
BA_ "WakeupSignal" SG_ 135 McGlblClkDay_No_Rq 1;
BA_ "U_CD542_MY2021_Tx" SG_ 135 McGlblClkYr_No_Rq 1;
BA_ "U_T6_MCA_MY2020_Tx" SG_ 135 McGlblClkYr_No_Rq 1;
BA_ "WakeupSignal" SG_ 135 McGlblClkYr_No_Rq 1;
BA_ "U_CD542_MY2021_Tx" SG_ 135 McGlblClkScnd_No_Rq 1;
BA_ "U_T6_MCA_MY2020_Tx" SG_ 135 McGlblClkScnd_No_Rq 1;
BA_ "WakeupSignal" SG_ 135 McGlblClkScnd_No_Rq 1;
BA_ "U_CD542_MY2021_Tx" SG_ 135 McGlblClkMnte_No_Rq 1;
BA_ "U_T6_MCA_MY2020_Tx" SG_ 135 McGlblClkMnte_No_Rq 1;
BA_ "WakeupSignal" SG_ 135 McGlblClkMnte_No_Rq 1;
BA_ "U_CD542_MY2021_Tx" SG_ 135 McGlblClkHr_No_Rq 1;
BA_ "U_T6_MCA_MY2020_Tx" SG_ 135 McGlblClkHr_No_Rq 1;
BA_ "WakeupSignal" SG_ 135 McGlblClkHr_No_Rq 1;
BA_ "U_CD542_MY2021_Tx" SG_ 135 McGlblClkAdj_B_Rq 1;
BA_ "U_T6_MCA_MY2020_Tx" SG_ 135 McGlblClkAdj_B_Rq 1;
BA_ "GenSigSendType" SG_ 135 McGlblClkAdj_B_Rq 3;
BA_ "WakeupSignal" SG_ 135 McGlblClkAdj_B_Rq 1;
BA_ "U_CD542_MY2021_Tx" SG_ 134 DispGlblClkYr_No_Rq 1;
BA_ "U_T6_MCA_MY2020_Tx" SG_ 134 DispGlblClkYr_No_Rq 1;
BA_ "U_P702_MY2021_Tx" SG_ 134 DispGlblClkYr_No_Rq 1;
BA_ "U_CD542_MY2021_Rx" SG_ 134 DispGlblClkYr_No_Rq 1;
BA_ "U_T6_MCA_MY2020_Rx" SG_ 134 DispGlblClkYr_No_Rq 1;
BA_ "WakeupSignal" SG_ 134 DispGlblClkYr_No_Rq 1;
BA_ "U_CD542_MY2021_Tx" SG_ 134 DispGlblClkScnd_No_Rq 1;
BA_ "U_T6_MCA_MY2020_Tx" SG_ 134 DispGlblClkScnd_No_Rq 1;
BA_ "U_P702_MY2021_Tx" SG_ 134 DispGlblClkScnd_No_Rq 1;
BA_ "U_CD542_MY2021_Rx" SG_ 134 DispGlblClkScnd_No_Rq 1;
BA_ "U_T6_MCA_MY2020_Rx" SG_ 134 DispGlblClkScnd_No_Rq 1;
BA_ "WakeupSignal" SG_ 134 DispGlblClkScnd_No_Rq 1;
BA_ "U_CD542_MY2021_Tx" SG_ 134 DispGlblClkMnte_No_Rq 1;
BA_ "U_T6_MCA_MY2020_Tx" SG_ 134 DispGlblClkMnte_No_Rq 1;
BA_ "U_P702_MY2021_Tx" SG_ 134 DispGlblClkMnte_No_Rq 1;
BA_ "U_CD542_MY2021_Rx" SG_ 134 DispGlblClkMnte_No_Rq 1;
BA_ "U_T6_MCA_MY2020_Rx" SG_ 134 DispGlblClkMnte_No_Rq 1;
BA_ "WakeupSignal" SG_ 134 DispGlblClkMnte_No_Rq 1;
BA_ "U_CD542_MY2021_Tx" SG_ 134 DispGlblClkHr_No_Rq 1;
BA_ "U_T6_MCA_MY2020_Tx" SG_ 134 DispGlblClkHr_No_Rq 1;
BA_ "U_P702_MY2021_Tx" SG_ 134 DispGlblClkHr_No_Rq 1;
BA_ "U_CD542_MY2021_Rx" SG_ 134 DispGlblClkHr_No_Rq 1;
BA_ "U_T6_MCA_MY2020_Rx" SG_ 134 DispGlblClkHr_No_Rq 1;
BA_ "WakeupSignal" SG_ 134 DispGlblClkHr_No_Rq 1;
BA_ "U_CD542_MY2021_Tx" SG_ 134 DispGlblClkDay_No_Rq 1;
BA_ "U_T6_MCA_MY2020_Tx" SG_ 134 DispGlblClkDay_No_Rq 1;
BA_ "U_P702_MY2021_Tx" SG_ 134 DispGlblClkDay_No_Rq 1;
BA_ "U_CD542_MY2021_Rx" SG_ 134 DispGlblClkDay_No_Rq 1;
BA_ "U_T6_MCA_MY2020_Rx" SG_ 134 DispGlblClkDay_No_Rq 1;
BA_ "WakeupSignal" SG_ 134 DispGlblClkDay_No_Rq 1;
BA_ "U_CD542_MY2021_Tx" SG_ 134 DispGlblClkAdj_B_Rq 1;
BA_ "U_T6_MCA_MY2020_Tx" SG_ 134 DispGlblClkAdj_B_Rq 1;
BA_ "U_P702_MY2021_Tx" SG_ 134 DispGlblClkAdj_B_Rq 1;
BA_ "U_CD542_MY2021_Rx" SG_ 134 DispGlblClkAdj_B_Rq 1;
BA_ "U_T6_MCA_MY2020_Rx" SG_ 134 DispGlblClkAdj_B_Rq 1;
BA_ "U_P702_MY2021_Rx" SG_ 134 DispGlblClkAdj_B_Rq 1;
BA_ "GenSigSendType" SG_ 134 DispGlblClkAdj_B_Rq 3;
BA_ "WakeupSignal" SG_ 134 DispGlblClkAdj_B_Rq 1;
BA_ "U_T6_MCA_MY2020_Rx" SG_ 766 McCntrStckNotfn_B_Stat 1;
BA_ "GenSigSendType" SG_ 766 McCntrStckNotfn_B_Stat 3;
BA_ "U_T6_MCA_MY2020_Tx" SG_ 766 McSelMsgId_No_Actl 1;
BA_ "U_T6_MCA_MY2020_Rx" SG_ 766 McSelMsgId_No_Actl 1;
BA_ "U_T6_MCA_MY2020_Tx" SG_ 766 McSelMsgId_B_Stat 1;
BA_ "U_T6_MCA_MY2020_Rx" SG_ 766 McSelMsgId_B_Stat 1;
BA_ "GenSigSendType" SG_ 766 McSelMsgId_B_Stat 3;
BA_ "U_T6_MCA_MY2020_Tx" SG_ 766 McSelChoice_D_Stat 1;
BA_ "U_T6_MCA_MY2020_Rx" SG_ 766 McSelChoice_D_Stat 1;
BA_ "U_T6_MCA_MY2020_Tx" SG_ 766 McPrsntMsgId_No_Actl 1;
BA_ "U_T6_MCA_MY2020_Rx" SG_ 766 McPrsntMsgId_No_Actl 1;
BA_ "GenSigSendType" SG_ 766 McPrsntMsgId_No_Actl 3;
BA_ "U_T6_MCA_MY2020_Tx" SG_ 766 McPrsntMsgId_B_Stat 1;
BA_ "U_T6_MCA_MY2020_Rx" SG_ 766 McPrsntMsgId_B_Stat 1;
BA_ "GenSigSendType" SG_ 766 McPrsntMsgId_B_Stat 3;
BA_ "U_T6_MCA_MY2020_Tx" SG_ 766 McPrsntActv_D_Stat 1;
BA_ "U_T6_MCA_MY2020_Rx" SG_ 766 McPrsntActv_D_Stat 1;
BA_ "GenSigSendType" SG_ 766 McPrsntActv_D_Stat 3;
BA_ "U_CD542_MY2021_Tx" SG_ 838 FohStrtDay_T_Rq 1;
BA_ "U_CD542_MY2021_Tx" SG_ 838 FohStop_B_Rq 1;
BA_ "GenSigStartValue" SG_ 838 FohStop_B_Rq 3;
BA_ "GenSigStartValueInteger" SG_ 838 FohStop_B_Rq 3;
BA_ "U_CD542_MY2021_Tx" SG_ 838 FohTAllEnable_B_Rq 1;
BA_ "GenSigStartValue" SG_ 838 FohTAllEnable_B_Rq 3;
BA_ "GenSigStartValueInteger" SG_ 838 FohTAllEnable_B_Rq 3;
BA_ "U_CD542_MY2021_Tx" SG_ 838 FohT2Mnte_T_Rq 1;
BA_ "U_CD542_MY2021_Tx" SG_ 838 FohT2Hr_T_Rq 1;
BA_ "U_CD542_MY2021_Tx" SG_ 838 FohT2Enable_B_Rq 1;
BA_ "U_CD542_MY2021_Tx" SG_ 838 FohT1Mnte_T_Rq 1;
BA_ "U_CD542_MY2021_Tx" SG_ 838 FohT1Hr_T_Rq 1;
BA_ "U_CD542_MY2021_Tx" SG_ 838 FohT1Enable_B_Rq 1;
BA_ "U_CD542_MY2021_Tx" SG_ 838 FohStrtMnte_T_Rq 1;
BA_ "U_CD542_MY2021_Tx" SG_ 838 FohStrtHr_T_Rq 1;
BA_ "U_CD542_MY2021_Tx" SG_ 838 FohStrtEnable_B_Rq 1;
BA_ "U_CD542_MY2021_Tx" SG_ 838 FohContOn_B_Rq 1;
BA_ "GenSigStartValue" SG_ 838 FohContOn_B_Rq 3;
BA_ "GenSigStartValueInteger" SG_ 838 FohContOn_B_Rq 3;
BA_ "U_CD542_MY2021_Tx" SG_ 559 EhData2_No_Actl 1;
BA_ "U_T6_MCA_MY2020_Tx" SG_ 559 EhData2_No_Actl 1;
BA_ "U_P702_MY2021_Tx" SG_ 559 EhData2_No_Actl 1;
BA_ "U_T6_MCA_MY2020_Rx" SG_ 559 EhData2_No_Actl 1;
BA_ "GenSigSendType" SG_ 559 EhData2_No_Actl 1;
BA_ "U_CD542_MY2021_Tx" SG_ 558 EhData1_No_Actl 1;
BA_ "U_T6_MCA_MY2020_Tx" SG_ 558 EhData1_No_Actl 1;
BA_ "U_P702_MY2021_Tx" SG_ 558 EhData1_No_Actl 1;
BA_ "U_T6_MCA_MY2020_Rx" SG_ 558 EhData1_No_Actl 1;
BA_ "GenSigSendType" SG_ 558 EhData1_No_Actl 1;
BA_ "U_CD542_MY2021_Rx" SG_ 939 PrkAidSnsRlSide_D_Stat 1;
BA_ "U_T6_MCA_MY2020_Rx" SG_ 939 PrkAidSnsRlSide_D_Stat 1;
BA_ "U_P702_MY2021_Rx" SG_ 939 SidePrkSnsR4_D_Stat 1;
BA_ "U_CD542_MY2021_Rx" SG_ 939 SidePrkSnsR4_D_Stat 1;
BA_ "U_T6_MCA_MY2020_Rx" SG_ 939 SidePrkSnsR4_D_Stat 1;
BA_ "U_P702_MY2021_Rx" SG_ 939 SidePrkSnsR3_D_Stat 1;
BA_ "U_CD542_MY2021_Rx" SG_ 939 SidePrkSnsR3_D_Stat 1;
BA_ "U_T6_MCA_MY2020_Rx" SG_ 939 SidePrkSnsR3_D_Stat 1;
BA_ "U_P702_MY2021_Rx" SG_ 939 SidePrkSnsL4_D_Stat 1;
BA_ "U_CD542_MY2021_Rx" SG_ 939 SidePrkSnsL4_D_Stat 1;
BA_ "U_T6_MCA_MY2020_Rx" SG_ 939 SidePrkSnsL4_D_Stat 1;
BA_ "U_P702_MY2021_Rx" SG_ 939 SidePrkSnsL3_D_Stat 1;
BA_ "U_CD542_MY2021_Rx" SG_ 939 SidePrkSnsL3_D_Stat 1;
BA_ "U_T6_MCA_MY2020_Rx" SG_ 939 SidePrkSnsL3_D_Stat 1;
BA_ "U_CD542_MY2021_Rx" SG_ 939 PrkAidChime_D_Stat 1;
BA_ "U_T6_MCA_MY2020_Rx" SG_ 939 PrkAidChime_D_Stat 1;
BA_ "U_CD542_MY2021_Rx" SG_ 939 PrkAidSnsRlCntr_D_Stat 1;
BA_ "U_T6_MCA_MY2020_Rx" SG_ 939 PrkAidSnsRlCntr_D_Stat 1;
BA_ "U_CD542_MY2021_Rx" SG_ 939 PrkAidSnsRrCrnr_D_Stat 1;
BA_ "U_T6_MCA_MY2020_Rx" SG_ 939 PrkAidSnsRrCrnr_D_Stat 1;
BA_ "U_CD542_MY2021_Rx" SG_ 939 PrkAidSnsRrCntr_D_Stat 1;
BA_ "U_T6_MCA_MY2020_Rx" SG_ 939 PrkAidSnsRrCntr_D_Stat 1;
BA_ "U_CD542_MY2021_Rx" SG_ 939 PrkAidSnsRlCrnr_D_Stat 1;
BA_ "U_T6_MCA_MY2020_Rx" SG_ 939 PrkAidSnsRlCrnr_D_Stat 1;
BA_ "U_CD542_MY2021_Rx" SG_ 939 PrkAidRear_D_Stat 1;
BA_ "U_T6_MCA_MY2020_Rx" SG_ 939 PrkAidRear_D_Stat 1;
BA_ "U_P702_MY2021_Rx" SG_ 939 PrkAidRear_D_Stat 1;
BA_ "U_P702_MY2021_Rx" SG_ 939 PrkAidFront_D_Stat 1;
BA_ "U_CD542_MY2021_Rx" SG_ 939 PrkAidFront_D_Stat 1;
BA_ "U_T6_MCA_MY2020_Rx" SG_ 939 PrkAidFront_D_Stat 1;
BA_ "U_CD542_MY2021_Rx" SG_ 939 PrkAid_D_Falt 1;
BA_ "U_T6_MCA_MY2020_Rx" SG_ 939 PrkAid_D_Falt 1;
BA_ "U_CD542_MY2021_Rx" SG_ 939 PrkAidSnsRrSide_D_Stat 1;
BA_ "U_T6_MCA_MY2020_Rx" SG_ 939 PrkAidSnsRrSide_D_Stat 1;
BA_ "GenSigStartValue" SG_ 939 ApaBrk_A_Rq 255;
BA_ "GenSigStartValueInteger" SG_ 939 ApaBrk_A_Rq 255;
BA_ "U_P702_MY2021_Rx" SG_ 938 SidePrkSnsR2_D_Stat 1;
BA_ "U_CD542_MY2021_Rx" SG_ 938 SidePrkSnsR2_D_Stat 1;
BA_ "U_T6_MCA_MY2020_Rx" SG_ 938 SidePrkSnsR2_D_Stat 1;
BA_ "U_P702_MY2021_Rx" SG_ 938 SidePrkSnsR1_D_Stat 1;
BA_ "U_CD542_MY2021_Rx" SG_ 938 SidePrkSnsR1_D_Stat 1;
BA_ "U_T6_MCA_MY2020_Rx" SG_ 938 SidePrkSnsR1_D_Stat 1;
BA_ "U_P702_MY2021_Rx" SG_ 938 SidePrkSnsL2_D_Stat 1;
BA_ "U_CD542_MY2021_Rx" SG_ 938 SidePrkSnsL2_D_Stat 1;
BA_ "U_T6_MCA_MY2020_Rx" SG_ 938 SidePrkSnsL2_D_Stat 1;
BA_ "U_P702_MY2021_Rx" SG_ 938 SidePrkSnsL1_D_Stat 1;
BA_ "U_CD542_MY2021_Rx" SG_ 938 SidePrkSnsL1_D_Stat 1;
BA_ "U_T6_MCA_MY2020_Rx" SG_ 938 SidePrkSnsL1_D_Stat 1;
BA_ "U_CD542_MY2021_Rx" SG_ 938 ApaMde_D_Stat 1;
BA_ "U_T6_MCA_MY2020_Rx" SG_ 938 ApaMde_D_Stat 1;
BA_ "U_CD542_MY2021_Rx" SG_ 938 ApaActvSd_D_Actl 1;
BA_ "U_T6_MCA_MY2020_Rx" SG_ 938 ApaActvSd_D_Actl 1;
BA_ "GenSigStartValue" SG_ 938 ApaActvSd_D_Actl 1;
BA_ "GenSigStartValueInteger" SG_ 938 ApaActvSd_D_Actl 1;
BA_ "U_CD542_MY2021_Rx" SG_ 938 PrkAidSwtch_B_Stat 1;
BA_ "U_T6_MCA_MY2020_Rx" SG_ 938 PrkAidSwtch_B_Stat 1;
BA_ "U_P702_MY2021_Rx" SG_ 938 PrkAidSwtch_B_Stat 1;
BA_ "U_CD542_MY2021_Rx" SG_ 938 PrkAidMsgTxt_D_Rq 1;
BA_ "U_T6_MCA_MY2020_Rx" SG_ 938 PrkAidMsgTxt_D_Rq 1;
BA_ "U_P702_MY2021_Rx" SG_ 938 PrkAidMsgTxt_D_Rq 1;
BA_ "U_CD542_MY2021_Rx" SG_ 938 ApaMde_D_Avail 1;
BA_ "U_T6_MCA_MY2020_Rx" SG_ 938 ApaMde_D_Avail 1;
BA_ "U_CD542_MY2021_Rx" SG_ 938 PrkAidSnsFrSide_D_Stat 1;
BA_ "U_T6_MCA_MY2020_Rx" SG_ 938 PrkAidSnsFrSide_D_Stat 1;
BA_ "U_CD542_MY2021_Rx" SG_ 938 PrkAidSnsFrCrnr_D_Stat 1;
BA_ "U_T6_MCA_MY2020_Rx" SG_ 938 PrkAidSnsFrCrnr_D_Stat 1;
BA_ "U_CD542_MY2021_Rx" SG_ 938 PrkAidSnsFrCntr_D_Stat 1;
BA_ "U_T6_MCA_MY2020_Rx" SG_ 938 PrkAidSnsFrCntr_D_Stat 1;
BA_ "U_CD542_MY2021_Rx" SG_ 938 PrkAidSnsFlSide_D_Stat 1;
BA_ "U_T6_MCA_MY2020_Rx" SG_ 938 PrkAidSnsFlSide_D_Stat 1;
BA_ "U_CD542_MY2021_Rx" SG_ 938 PrkAidSnsFlCrnr_D_Stat 1;
BA_ "U_T6_MCA_MY2020_Rx" SG_ 938 PrkAidSnsFlCrnr_D_Stat 1;
BA_ "U_CD542_MY2021_Rx" SG_ 938 PrkAidSnsFlCntr_D_Stat 1;
BA_ "U_T6_MCA_MY2020_Rx" SG_ 938 PrkAidSnsFlCntr_D_Stat 1;
BA_ "U_CD542_MY2021_Rx" SG_ 938 RpaChime_D_Rq 1;
BA_ "U_T6_MCA_MY2020_Rx" SG_ 938 RpaChime_D_Rq 1;
BA_ "U_P702_MY2021_Rx" SG_ 938 RpaChime_D_Rq 1;
BA_ "U_CD542_MY2021_Rx" SG_ 938 FpaChime_D_Rq 1;
BA_ "U_T6_MCA_MY2020_Rx" SG_ 938 FpaChime_D_Rq 1;
BA_ "U_P702_MY2021_Rx" SG_ 938 FpaChime_D_Rq 1;
BA_ "U_CD542_MY2021_Rx" SG_ 938 PrkAidAudioMute_B_Rq 1;
BA_ "U_T6_MCA_MY2020_Rx" SG_ 938 PrkAidAudioMute_B_Rq 1;
BA_ "U_P702_MY2021_Rx" SG_ 952 Tire_Press_IRR_Data 1;
BA_ "U_CD542_MY2021_Rx" SG_ 952 Tire_Press_IRR_Data 1;
BA_ "U_T6_MCA_MY2020_Rx" SG_ 952 Tire_Press_IRR_Data 1;
BA_ "GenSigStartValue" SG_ 952 Tire_Press_IRR_Data 65533;
BA_ "GenSigStartValueInteger" SG_ 952 Tire_Press_IRR_Data 65533;
BA_ "U_P702_MY2021_Rx" SG_ 952 Tire_Press_ILR_Data 1;
BA_ "U_CD542_MY2021_Rx" SG_ 952 Tire_Press_ILR_Data 1;
BA_ "U_T6_MCA_MY2020_Rx" SG_ 952 Tire_Press_ILR_Data 1;
BA_ "GenSigStartValue" SG_ 952 Tire_Press_ILR_Data 65533;
BA_ "GenSigStartValueInteger" SG_ 952 Tire_Press_ILR_Data 65533;
BA_ "U_CD542_MY2021_Rx" SG_ 845 SeatMasgPsngr_D_Stat 1;
BA_ "U_T6_MCA_MY2020_Rx" SG_ 845 SeatMasgPsngr_D_Stat 1;
BA_ "U_P702_MY2021_Rx" SG_ 845 SeatMasgPsngr_D_Stat 1;
BA_ "U_CD542_MY2021_Rx" SG_ 845 SeatIntnsPsngr_D_Stat 1;
BA_ "U_T6_MCA_MY2020_Rx" SG_ 845 SeatIntnsPsngr_D_Stat 1;
BA_ "U_P702_MY2021_Rx" SG_ 845 SeatIntnsPsngr_D_Stat 1;
BA_ "U_CD542_MY2021_Rx" SG_ 845 StmsLmbrPsgr_D_Stat 1;
BA_ "U_T6_MCA_MY2020_Rx" SG_ 845 StmsLmbrPsgr_D_Stat 1;
BA_ "U_P702_MY2021_Rx" SG_ 845 StmsLmbrPsgr_D_Stat 1;
BA_ "U_CD542_MY2021_Rx" SG_ 845 StmsCshnPsgr_D_Stat 1;
BA_ "U_T6_MCA_MY2020_Rx" SG_ 845 StmsCshnPsgr_D_Stat 1;
BA_ "U_P702_MY2021_Rx" SG_ 845 StmsCshnPsgr_D_Stat 1;
BA_ "U_CD542_MY2021_Rx" SG_ 845 SeatSwtchPsgr_B_Stat 1;
BA_ "U_T6_MCA_MY2020_Rx" SG_ 845 SeatSwtchPsgr_B_Stat 1;
BA_ "U_P702_MY2021_Rx" SG_ 845 SeatSwtchPsgr_B_Stat 1;
BA_ "U_CD542_MY2021_Rx" SG_ 845 SeatPPsgr_B_Stat 1;
BA_ "U_T6_MCA_MY2020_Rx" SG_ 845 SeatPPsgr_B_Stat 1;
BA_ "U_P702_MY2021_Rx" SG_ 845 SeatPPsgr_B_Stat 1;
BA_ "U_CD542_MY2021_Rx" SG_ 845 SeatFnPsgr_D_Stat 1;
BA_ "U_T6_MCA_MY2020_Rx" SG_ 845 SeatFnPsgr_D_Stat 1;
BA_ "U_P702_MY2021_Rx" SG_ 845 SeatFnPsgr_D_Stat 1;
BA_ "U_CD542_MY2021_Rx" SG_ 845 PsgrMemFeedback_Rsp 1;
BA_ "U_T6_MCA_MY2020_Rx" SG_ 845 PsgrMemFeedback_Rsp 1;
BA_ "U_P702_MY2021_Rx" SG_ 845 PsgrMemFeedback_Rsp 1;
BA_ "U_CD542_MY2021_Rx" SG_ 1137 RngPerChrgLbl_L_Dsply 1;
BA_ "U_T6_MCA_MY2020_Rx" SG_ 1137 RngPerChrgLbl_L_Dsply 1;
BA_ "GenSigStartValue" SG_ 1137 RngPerChrgLbl_L_Dsply 4093;
BA_ "GenSigStartValueInteger" SG_ 1137 RngPerChrgLbl_L_Dsply 4094;
BA_ "U_CD542_MY2021_Rx" SG_ 1137 RngPerChrgAvg_L_Dsply 1;
BA_ "U_T6_MCA_MY2020_Rx" SG_ 1137 RngPerChrgAvg_L_Dsply 1;
BA_ "GenSigStartValue" SG_ 1137 RngPerChrgAvg_L_Dsply 4093;
BA_ "GenSigStartValueInteger" SG_ 1137 RngPerChrgAvg_L_Dsply 4094;
BA_ "U_CD542_MY2021_Rx" SG_ 1137 RngImpctTot_Pc_Dsply 1;
BA_ "U_T6_MCA_MY2020_Rx" SG_ 1137 RngImpctTot_Pc_Dsply 1;
BA_ "GenSigStartValue" SG_ 1137 RngImpctTot_Pc_Dsply 1022;
BA_ "GenSigStartValueInteger" SG_ 1137 RngImpctTot_Pc_Dsply 1023;
BA_ "U_CD542_MY2021_Rx" SG_ 1137 RngImpctExt_Pc_Dsply 1;
BA_ "U_T6_MCA_MY2020_Rx" SG_ 1137 RngImpctExt_Pc_Dsply 1;
BA_ "GenSigStartValue" SG_ 1137 RngImpctExt_Pc_Dsply 1022;
BA_ "GenSigStartValueInteger" SG_ 1137 RngImpctExt_Pc_Dsply 1023;
BA_ "U_CD542_MY2021_Rx" SG_ 1137 RngImpctDrv_Pc_Dsply 1;
BA_ "U_T6_MCA_MY2020_Rx" SG_ 1137 RngImpctDrv_Pc_Dsply 1;
BA_ "GenSigStartValue" SG_ 1137 RngImpctDrv_Pc_Dsply 1022;
BA_ "GenSigStartValueInteger" SG_ 1137 RngImpctDrv_Pc_Dsply 1023;
BA_ "U_CD542_MY2021_Rx" SG_ 1137 RngImpctClim_Pc_Dsply 1;
BA_ "U_T6_MCA_MY2020_Rx" SG_ 1137 RngImpctClim_Pc_Dsply 1;
BA_ "GenSigStartValue" SG_ 1137 RngImpctClim_Pc_Dsply 1022;
BA_ "GenSigStartValueInteger" SG_ 1137 RngImpctClim_Pc_Dsply 1023;
BA_ "U_CD542_MY2021_Rx" SG_ 1073 AutoHoldMsgTxt_D_Rq 1;
BA_ "U_T6_MCA_MY2020_Rx" SG_ 1073 AutoHoldMsgTxt_D_Rq 1;
BA_ "GenSigSendType" SG_ 1073 AutoHoldMsgTxt_D_Rq 3;
BA_ "U_CD542_MY2021_Rx" SG_ 1073 AutoHoldMde_D_Ind 1;
BA_ "U_T6_MCA_MY2020_Rx" SG_ 1073 AutoHoldMde_D_Ind 1;
BA_ "GenSigSendType" SG_ 1073 AutoHoldMde_D_Ind 3;
BA_ "U_T6_MCA_MY2020_Rx" SG_ 1073 SteEffort_D_Stat 1;
BA_ "GenSigSendType" SG_ 1073 SteEffort_D_Stat 3;
BA_ "U_CD542_MY2021_Rx" SG_ 1073 TbsLamp_D_RqDsply 1;
BA_ "U_T6_MCA_MY2020_Rx" SG_ 1073 TbsLamp_D_RqDsply 1;
BA_ "GenSigSendType" SG_ 1073 TbsLamp_D_RqDsply 3;
BA_ "U_CD542_MY2021_Rx" SG_ 1073 TrnMsgTxt_D_Rq 1;
BA_ "U_T6_MCA_MY2020_Rx" SG_ 1073 TrnMsgTxt_D_Rq 1;
BA_ "U_P702_MY2021_Rx" SG_ 1073 TrnMsgTxt_D_Rq 1;
BA_ "GenSigSendType" SG_ 1073 TrnMsgTxt_D_Rq 3;
BA_ "U_CD542_MY2021_Rx" SG_ 1073 TrnGearNtmAllow_B_Stat 1;
BA_ "U_T6_MCA_MY2020_Rx" SG_ 1073 TrnGearNtmAllow_B_Stat 1;
BA_ "GenSigSendType" SG_ 1073 TrnGearNtmAllow_B_Stat 3;
BA_ "ContentDependant" SG_ 1073 TrnGearNtmAllow_B_Stat 1;
BA_ "U_CD542_MY2021_Rx" SG_ 1073 TrnGearMsgTxt_D_Rq 1;
BA_ "U_T6_MCA_MY2020_Rx" SG_ 1073 TrnGearMsgTxt_D_Rq 1;
BA_ "GenSigSendType" SG_ 1073 TrnGearMsgTxt_D_Rq 3;
BA_ "ContentDependant" SG_ 1073 TrnGearMsgTxt_D_Rq 1;
BA_ "U_CD542_MY2021_Rx" SG_ 1073 FuelFlw_Vl_ActlFoh 1;
BA_ "U_T6_MCA_MY2020_Rx" SG_ 1073 FuelFlw_Vl_ActlFoh 1;
BA_ "U_P702_MY2021_Rx" SG_ 1073 FuelFlw_Vl_ActlFoh 1;
BA_ "GenSigSendType" SG_ 1073 FuelFlw_Vl_ActlFoh 3;
BA_ "ContentDependant" SG_ 1073 FuelFlw_Vl_ActlFoh 1;
BA_ "U_CD542_MY2021_Rx" SG_ 1073 PdstrnAlrt_B_Falt_UB 1;
BA_ "U_T6_MCA_MY2020_Rx" SG_ 1073 PdstrnAlrt_B_Falt_UB 1;
BA_ "U_P702_MY2021_Rx" SG_ 1073 PdstrnAlrt_B_Falt_UB 1;
BA_ "U_CD542_MY2021_Rx" SG_ 1073 PdstrnAlrt_B_Falt 1;
BA_ "U_T6_MCA_MY2020_Rx" SG_ 1073 PdstrnAlrt_B_Falt 1;
BA_ "U_P702_MY2021_Rx" SG_ 1073 PdstrnAlrt_B_Falt 1;
BA_ "GenSigSendType" SG_ 1073 PdstrnAlrt_B_Falt 3;
BA_ "U_CD542_MY2021_Rx" SG_ 1073 TrnMsgTxt_D_Rq_UB 1;
BA_ "U_T6_MCA_MY2020_Rx" SG_ 1073 TrnMsgTxt_D_Rq_UB 1;
BA_ "U_P702_MY2021_Rx" SG_ 1073 TrnMsgTxt_D_Rq_UB 1;
BA_ "U_CD542_MY2021_Rx" SG_ 1073 TrnMsgTxt2_D_Rq_UB 1;
BA_ "U_T6_MCA_MY2020_Rx" SG_ 1073 TrnMsgTxt2_D_Rq_UB 1;
BA_ "U_P702_MY2021_Rx" SG_ 1073 TrnMsgTxt2_D_Rq_UB 1;
BA_ "U_CD542_MY2021_Rx" SG_ 1073 TrnGearNtmAllow_B_Stat_UB 1;
BA_ "U_T6_MCA_MY2020_Rx" SG_ 1073 TrnGearNtmAllow_B_Stat_UB 1;
BA_ "U_CD542_MY2021_Rx" SG_ 1073 TrnGearMsgTxt_D_Rq_UB 1;
BA_ "U_T6_MCA_MY2020_Rx" SG_ 1073 TrnGearMsgTxt_D_Rq_UB 1;
BA_ "U_CD542_MY2021_Rx" SG_ 1073 TbsLamp_D_RqDsply_UB 1;
BA_ "U_T6_MCA_MY2020_Rx" SG_ 1073 TbsLamp_D_RqDsply_UB 1;
BA_ "U_T6_MCA_MY2020_Rx" SG_ 1073 SteEffort_D_Stat_UB 1;
BA_ "U_T6_MCA_MY2020_Rx" SG_ 1073 RvrseMirrorChime_B_Rq_UB 1;
BA_ "U_CD542_MY2021_Rx" SG_ 1073 FuelFlw_Vl_ActlFoh_UB 1;
BA_ "U_T6_MCA_MY2020_Rx" SG_ 1073 FuelFlw_Vl_ActlFoh_UB 1;
BA_ "U_P702_MY2021_Rx" SG_ 1073 FuelFlw_Vl_ActlFoh_UB 1;
BA_ "U_CD542_MY2021_Rx" SG_ 1073 AutoHoldMsgTxt_D_Rq_UB 1;
BA_ "U_T6_MCA_MY2020_Rx" SG_ 1073 AutoHoldMsgTxt_D_Rq_UB 1;
BA_ "U_CD542_MY2021_Rx" SG_ 1073 AutoHoldMde_D_Ind_UB 1;
BA_ "U_T6_MCA_MY2020_Rx" SG_ 1073 AutoHoldMde_D_Ind_UB 1;
BA_ "U_T6_MCA_MY2020_Rx" SG_ 1073 RvrseMirrorChime_B_Rq 1;
BA_ "GenSigSendType" SG_ 1073 RvrseMirrorChime_B_Rq 3;
BA_ "U_CD542_MY2021_Rx" SG_ 1073 TrnMsgTxt2_D_Rq 1;
BA_ "U_T6_MCA_MY2020_Rx" SG_ 1073 TrnMsgTxt2_D_Rq 1;
BA_ "U_P702_MY2021_Rx" SG_ 1073 TrnMsgTxt2_D_Rq 1;
BA_ "GenSigSendType" SG_ 1073 TrnMsgTxt2_D_Rq 3;
BA_ "U_CD542_MY2021_Rx" SG_ 844 SeatMasgDrv_D_Stat 1;
BA_ "U_T6_MCA_MY2020_Rx" SG_ 844 SeatMasgDrv_D_Stat 1;
BA_ "U_P702_MY2021_Rx" SG_ 844 SeatMasgDrv_D_Stat 1;
BA_ "U_CD542_MY2021_Rx" SG_ 844 SeatIntnsDrv_D_Stat 1;
BA_ "U_T6_MCA_MY2020_Rx" SG_ 844 SeatIntnsDrv_D_Stat 1;
BA_ "U_P702_MY2021_Rx" SG_ 844 SeatIntnsDrv_D_Stat 1;
BA_ "U_CD542_MY2021_Rx" SG_ 844 StmsLmbrDrv_D_Stat 1;
BA_ "U_T6_MCA_MY2020_Rx" SG_ 844 StmsLmbrDrv_D_Stat 1;
BA_ "U_P702_MY2021_Rx" SG_ 844 StmsLmbrDrv_D_Stat 1;
BA_ "U_CD542_MY2021_Rx" SG_ 844 StmsCshnDrv_D_Stat 1;
BA_ "U_T6_MCA_MY2020_Rx" SG_ 844 StmsCshnDrv_D_Stat 1;
BA_ "U_P702_MY2021_Rx" SG_ 844 StmsCshnDrv_D_Stat 1;
BA_ "U_CD542_MY2021_Rx" SG_ 844 SeatSwtchDrv_B_Stat 1;
BA_ "U_T6_MCA_MY2020_Rx" SG_ 844 SeatSwtchDrv_B_Stat 1;
BA_ "U_P702_MY2021_Rx" SG_ 844 SeatSwtchDrv_B_Stat 1;
BA_ "U_CD542_MY2021_Rx" SG_ 844 SeatFnDrv_D_Stat 1;
BA_ "U_T6_MCA_MY2020_Rx" SG_ 844 SeatFnDrv_D_Stat 1;
BA_ "U_P702_MY2021_Rx" SG_ 844 SeatFnDrv_D_Stat 1;
BA_ "U_CD542_MY2021_Rx" SG_ 844 SeatAirAmb_P_Actl 1;
BA_ "U_T6_MCA_MY2020_Rx" SG_ 844 SeatAirAmb_P_Actl 1;
BA_ "U_P702_MY2021_Rx" SG_ 844 SeatAirAmb_P_Actl 1;
BA_ "U_CD542_MY2021_Rx" SG_ 844 SeatPDrv_B_Stat 1;
BA_ "U_T6_MCA_MY2020_Rx" SG_ 844 SeatPDrv_B_Stat 1;
BA_ "U_P702_MY2021_Rx" SG_ 844 SeatPDrv_B_Stat 1;
BA_ "U_CD542_MY2021_Rx" SG_ 843 SeatLmbrUpPsgr_Pc_Actl 1;
BA_ "U_T6_MCA_MY2020_Rx" SG_ 843 SeatLmbrUpPsgr_Pc_Actl 1;
BA_ "U_P702_MY2021_Rx" SG_ 843 SeatLmbrUpPsgr_Pc_Actl 1;
BA_ "GenSigStartValue" SG_ 843 SeatLmbrUpPsgr_Pc_Actl 127;
BA_ "GenSigStartValueInteger" SG_ 843 SeatLmbrUpPsgr_Pc_Actl 127;
BA_ "U_CD542_MY2021_Rx" SG_ 843 SeatLmbrMidPsgr_Pc_Actl 1;
BA_ "U_T6_MCA_MY2020_Rx" SG_ 843 SeatLmbrMidPsgr_Pc_Actl 1;
BA_ "U_P702_MY2021_Rx" SG_ 843 SeatLmbrMidPsgr_Pc_Actl 1;
BA_ "GenSigStartValue" SG_ 843 SeatLmbrMidPsgr_Pc_Actl 127;
BA_ "GenSigStartValueInteger" SG_ 843 SeatLmbrMidPsgr_Pc_Actl 127;
BA_ "U_CD542_MY2021_Rx" SG_ 843 SeatLmbrLoPsgr_Pc_Actl 1;
BA_ "U_T6_MCA_MY2020_Rx" SG_ 843 SeatLmbrLoPsgr_Pc_Actl 1;
BA_ "U_P702_MY2021_Rx" SG_ 843 SeatLmbrLoPsgr_Pc_Actl 1;
BA_ "GenSigStartValue" SG_ 843 SeatLmbrLoPsgr_Pc_Actl 127;
BA_ "GenSigStartValueInteger" SG_ 843 SeatLmbrLoPsgr_Pc_Actl 127;
BA_ "U_CD542_MY2021_Rx" SG_ 843 SeatBlUpPsgr_Pc_Actl 1;
BA_ "U_T6_MCA_MY2020_Rx" SG_ 843 SeatBlUpPsgr_Pc_Actl 1;
BA_ "U_P702_MY2021_Rx" SG_ 843 SeatBlUpPsgr_Pc_Actl 1;
BA_ "GenSigStartValue" SG_ 843 SeatBlUpPsgr_Pc_Actl 127;
BA_ "GenSigStartValueInteger" SG_ 843 SeatBlUpPsgr_Pc_Actl 127;
BA_ "U_CD542_MY2021_Rx" SG_ 843 SeatBlLoPsgr_Pc_Actl 1;
BA_ "U_T6_MCA_MY2020_Rx" SG_ 843 SeatBlLoPsgr_Pc_Actl 1;
BA_ "U_P702_MY2021_Rx" SG_ 843 SeatBlLoPsgr_Pc_Actl 1;
BA_ "GenSigStartValue" SG_ 843 SeatBlLoPsgr_Pc_Actl 127;
BA_ "GenSigStartValueInteger" SG_ 843 SeatBlLoPsgr_Pc_Actl 127;
BA_ "U_CD542_MY2021_Rx" SG_ 842 SeatLmbrUpDrv_Pc_Actl 1;
BA_ "U_T6_MCA_MY2020_Rx" SG_ 842 SeatLmbrUpDrv_Pc_Actl 1;
BA_ "U_P702_MY2021_Rx" SG_ 842 SeatLmbrUpDrv_Pc_Actl 1;
BA_ "GenSigStartValue" SG_ 842 SeatLmbrUpDrv_Pc_Actl 127;
BA_ "GenSigStartValueInteger" SG_ 842 SeatLmbrUpDrv_Pc_Actl 127;
BA_ "U_CD542_MY2021_Rx" SG_ 842 SeatLmbrMidDrv_Pc_Actl 1;
BA_ "U_T6_MCA_MY2020_Rx" SG_ 842 SeatLmbrMidDrv_Pc_Actl 1;
BA_ "U_P702_MY2021_Rx" SG_ 842 SeatLmbrMidDrv_Pc_Actl 1;
BA_ "GenSigStartValue" SG_ 842 SeatLmbrMidDrv_Pc_Actl 127;
BA_ "GenSigStartValueInteger" SG_ 842 SeatLmbrMidDrv_Pc_Actl 127;
BA_ "U_CD542_MY2021_Rx" SG_ 842 SeatLmbrLoDrv_Pc_Actl 1;
BA_ "U_T6_MCA_MY2020_Rx" SG_ 842 SeatLmbrLoDrv_Pc_Actl 1;
BA_ "U_P702_MY2021_Rx" SG_ 842 SeatLmbrLoDrv_Pc_Actl 1;
BA_ "GenSigStartValue" SG_ 842 SeatLmbrLoDrv_Pc_Actl 127;
BA_ "GenSigStartValueInteger" SG_ 842 SeatLmbrLoDrv_Pc_Actl 127;
BA_ "U_CD542_MY2021_Rx" SG_ 842 SeatBlUpDrv_Pc_Actl 1;
BA_ "U_T6_MCA_MY2020_Rx" SG_ 842 SeatBlUpDrv_Pc_Actl 1;
BA_ "U_P702_MY2021_Rx" SG_ 842 SeatBlUpDrv_Pc_Actl 1;
BA_ "GenSigStartValue" SG_ 842 SeatBlUpDrv_Pc_Actl 127;
BA_ "GenSigStartValueInteger" SG_ 842 SeatBlUpDrv_Pc_Actl 127;
BA_ "U_CD542_MY2021_Rx" SG_ 842 SeatBlLoDrv_Pc_Actl 1;
BA_ "U_T6_MCA_MY2020_Rx" SG_ 842 SeatBlLoDrv_Pc_Actl 1;
BA_ "U_P702_MY2021_Rx" SG_ 842 SeatBlLoDrv_Pc_Actl 1;
BA_ "GenSigStartValue" SG_ 842 SeatBlLoDrv_Pc_Actl 127;
BA_ "GenSigStartValueInteger" SG_ 842 SeatBlLoDrv_Pc_Actl 127;
BA_ "U_CD542_MY2021_Tx" SG_ 846 SeatMasgDrv_D_Rq 1;
BA_ "U_T6_MCA_MY2020_Tx" SG_ 846 SeatMasgDrv_D_Rq 1;
BA_ "U_P702_MY2021_Tx" SG_ 846 SeatMasgDrv_D_Rq 1;
BA_ "GenSigSendType" SG_ 846 SeatMasgDrv_D_Rq 3;
BA_ "U_CD542_MY2021_Tx" SG_ 846 SeatMasgPsngr_D_Rq 1;
BA_ "U_T6_MCA_MY2020_Tx" SG_ 846 SeatMasgPsngr_D_Rq 1;
BA_ "U_P702_MY2021_Tx" SG_ 846 SeatMasgPsngr_D_Rq 1;
BA_ "GenSigSendType" SG_ 846 SeatMasgPsngr_D_Rq 3;
BA_ "U_CD542_MY2021_Tx" SG_ 846 SeatLmbr_D_Rq 1;
BA_ "U_T6_MCA_MY2020_Tx" SG_ 846 SeatLmbr_D_Rq 1;
BA_ "U_P702_MY2021_Tx" SG_ 846 SeatLmbr_D_Rq 1;
BA_ "GenSigSendType" SG_ 846 SeatLmbr_D_Rq 3;
BA_ "U_CD542_MY2021_Tx" SG_ 846 SeatFnChngPsgr2_D_Rq 1;
BA_ "U_T6_MCA_MY2020_Tx" SG_ 846 SeatFnChngPsgr2_D_Rq 1;
BA_ "U_P702_MY2021_Tx" SG_ 846 SeatFnChngPsgr2_D_Rq 1;
BA_ "GenSigSendType" SG_ 846 SeatFnChngPsgr2_D_Rq 3;
BA_ "U_CD542_MY2021_Tx" SG_ 846 SeatFnChngDrv2_D_Rq 1;
BA_ "U_T6_MCA_MY2020_Tx" SG_ 846 SeatFnChngDrv2_D_Rq 1;
BA_ "U_P702_MY2021_Tx" SG_ 846 SeatFnChngDrv2_D_Rq 1;
BA_ "GenSigSendType" SG_ 846 SeatFnChngDrv2_D_Rq 3;
BA_ "U_CD542_MY2021_Tx" SG_ 846 SeatFnPsgr_D_Rq 1;
BA_ "U_T6_MCA_MY2020_Tx" SG_ 846 SeatFnPsgr_D_Rq 1;
BA_ "U_P702_MY2021_Tx" SG_ 846 SeatFnPsgr_D_Rq 1;
BA_ "GenSigSendType" SG_ 846 SeatFnPsgr_D_Rq 3;
BA_ "U_CD542_MY2021_Tx" SG_ 846 SeatFnDrv_D_Rq 1;
BA_ "U_T6_MCA_MY2020_Tx" SG_ 846 SeatFnDrv_D_Rq 1;
BA_ "U_P702_MY2021_Tx" SG_ 846 SeatFnDrv_D_Rq 1;
BA_ "GenSigSendType" SG_ 846 SeatFnDrv_D_Rq 3;
BA_ "U_CD542_MY2021_Tx" SG_ 846 SeatFnDfaltPsgr_B_Rq 1;
BA_ "U_T6_MCA_MY2020_Tx" SG_ 846 SeatFnDfaltPsgr_B_Rq 1;
BA_ "U_P702_MY2021_Tx" SG_ 846 SeatFnDfaltPsgr_B_Rq 1;
BA_ "GenSigSendType" SG_ 846 SeatFnDfaltPsgr_B_Rq 3;
BA_ "U_CD542_MY2021_Tx" SG_ 846 SeatFnDfaltDrv_B_Rq 1;
BA_ "U_T6_MCA_MY2020_Tx" SG_ 846 SeatFnDfaltDrv_B_Rq 1;
BA_ "U_P702_MY2021_Tx" SG_ 846 SeatFnDfaltDrv_B_Rq 1;
BA_ "GenSigSendType" SG_ 846 SeatFnDfaltDrv_B_Rq 3;
BA_ "U_CD542_MY2021_Tx" SG_ 846 SeatFnChngPsgr_D_Rq 1;
BA_ "U_T6_MCA_MY2020_Tx" SG_ 846 SeatFnChngPsgr_D_Rq 1;
BA_ "U_P702_MY2021_Tx" SG_ 846 SeatFnChngPsgr_D_Rq 1;
BA_ "GenSigSendType" SG_ 846 SeatFnChngPsgr_D_Rq 3;
BA_ "U_CD542_MY2021_Tx" SG_ 846 SeatFnChngDrv_D_Rq 1;
BA_ "U_T6_MCA_MY2020_Tx" SG_ 846 SeatFnChngDrv_D_Rq 1;
BA_ "U_P702_MY2021_Tx" SG_ 846 SeatFnChngDrv_D_Rq 1;
BA_ "GenSigSendType" SG_ 846 SeatFnChngDrv_D_Rq 3;
BA_ "U_CD542_MY2021_Tx" SG_ 846 PsgrMemory_Rq 1;
BA_ "U_T6_MCA_MY2020_Tx" SG_ 846 PsgrMemory_Rq 1;
BA_ "U_P702_MY2021_Tx" SG_ 846 PsgrMemory_Rq 1;
BA_ "GenSigSendType" SG_ 846 PsgrMemory_Rq 3;
BA_ "U_T6_MCA_MY2020_Rx" SG_ 935 CtaAlrtRight2_D_Stat 1;
BA_ "U_CD542_MY2021_Rx" SG_ 935 BttRight_D_Stat 1;
BA_ "U_T6_MCA_MY2020_Rx" SG_ 935 BttRight_D_Stat 1;
BA_ "U_P702_MY2021_Rx" SG_ 935 BttRight_D_Stat 1;
BA_ "U_T6_MCA_MY2020_Rx" SG_ 935 BttRight_D_RqDrv 1;
BA_ "U_P702_MY2021_Rx" SG_ 935 BttRight_D_RqDrv 1;
BA_ "U_T6_MCA_MY2020_Rx" SG_ 935 CtaBrkRightMsgTxt_B_Rq 1;
BA_ "U_P702_MY2021_Rx" SG_ 935 CtaBrkRightMsgTxt_B_Rq 1;
BA_ "U_T6_MCA_MY2020_Rx" SG_ 935 Side_Detect_R_Illum 1;
BA_ "GenSigStartValue" SG_ 935 Side_Detect_R_Illum 100;
BA_ "GenSigStartValueInteger" SG_ 935 Side_Detect_R_Illum 100;
BA_ "U_T6_MCA_MY2020_Rx" SG_ 935 CtaSnsRight_D_Stat 1;
BA_ "U_P702_MY2021_Rx" SG_ 935 CtaSnsRight_D_Stat 1;
BA_ "U_CD542_MY2021_Rx" SG_ 935 CtaAlrtRight_D_Stat 1;
BA_ "U_T6_MCA_MY2020_Rx" SG_ 935 CtaAlrtRight_D_Stat 1;
BA_ "U_P702_MY2021_Rx" SG_ 935 CtaAlrtRight_D_Stat 1;
BA_ "U_T6_MCA_MY2020_Rx" SG_ 935 CtaRight_D_Stat 1;
BA_ "U_P702_MY2021_Rx" SG_ 935 CtaRight_D_Stat 1;
BA_ "U_T6_MCA_MY2020_Rx" SG_ 935 SodRight_D_Stat 1;
BA_ "U_P702_MY2021_Rx" SG_ 935 SodRight_D_Stat 1;
BA_ "GenSigStartValue" SG_ 935 SodRight_D_Stat 2;
BA_ "GenSigStartValueInteger" SG_ 935 SodRight_D_Stat 2;
BA_ "U_T6_MCA_MY2020_Rx" SG_ 935 SodSnsRight_D_Stat 1;
BA_ "U_P702_MY2021_Rx" SG_ 935 SodSnsRight_D_Stat 1;
BA_ "U_T6_MCA_MY2020_Rx" SG_ 935 SodAlrtRight_D_Stat 1;
BA_ "U_T6_MCA_MY2020_Rx" SG_ 935 SodDetctRight_D_Stat 1;
BA_ "GenSigStartValue" SG_ 935 SodWarnRight_Prd_Rq 14;
BA_ "GenSigStartValueInteger" SG_ 935 SodWarnRight_Prd_Rq 14;
BA_ "U_CD542_MY2021_Rx" SG_ 934 CtaAlrtLeft2_D_Stat 1;
BA_ "U_T6_MCA_MY2020_Rx" SG_ 934 CtaAlrtLeft2_D_Stat 1;
BA_ "U_CD542_MY2021_Rx" SG_ 934 BttLeft_D_Stat 1;
BA_ "U_T6_MCA_MY2020_Rx" SG_ 934 BttLeft_D_Stat 1;
BA_ "U_P702_MY2021_Rx" SG_ 934 BttLeft_D_Stat 1;
BA_ "U_CD542_MY2021_Rx" SG_ 934 BttLeft_D_RqDrv 1;
BA_ "U_T6_MCA_MY2020_Rx" SG_ 934 BttLeft_D_RqDrv 1;
BA_ "U_P702_MY2021_Rx" SG_ 934 BttLeft_D_RqDrv 1;
BA_ "U_CD542_MY2021_Rx" SG_ 934 CtaBrkLeftMsgTxt_B_Rq 1;
BA_ "U_T6_MCA_MY2020_Rx" SG_ 934 CtaBrkLeftMsgTxt_B_Rq 1;
BA_ "U_P702_MY2021_Rx" SG_ 934 CtaBrkLeftMsgTxt_B_Rq 1;
BA_ "U_CD542_MY2021_Rx" SG_ 934 Side_Detect_L_Illum 1;
BA_ "U_T6_MCA_MY2020_Rx" SG_ 934 Side_Detect_L_Illum 1;
BA_ "GenSigStartValue" SG_ 934 Side_Detect_L_Illum 100;
BA_ "GenSigStartValueInteger" SG_ 934 Side_Detect_L_Illum 100;
BA_ "U_CD542_MY2021_Rx" SG_ 934 CtaSnsLeft_D_Stat 1;
BA_ "U_T6_MCA_MY2020_Rx" SG_ 934 CtaSnsLeft_D_Stat 1;
BA_ "U_P702_MY2021_Rx" SG_ 934 CtaSnsLeft_D_Stat 1;
BA_ "U_CD542_MY2021_Rx" SG_ 934 SodDetctLeft_D_Stat 1;
BA_ "U_T6_MCA_MY2020_Rx" SG_ 934 SodDetctLeft_D_Stat 1;
BA_ "U_CD542_MY2021_Rx" SG_ 934 CtaLeft_D_Stat 1;
BA_ "U_T6_MCA_MY2020_Rx" SG_ 934 CtaLeft_D_Stat 1;
BA_ "U_P702_MY2021_Rx" SG_ 934 CtaLeft_D_Stat 1;
BA_ "U_CD542_MY2021_Rx" SG_ 934 CtaAlrtLeft_D_Stat 1;
BA_ "U_T6_MCA_MY2020_Rx" SG_ 934 CtaAlrtLeft_D_Stat 1;
BA_ "U_P702_MY2021_Rx" SG_ 934 CtaAlrtLeft_D_Stat 1;
BA_ "U_CD542_MY2021_Rx" SG_ 934 SodLeft_D_Stat 1;
BA_ "U_T6_MCA_MY2020_Rx" SG_ 934 SodLeft_D_Stat 1;
BA_ "U_P702_MY2021_Rx" SG_ 934 SodLeft_D_Stat 1;
BA_ "GenSigStartValue" SG_ 934 SodLeft_D_Stat 2;
BA_ "GenSigStartValueInteger" SG_ 934 SodLeft_D_Stat 2;
BA_ "U_CD542_MY2021_Rx" SG_ 934 SodSnsLeft_D_Stat 1;
BA_ "U_T6_MCA_MY2020_Rx" SG_ 934 SodSnsLeft_D_Stat 1;
BA_ "U_P702_MY2021_Rx" SG_ 934 SodSnsLeft_D_Stat 1;
BA_ "U_CD542_MY2021_Rx" SG_ 934 SodAlrtLeft_D_Stat 1;
BA_ "U_T6_MCA_MY2020_Rx" SG_ 934 SodAlrtLeft_D_Stat 1;
BA_ "GenSigStartValue" SG_ 934 SodWarnLeft_Prd_Rq 14;
BA_ "GenSigStartValueInteger" SG_ 934 SodWarnLeft_Prd_Rq 14;
BA_ "U_T6_MCA_MY2020_Tx" SG_ 486 ResponseCode_No_Res 1;
BA_ "U_CD542_MY2021_Rx" SG_ 486 ResponseCode_No_Res 1;
BA_ "U_T6_MCA_MY2020_Rx" SG_ 486 ResponseCode_No_Res 1;
BA_ "GenSigSendType" SG_ 486 ResponseCode_No_Res 3;
BA_ "U_CD542_MY2021_Tx" SG_ 486 ACU_ARAudioSource_Rsp 1;
BA_ "U_T6_MCA_MY2020_Tx" SG_ 486 ACU_ARAudioSource_Rsp 1;
BA_ "U_P702_MY2021_Tx" SG_ 486 ACU_ARAudioSource_Rsp 1;
BA_ "U_CD542_MY2021_Rx" SG_ 486 ACU_ARAudioSource_Rsp 1;
BA_ "U_P702_MY2021_Rx" SG_ 486 ACU_ARAudioSource_Rsp 1;
BA_ "U_T6_MCA_MY2020_Rx" SG_ 486 ACU_ARAudioSource_Rsp 1;
BA_ "U_CD542_MY2021_Tx" SG_ 486 ACU_AROperationType_Rsp 1;
BA_ "U_T6_MCA_MY2020_Tx" SG_ 486 ACU_AROperationType_Rsp 1;
BA_ "U_P702_MY2021_Tx" SG_ 486 ACU_AROperationType_Rsp 1;
BA_ "U_CD542_MY2021_Rx" SG_ 486 ACU_AROperationType_Rsp 1;
BA_ "U_P702_MY2021_Rx" SG_ 486 ACU_AROperationType_Rsp 1;
BA_ "U_T6_MCA_MY2020_Rx" SG_ 486 ACU_AROperationType_Rsp 1;
BA_ "U_T6_MCA_MY2020_Tx" SG_ 486 ACU_ARReqstrSystem_Rsp 1;
BA_ "U_P702_MY2021_Tx" SG_ 486 ACU_ARReqstrSystem_Rsp 1;
BA_ "U_CD542_MY2021_Rx" SG_ 486 ACU_ARReqstrSystem_Rsp 1;
BA_ "U_P702_MY2021_Rx" SG_ 486 ACU_ARReqstrSystem_Rsp 1;
BA_ "U_T6_MCA_MY2020_Rx" SG_ 486 ACU_ARReqstrSystem_Rsp 1;
BA_ "U_CD542_MY2021_Tx" SG_ 486 ACU_ARResponse_Rsp 1;
BA_ "U_T6_MCA_MY2020_Tx" SG_ 486 ACU_ARResponse_Rsp 1;
BA_ "U_P702_MY2021_Tx" SG_ 486 ACU_ARResponse_Rsp 1;
BA_ "U_CD542_MY2021_Rx" SG_ 486 ACU_ARResponse_Rsp 1;
BA_ "U_P702_MY2021_Rx" SG_ 486 ACU_ARResponse_Rsp 1;
BA_ "U_T6_MCA_MY2020_Rx" SG_ 486 ACU_ARResponse_Rsp 1;
BA_ "GenSigSendType" SG_ 486 ACU_ARResponse_Rsp 1;
BA_ "U_T6_MCA_MY2020_Tx" SG_ 486 ACU_ARReqstrPriority_Rp 1;
BA_ "U_P702_MY2021_Tx" SG_ 486 ACU_ARReqstrPriority_Rp 1;
BA_ "U_CD542_MY2021_Rx" SG_ 486 ACU_ARReqstrPriority_Rp 1;
BA_ "U_P702_MY2021_Rx" SG_ 486 ACU_ARReqstrPriority_Rp 1;
BA_ "U_T6_MCA_MY2020_Rx" SG_ 486 ACU_ARReqstrPriority_Rp 1;
BA_ "U_CD542_MY2021_Tx" SG_ 486 ACU_RUAudioSource_St 1;
BA_ "U_T6_MCA_MY2020_Tx" SG_ 486 ACU_RUAudioSource_St 1;
BA_ "U_P702_MY2021_Tx" SG_ 486 ACU_RUAudioSource_St 1;
BA_ "U_U55X_MY2022_Rx" SG_ 486 ACU_RUAudioSource_St 1;
BA_ "ECGUsedRxSignal" SG_ 486 ACU_RUAudioSource_St 1;
BA_ "U_P702_MY2021_Rx" SG_ 486 ACU_RUAudioSource_St 1;
BA_ "U_CX727_MY2021_Rx" SG_ 486 ACU_RUAudioSource_St 1;
BA_ "U_CD542_MY2021_Rx" SG_ 486 ACU_RUAudioSource_St 1;
BA_ "U_T6_MCA_MY2020_Rx" SG_ 486 ACU_RUAudioSource_St 1;
BA_ "U_T6_MCA_MY2020_Tx" SG_ 486 ACU_RUReqstrSystem_St 1;
BA_ "U_P702_MY2021_Tx" SG_ 486 ACU_RUReqstrSystem_St 1;
BA_ "U_P702_MY2021_Rx" SG_ 486 ACU_RUReqstrSystem_St 1;
BA_ "U_CD542_MY2021_Rx" SG_ 486 ACU_RUReqstrSystem_St 1;
BA_ "U_T6_MCA_MY2020_Rx" SG_ 486 ACU_RUReqstrSystem_St 1;
BA_ "U_T6_MCA_MY2020_Tx" SG_ 486 ACU_RUResReqstStatus_St 1;
BA_ "U_P702_MY2021_Tx" SG_ 486 ACU_RUResReqstStatus_St 1;
BA_ "U_U55X_MY2022_Rx" SG_ 486 ACU_RUResReqstStatus_St 1;
BA_ "ECGUsedRxSignal" SG_ 486 ACU_RUResReqstStatus_St 1;
BA_ "U_P702_MY2021_Rx" SG_ 486 ACU_RUResReqstStatus_St 1;
BA_ "U_CX727_MY2021_Rx" SG_ 486 ACU_RUResReqstStatus_St 1;
BA_ "U_CD542_MY2021_Rx" SG_ 486 ACU_RUResReqstStatus_St 1;
BA_ "U_T6_MCA_MY2020_Rx" SG_ 486 ACU_RUResReqstStatus_St 1;
BA_ "U_T6_MCA_MY2020_Tx" SG_ 486 ACU_RUReqstrPriority_St 1;
BA_ "U_P702_MY2021_Tx" SG_ 486 ACU_RUReqstrPriority_St 1;
BA_ "U_P702_MY2021_Rx" SG_ 486 ACU_RUReqstrPriority_St 1;
BA_ "U_CX727_MY2021_Rx" SG_ 486 ACU_RUReqstrPriority_St 1;
BA_ "U_CD542_MY2021_Rx" SG_ 486 ACU_RUReqstrPriority_St 1;
BA_ "U_T6_MCA_MY2020_Rx" SG_ 486 ACU_RUReqstrPriority_St 1;
BA_ "U_CD542_MY2021_Tx" SG_ 553 CCOI_PolicyClient_St 1;
BA_ "U_T6_MCA_MY2020_Tx" SG_ 553 CCOI_PolicyClient_St 1;
BA_ "U_P702_MY2021_Tx" SG_ 553 CCOI_PolicyClient_St 1;
BA_ "GenSigStartValue" SG_ 553 DistToChrgrBynd_L_Actl 510;
BA_ "U_CD542_MY2021_Tx" SG_ 553 ResetAvgFe_B_Rq 1;
BA_ "U_T6_MCA_MY2020_Tx" SG_ 553 ResetAvgFe_B_Rq 1;
BA_ "U_T6_MCA_MY2020_Rx" SG_ 553 ResetAvgFe_B_Rq 1;
BA_ "GenSigSendType" SG_ 553 ResetAvgFe_B_Rq 3;
BA_ "U_CD542_MY2021_Tx" SG_ 553 ResetTrip2_B_Rq 1;
BA_ "U_T6_MCA_MY2020_Tx" SG_ 553 ResetTrip2_B_Rq 1;
BA_ "U_T6_MCA_MY2020_Rx" SG_ 553 ResetTrip2_B_Rq 1;
BA_ "GenSigSendType" SG_ 553 ResetTrip2_B_Rq 3;
BA_ "U_CD542_MY2021_Tx" SG_ 553 SndImmrsnLvl_D_Rq 1;
BA_ "U_T6_MCA_MY2020_Tx" SG_ 553 SndImmrsnLvl_D_Rq 1;
BA_ "U_CD542_MY2021_Rx" SG_ 553 SndImmrsnLvl_D_Rq 1;
BA_ "GenSigSendType" SG_ 553 SndImmrsnLvl_D_Rq 3;
BA_ "U_CD542_MY2021_Tx" SG_ 553 InfoSysMasterPw_D_Stat 1;
BA_ "U_T6_MCA_MY2020_Tx" SG_ 553 InfoSysMasterPw_D_Stat 1;
BA_ "U_U55X_MY2022_Rx" SG_ 553 InfoSysMasterPw_D_Stat 1;
BA_ "ECGUsedRxSignal" SG_ 553 InfoSysMasterPw_D_Stat 1;
BA_ "U_T6_MCA_MY2020_Rx" SG_ 553 InfoSysMasterPw_D_Stat 1;
BA_ "GenSigSendType" SG_ 553 InfoSysMasterPw_D_Stat 3;
BA_ "U_CD542_MY2021_Tx" SG_ 553 ResetTrip1_B_Rq 1;
BA_ "U_T6_MCA_MY2020_Tx" SG_ 553 ResetTrip1_B_Rq 1;
BA_ "U_T6_MCA_MY2020_Rx" SG_ 553 ResetTrip1_B_Rq 1;
BA_ "GenSigSendType" SG_ 553 ResetTrip1_B_Rq 3;
BA_ "U_CD542_MY2021_Tx" SG_ 553 Disp_LangSel2_St 1;
BA_ "U_T6_MCA_MY2020_Tx" SG_ 553 Disp_LangSel2_St 1;
BA_ "U_P702_MY2021_Tx" SG_ 553 Disp_LangSel2_St 1;
BA_ "U_U55X_MY2022_Rx" SG_ 553 Disp_LangSel2_St 1;
BA_ "ECGUsedRxSignal" SG_ 553 Disp_LangSel2_St 1;
BA_ "U_T6_MCA_MY2020_Rx" SG_ 553 Disp_LangSel2_St 1;
BA_ "GenSigSendType" SG_ 553 Disp_LangSel2_St 3;
BA_ "U_CD542_MY2021_Tx" SG_ 553 Disp_LangSel_St 1;
BA_ "U_T6_MCA_MY2020_Tx" SG_ 553 Disp_LangSel_St 1;
BA_ "U_P702_MY2021_Tx" SG_ 553 Disp_LangSel_St 1;
BA_ "U_U55X_MY2022_Rx" SG_ 553 Disp_LangSel_St 1;
BA_ "ECGUsedRxSignal" SG_ 553 Disp_LangSel_St 1;
BA_ "U_CD542_MY2021_Rx" SG_ 553 Disp_LangSel_St 1;
BA_ "U_T6_MCA_MY2020_Rx" SG_ 553 Disp_LangSel_St 1;
BA_ "GenSigSendType" SG_ 553 Disp_LangSel_St 3;
BA_ "U_CD542_MY2021_Tx" SG_ 553 Diagnostic_Operation_Rq 1;
BA_ "U_T6_MCA_MY2020_Tx" SG_ 553 Diagnostic_Operation_Rq 1;
BA_ "U_P702_MY2021_Tx" SG_ 553 Diagnostic_Operation_Rq 1;
BA_ "U_CD542_MY2021_Rx" SG_ 553 Diagnostic_Operation_Rq 1;
BA_ "U_T6_MCA_MY2020_Rx" SG_ 553 Diagnostic_Operation_Rq 1;
BA_ "U_P702_MY2021_Rx" SG_ 553 Diagnostic_Operation_Rq 1;
BA_ "GenSigSendType" SG_ 553 Diagnostic_Operation_Rq 3;
BA_ "U_CD542_MY2021_Tx" SG_ 553 Bezel_Diag_Module_Rq 1;
BA_ "U_T6_MCA_MY2020_Tx" SG_ 553 Bezel_Diag_Module_Rq 1;
BA_ "U_P702_MY2021_Tx" SG_ 553 Bezel_Diag_Module_Rq 1;
BA_ "U_CD542_MY2021_Rx" SG_ 553 Bezel_Diag_Module_Rq 1;
BA_ "U_T6_MCA_MY2020_Rx" SG_ 553 Bezel_Diag_Module_Rq 1;
BA_ "U_P702_MY2021_Rx" SG_ 553 Bezel_Diag_Module_Rq 1;
BA_ "GenSigSendType" SG_ 553 Bezel_Diag_Module_Rq 3;
BA_ "U_CD542_MY2021_Tx" SG_ 553 Audio_Demo_CMND 1;
BA_ "U_T6_MCA_MY2020_Tx" SG_ 553 Audio_Demo_CMND 1;
BA_ "U_P702_MY2021_Tx" SG_ 553 Audio_Demo_CMND 1;
BA_ "U_CD542_MY2021_Rx" SG_ 553 Audio_Demo_CMND 1;
BA_ "U_T6_MCA_MY2020_Rx" SG_ 553 Audio_Demo_CMND 1;
BA_ "U_P702_MY2021_Rx" SG_ 553 Audio_Demo_CMND 1;
BA_ "GenSigSendType" SG_ 553 Audio_Demo_CMND 3;
BA_ "U_CD542_MY2021_Tx" SG_ 553 Audio_Visualizer 1;
BA_ "U_T6_MCA_MY2020_Tx" SG_ 553 Audio_Visualizer 1;
BA_ "U_P702_MY2021_Tx" SG_ 553 Audio_Visualizer 1;
BA_ "U_CD542_MY2021_Rx" SG_ 553 Audio_Visualizer 1;
BA_ "U_T6_MCA_MY2020_Rx" SG_ 553 Audio_Visualizer 1;
BA_ "U_P702_MY2021_Rx" SG_ 553 Audio_Visualizer 1;
BA_ "GenSigSendType" SG_ 553 Audio_Visualizer 3;
BA_ "U_CD542_MY2021_Tx" SG_ 553 Surround_Sound_Upmix 1;
BA_ "U_T6_MCA_MY2020_Tx" SG_ 553 Surround_Sound_Upmix 1;
BA_ "U_P702_MY2021_Tx" SG_ 553 Surround_Sound_Upmix 1;
BA_ "U_CD542_MY2021_Rx" SG_ 553 Surround_Sound_Upmix 1;
BA_ "U_T6_MCA_MY2020_Rx" SG_ 553 Surround_Sound_Upmix 1;
BA_ "U_P702_MY2021_Rx" SG_ 553 Surround_Sound_Upmix 1;
BA_ "GenSigSendType" SG_ 553 Surround_Sound_Upmix 3;
BA_ "U_CD542_MY2021_Tx" SG_ 553 Bezel_Diag_State_Rq 1;
BA_ "U_T6_MCA_MY2020_Tx" SG_ 553 Bezel_Diag_State_Rq 1;
BA_ "U_P702_MY2021_Tx" SG_ 553 Bezel_Diag_State_Rq 1;
BA_ "U_CD542_MY2021_Rx" SG_ 553 Bezel_Diag_State_Rq 1;
BA_ "U_T6_MCA_MY2020_Rx" SG_ 553 Bezel_Diag_State_Rq 1;
BA_ "U_P702_MY2021_Rx" SG_ 553 Bezel_Diag_State_Rq 1;
BA_ "GenSigSendType" SG_ 553 Bezel_Diag_State_Rq 3;
BA_ "U_CD542_MY2021_Tx" SG_ 553 SurndSndUpmix2_D_Rq 1;
BA_ "U_T6_MCA_MY2020_Tx" SG_ 553 SurndSndUpmix2_D_Rq 1;
BA_ "U_P702_MY2021_Tx" SG_ 553 SurndSndUpmix2_D_Rq 1;
BA_ "U_CD542_MY2021_Rx" SG_ 553 SurndSndUpmix2_D_Rq 1;
BA_ "U_T6_MCA_MY2020_Rx" SG_ 553 SurndSndUpmix2_D_Rq 1;
BA_ "GenSigSendType" SG_ 553 SurndSndUpmix2_D_Rq 3;
BA_ "GenSigSendType" SG_ 739 EngExhMdeHrStrt_D_Rq 3;
BA_ "GenSigSendType" SG_ 739 EngExhMdeHrEnd_D_Rq 3;
BA_ "GenSigSendType" SG_ 739 EngExhMdeHrEnbl_D_Rq 3;
BA_ "U_CD542_MY2021_Tx" SG_ 739 Partial_Amp_Shutdown 1;
BA_ "U_T6_MCA_MY2020_Tx" SG_ 739 Partial_Amp_Shutdown 1;
BA_ "U_T6_MCA_MY2020_Rx" SG_ 739 Partial_Amp_Shutdown 1;
BA_ "GenSigSendType" SG_ 739 Partial_Amp_Shutdown 3;
BA_ "U_CD542_MY2021_Tx" SG_ 739 HMI_HMIMode_St 1;
BA_ "U_T6_MCA_MY2020_Tx" SG_ 739 HMI_HMIMode_St 1;
BA_ "U_U55X_MY2022_Rx" SG_ 739 HMI_HMIMode_St 1;
BA_ "ECGUsedRxSignal" SG_ 739 HMI_HMIMode_St 1;
BA_ "U_CX727_MY2021_Rx" SG_ 739 HMI_HMIMode_St 1;
BA_ "U_CD542_MY2021_Rx" SG_ 739 HMI_HMIMode_St 1;
BA_ "U_T6_MCA_MY2020_Rx" SG_ 739 HMI_HMIMode_St 1;
BA_ "U_P702_MY2021_Rx" SG_ 739 HMI_HMIMode_St 1;
BA_ "GenSigSendType" SG_ 739 HMI_HMIMode_St 3;
BA_ "WakeupSignal" SG_ 739 HMI_HMIMode_St 1;
BA_ "U_CD542_MY2021_Tx" SG_ 1009 ChrgCordUnlock_B_Rq 1;
BA_ "U_T6_MCA_MY2020_Tx" SG_ 1009 ChrgCordUnlock_B_Rq 1;
BA_ "U_P702_MY2021_Tx" SG_ 1009 ChrgCordUnlock_B_Rq 1;
BA_ "GenSigSendType" SG_ 1009 ChrgCordUnlock_B_Rq 3;
BA_ "U_CD542_MY2021_Tx" SG_ 1009 AutoHoldSwtch_D_Stat3 1;
BA_ "U_T6_MCA_MY2020_Tx" SG_ 1009 AutoHoldSwtch_D_Stat3 1;
BA_ "U_P702_MY2021_Tx" SG_ 1009 AutoHoldSwtch_D_Stat3 1;
BA_ "GenSigSendType" SG_ 1009 AutoHoldSwtch_D_Stat3 3;
BA_ "U_CD542_MY2021_Tx" SG_ 1009 TrlrTrgtAcquire_D_Rq 1;
BA_ "U_T6_MCA_MY2020_Tx" SG_ 1009 TrlrTrgtAcquire_D_Rq 1;
BA_ "U_P702_MY2021_Tx" SG_ 1009 TrlrTrgtAcquire_D_Rq 1;
BA_ "GenSigSendType" SG_ 1009 TrlrTrgtAcquire_D_Rq 3;
BA_ "U_CD542_MY2021_Tx" SG_ 1009 RearAudioCtlLck_D_Rq 1;
BA_ "U_T6_MCA_MY2020_Tx" SG_ 1009 RearAudioCtlLck_D_Rq 1;
BA_ "GenSigSendType" SG_ 1009 RearAudioCtlLck_D_Rq 3;
BA_ "U_CD542_MY2021_Tx" SG_ 1009 TrlrAidCancl_B_Rq 1;
BA_ "U_T6_MCA_MY2020_Tx" SG_ 1009 TrlrAidCancl_B_Rq 1;
BA_ "U_P702_MY2021_Tx" SG_ 1009 TrlrAidCancl_B_Rq 1;
BA_ "GenSigSendType" SG_ 1009 TrlrAidCancl_B_Rq 3;
BA_ "U_CD542_MY2021_Tx" SG_ 1009 CenterStackRing_D_Actl 1;
BA_ "U_T6_MCA_MY2020_Tx" SG_ 1009 CenterStackRing_D_Actl 1;
BA_ "U_P702_MY2021_Tx" SG_ 1009 CenterStackRing_D_Actl 1;
BA_ "GenSigSendType" SG_ 1009 CenterStackRing_D_Actl 3;
BA_ "GenSigStartValue" SG_ 1009 CenterStackRing_D_Actl 2;
BA_ "GenSigStartValueInteger" SG_ 1009 CenterStackRing_D_Actl 2;
BA_ "U_CD542_MY2021_Tx" SG_ 1009 APIM_NumberofTracks_St 1;
BA_ "U_T6_MCA_MY2020_Tx" SG_ 1009 APIM_NumberofTracks_St 1;
BA_ "U_P702_MY2021_Tx" SG_ 1009 APIM_NumberofTracks_St 1;
BA_ "U_CD542_MY2021_Rx" SG_ 1009 APIM_NumberofTracks_St 1;
BA_ "U_T6_MCA_MY2020_Rx" SG_ 1009 APIM_NumberofTracks_St 1;
BA_ "GenSigSendType" SG_ 1009 APIM_NumberofTracks_St 3;
BA_ "U_CD542_MY2021_Tx" SG_ 1009 APIM_ActiveTrackNum_St 1;
BA_ "U_T6_MCA_MY2020_Tx" SG_ 1009 APIM_ActiveTrackNum_St 1;
BA_ "U_P702_MY2021_Tx" SG_ 1009 APIM_ActiveTrackNum_St 1;
BA_ "U_CD542_MY2021_Rx" SG_ 1009 APIM_ActiveTrackNum_St 1;
BA_ "U_T6_MCA_MY2020_Rx" SG_ 1009 APIM_ActiveTrackNum_St 1;
BA_ "GenSigSendType" SG_ 1009 APIM_ActiveTrackNum_St 3;
BA_ "U_CD542_MY2021_Tx" SG_ 1009 ValetMode_D_Stat 1;
BA_ "U_T6_MCA_MY2020_Tx" SG_ 1009 ValetMode_D_Stat 1;
BA_ "U_P702_MY2021_Tx" SG_ 1009 ValetMode_D_Stat 1;
BA_ "GenSigSendType" SG_ 1009 ValetMode_D_Stat 3;
BA_ "U_CD542_MY2021_Tx" SG_ 1009 TrlrAidSetup_D_Stat 1;
BA_ "U_T6_MCA_MY2020_Tx" SG_ 1009 TrlrAidSetup_D_Stat 1;
BA_ "U_P702_MY2021_Tx" SG_ 1009 TrlrAidSetup_D_Stat 1;
BA_ "U_T6_MCA_MY2020_Rx" SG_ 1009 TrlrAidSetup_D_Stat 1;
BA_ "GenSigSendType" SG_ 1009 TrlrAidSetup_D_Stat 3;
BA_ "GenSigSendType" SG_ 531 VehStop_D_Stat 3;
BA_ "GenSigStartValue" SG_ 531 VehStop_D_Stat 2;
BA_ "GenSigStartValueInteger" SG_ 531 VehStop_D_Stat 2;
BA_ "GenSigSendType" SG_ 531 TracCtlPtActv_B_Actl 3;
BA_ "U_CD542_MY2021_Rx" SG_ 531 PrkBrkYwLamp_D_Rq 1;
BA_ "U_T6_MCA_MY2020_Rx" SG_ 531 PrkBrkYwLamp_D_Rq 1;
BA_ "U_P702_MY2021_Rx" SG_ 531 PrkBrkYwLamp_D_Rq 1;
BA_ "GenSigSendType" SG_ 531 PrkBrkYwLamp_D_Rq 3;
BA_ "WakeupSignal" SG_ 531 PrkBrkYwLamp_D_Rq 1;
BA_ "U_CD542_MY2021_Rx" SG_ 531 PrkBrkRedLamp_D_Rq 1;
BA_ "U_T6_MCA_MY2020_Rx" SG_ 531 PrkBrkRedLamp_D_Rq 1;
BA_ "U_P702_MY2021_Rx" SG_ 531 PrkBrkRedLamp_D_Rq 1;
BA_ "GenSigSendType" SG_ 531 PrkBrkRedLamp_D_Rq 3;
BA_ "WakeupSignal" SG_ 531 PrkBrkRedLamp_D_Rq 1;
BA_ "U_CD542_MY2021_Rx" SG_ 531 PrkBrkMsgTxt_D_Rq 1;
BA_ "U_T6_MCA_MY2020_Rx" SG_ 531 PrkBrkMsgTxt_D_Rq 1;
BA_ "U_P702_MY2021_Rx" SG_ 531 PrkBrkMsgTxt_D_Rq 1;
BA_ "GenSigSendType" SG_ 531 PrkBrkMsgTxt_D_Rq 3;
BA_ "WakeupSignal" SG_ 531 PrkBrkMsgTxt_D_Rq 1;
BA_ "U_CD542_MY2021_Rx" SG_ 531 PrkBrkStatus 1;
BA_ "U_T6_MCA_MY2020_Rx" SG_ 531 PrkBrkStatus 1;
BA_ "GenSigSendType" SG_ 531 PrkBrkStatus 3;
BA_ "GenSigStartValue" SG_ 531 PrkBrkStatus 7;
BA_ "GenSigStartValueInteger" SG_ 531 PrkBrkStatus 7;
BA_ "U_CD542_MY2021_Rx" SG_ 531 LscmbbMntr_B_Err 1;
BA_ "U_T6_MCA_MY2020_Rx" SG_ 531 LscmbbMntr_B_Err 1;
BA_ "GenSigSendType" SG_ 531 LscmbbMntr_B_Err 3;
BA_ "GenSigSendType" SG_ 531 LscmbbBrkDis_B_Actl 3;
BA_ "U_CD542_MY2021_Rx" SG_ 531 StabCtlBrkActv_B_Actl 1;
BA_ "U_T6_MCA_MY2020_Rx" SG_ 531 StabCtlBrkActv_B_Actl 1;
BA_ "GenSigSendType" SG_ 531 StabCtlBrkActv_B_Actl 3;
BA_ "U_T6_MCA_MY2020_Rx" SG_ 531 CmbbBrkPrchg_B_Actl 1;
BA_ "U_P702_MY2021_Rx" SG_ 531 CmbbBrkPrchg_B_Actl 1;
BA_ "GenSigSendType" SG_ 531 CmbbBrkPrchg_B_Actl 3;
BA_ "U_T6_MCA_MY2020_Rx" SG_ 531 CmbbBrkDecel_B_Actl 1;
BA_ "U_P702_MY2021_Rx" SG_ 531 CmbbBrkDecel_B_Actl 1;
BA_ "GenSigSendType" SG_ 531 CmbbBrkDecel_B_Actl 3;
BA_ "GenSigSendType" SG_ 531 CmbbBaSensInc_B_Actl 3;
BA_ "GenSigSendType" SG_ 531 AccBrkWarm_B_Actl 3;
BA_ "U_T6_MCA_MY2020_Rx" SG_ 531 AccBrkTotTqMn_B_Actl 1;
BA_ "U_P702_MY2021_Rx" SG_ 531 AccBrkTotTqMn_B_Actl 1;
BA_ "GenSigSendType" SG_ 531 AccBrkTotTqMn_B_Actl 3;
BA_ "GenSigSendType" SG_ 531 AccBrkPrchgActv_B_Actl 3;
BA_ "GenSigSendType" SG_ 531 AccBrkDis_B_Actl 3;
BA_ "GenSigSendType" SG_ 531 AccBrkDeny_B_Actl 3;
BA_ "GenSigSendType" SG_ 531 AccBrkActv_B_Actl 3;
BA_ "GenSigSendType" SG_ 531 PrplDrgCtlActv_B_Actl 3;
BA_ "U_P702_MY2021_Rx" SG_ 531 AbsActv_B_Actl 1;
BA_ "U_CD542_MY2021_Rx" SG_ 531 AbsActv_B_Actl 1;
BA_ "U_T6_MCA_MY2020_Rx" SG_ 531 AbsActv_B_Actl 1;
BA_ "GenSigSendType" SG_ 531 AbsActv_B_Actl 3;
BA_ "GenSigSendType" SG_ 531 CmbbBrkDis_B_Actl 3;
BA_ "GenSigSendType" SG_ 531 CmbbDeny_B_ActlBrk 3;
BA_ "GenSigSendType" SG_ 531 CcDis_B_Cmd 3;
BA_ "U_T6_MCA_MY2020_Rx" SG_ 531 VehLongOvrGnd_A_Est 1;
BA_ "U_P702_MY2021_Rx" SG_ 531 VehLongOvrGnd_A_Est 1;
BA_ "GenSigStartValueInteger" SG_ 531 VehLongOvrGnd_A_Est 511;
BA_ "GenSigSendType" SG_ 531 AccStopActv_B_ActlBrk 3;
BA_ "GenSigSendType" SG_ 531 AccDis_B_ActlEpb 3;
BA_ "GenSigSendType" SG_ 531 LscmbbDeny_B_ActlBrk 3;
BA_ "GenSigSendType" SG_ 531 LscmbbBrkDecel_B_Actl 3;
BA_ "GenSigSendType" SG_ 531 LscmbbBaSensInc_B_Actl 3;
BA_ "GenSigSendType" SG_ 531 LscmbBrkPrchg_B_Actl 3;
BA_ "GenSigSendType" SG_ 531 VehicleStationary 3;
BA_ "U_CD542_MY2021_Tx" SG_ 702 PHONE_MC_WORD_Rx 1;
BA_ "U_T6_MCA_MY2020_Tx" SG_ 702 PHONE_MC_WORD_Rx 1;
BA_ "U_CD542_MY2021_Rx" SG_ 702 PHONE_MC_WORD_Rx 1;
BA_ "U_T6_MCA_MY2020_Rx" SG_ 702 PHONE_MC_WORD_Rx 1;
BA_ "U_P702_MY2021_Rx" SG_ 702 PHONE_MC_WORD_Rx 1;
BA_ "U_T6_MCA_MY2020_Tx" SG_ 711 MyKeySrvr_Clnt_Word_Tx 1;
BA_ "U_CD542_MY2021_Rx" SG_ 711 MyKeySrvr_Clnt_Word_Tx 1;
BA_ "U_T6_MCA_MY2020_Rx" SG_ 711 MyKeySrvr_Clnt_Word_Tx 1;
BA_ "U_P702_MY2021_Rx" SG_ 711 MyKeySrvr_Clnt_Word_Tx 1;
BA_ "U_CD542_MY2021_Tx" SG_ 549 WwaActv_B_Stat 1;
BA_ "U_T6_MCA_MY2020_Tx" SG_ 549 WwaActv_B_Stat 1;
BA_ "U_CD542_MY2021_Rx" SG_ 549 WwaActv_B_Stat 1;
BA_ "U_T6_MCA_MY2020_Rx" SG_ 549 WwaActv_B_Stat 1;
BA_ "GenSigSendType" SG_ 549 WwaActv_B_Stat 3;
BA_ "GenSigSendType" SG_ 549 StrtInGearOk_D_Stat 3;
BA_ "U_CD542_MY2021_Tx" SG_ 549 Veh_V2_Dsply 1;
BA_ "U_T6_MCA_MY2020_Tx" SG_ 549 Veh_V2_Dsply 1;
BA_ "U_P702_MY2021_Tx" SG_ 549 Veh_V2_Dsply 1;
BA_ "U_CD542_MY2021_Rx" SG_ 549 Veh_V2_Dsply 1;
BA_ "U_T6_MCA_MY2020_Rx" SG_ 549 Veh_V2_Dsply 1;
BA_ "U_CD542_MY2021_Tx" SG_ 549 IPC_MyKeyVolLimit_St 1;
BA_ "U_T6_MCA_MY2020_Tx" SG_ 549 IPC_MyKeyVolLimit_St 1;
BA_ "U_P702_MY2021_Tx" SG_ 549 IPC_MyKeyVolLimit_St 1;
BA_ "U_CD542_MY2021_Rx" SG_ 549 IPC_MyKeyVolLimit_St 1;
BA_ "U_T6_MCA_MY2020_Rx" SG_ 549 IPC_MyKeyVolLimit_St 1;
BA_ "U_P702_MY2021_Rx" SG_ 549 IPC_MyKeyVolLimit_St 1;
BA_ "GenSigSendType" SG_ 549 IPC_MyKeyVolLimit_St 3;
BA_ "U_CD542_MY2021_Tx" SG_ 549 HudVertSzMnuOn_B_Rq 1;
BA_ "U_T6_MCA_MY2020_Tx" SG_ 549 HudVertSzMnuOn_B_Rq 1;
BA_ "U_T6_MCA_MY2020_Rx" SG_ 549 HudVertSzMnuOn_B_Rq 1;
BA_ "GenSigSendType" SG_ 549 HudVertSzMnuOn_B_Rq 3;
BA_ "U_CD542_MY2021_Tx" SG_ 549 HudVertMnuOn_B_Rq 1;
BA_ "U_T6_MCA_MY2020_Tx" SG_ 549 HudVertMnuOn_B_Rq 1;
BA_ "U_T6_MCA_MY2020_Rx" SG_ 549 HudVertMnuOn_B_Rq 1;
BA_ "GenSigSendType" SG_ 549 HudVertMnuOn_B_Rq 3;
BA_ "U_CD542_MY2021_Tx" SG_ 549 HudRotatMnuOn_B_Rq 1;
BA_ "U_T6_MCA_MY2020_Tx" SG_ 549 HudRotatMnuOn_B_Rq 1;
BA_ "U_T6_MCA_MY2020_Rx" SG_ 549 HudRotatMnuOn_B_Rq 1;
BA_ "GenSigSendType" SG_ 549 HudRotatMnuOn_B_Rq 3;
BA_ "U_CD542_MY2021_Tx" SG_ 549 HudCntntMnuOn_B_Rq 1;
BA_ "U_T6_MCA_MY2020_Tx" SG_ 549 HudCntntMnuOn_B_Rq 1;
BA_ "U_T6_MCA_MY2020_Rx" SG_ 549 HudCntntMnuOn_B_Rq 1;
BA_ "GenSigSendType" SG_ 549 HudCntntMnuOn_B_Rq 3;
BA_ "U_CD542_MY2021_Tx" SG_ 549 HudBrightMnuOn_B_Rq 1;
BA_ "U_T6_MCA_MY2020_Tx" SG_ 549 HudBrightMnuOn_B_Rq 1;
BA_ "U_T6_MCA_MY2020_Rx" SG_ 549 HudBrightMnuOn_B_Rq 1;
BA_ "GenSigSendType" SG_ 549 HudBrightMnuOn_B_Rq 3;
BA_ "U_CD542_MY2021_Tx" SG_ 549 HdcOn_B_Rq 1;
BA_ "U_T6_MCA_MY2020_Tx" SG_ 549 HdcOn_B_Rq 1;
BA_ "U_P702_MY2021_Tx" SG_ 549 HdcOn_B_Rq 1;
BA_ "GenSigSendType" SG_ 549 HdcOn_B_Rq 3;
BA_ "U_CD542_MY2021_Tx" SG_ 549 IPC_Attn_Info_Audio 1;
BA_ "U_T6_MCA_MY2020_Tx" SG_ 549 IPC_Attn_Info_Audio 1;
BA_ "U_P702_MY2021_Tx" SG_ 549 IPC_Attn_Info_Audio 1;
BA_ "U_CD542_MY2021_Rx" SG_ 549 IPC_Attn_Info_Audio 1;
BA_ "U_T6_MCA_MY2020_Rx" SG_ 549 IPC_Attn_Info_Audio 1;
BA_ "U_P702_MY2021_Rx" SG_ 549 IPC_Attn_Info_Audio 1;
BA_ "GenSigSendType" SG_ 549 IPC_Attn_Info_Audio 3;
BA_ "U_CD542_MY2021_Tx" SG_ 549 BeltminderAudioMute 1;
BA_ "U_T6_MCA_MY2020_Tx" SG_ 549 BeltminderAudioMute 1;
BA_ "U_P702_MY2021_Tx" SG_ 549 BeltminderAudioMute 1;
BA_ "U_CD542_MY2021_Rx" SG_ 549 BeltminderAudioMute 1;
BA_ "U_T6_MCA_MY2020_Rx" SG_ 549 BeltminderAudioMute 1;
BA_ "U_P702_MY2021_Rx" SG_ 549 BeltminderAudioMute 1;
BA_ "GenSigSendType" SG_ 549 BeltminderAudioMute 3;
BA_ "U_CD542_MY2021_Tx" SG_ 549 Power_Up_Chime_Modules 1;
BA_ "U_T6_MCA_MY2020_Tx" SG_ 549 Power_Up_Chime_Modules 1;
BA_ "U_P702_MY2021_Tx" SG_ 549 Power_Up_Chime_Modules 1;
BA_ "U_U55X_MY2022_Rx" SG_ 549 Power_Up_Chime_Modules 1;
BA_ "ECGUsedRxSignal" SG_ 549 Power_Up_Chime_Modules 1;
BA_ "U_CD542_MY2021_Rx" SG_ 549 Power_Up_Chime_Modules 1;
BA_ "U_T6_MCA_MY2020_Rx" SG_ 549 Power_Up_Chime_Modules 1;
BA_ "U_P702_MY2021_Rx" SG_ 549 Power_Up_Chime_Modules 1;
BA_ "GenSigSendType" SG_ 549 Power_Up_Chime_Modules 3;
BA_ "WakeupSignal" SG_ 549 Power_Up_Chime_Modules 1;
BA_ "U_CD542_MY2021_Tx" SG_ 549 Chime_Source 1;
BA_ "U_T6_MCA_MY2020_Tx" SG_ 549 Chime_Source 1;
BA_ "U_P702_MY2021_Tx" SG_ 549 Chime_Source 1;
BA_ "U_CD542_MY2021_Rx" SG_ 549 Chime_Source 1;
BA_ "U_T6_MCA_MY2020_Rx" SG_ 549 Chime_Source 1;
BA_ "U_P702_MY2021_Rx" SG_ 549 Chime_Source 1;
BA_ "GenSigSendType" SG_ 549 Chime_Source 3;
BA_ "U_CD542_MY2021_Tx" SG_ 549 IPC_New_Attn_Event 1;
BA_ "U_T6_MCA_MY2020_Tx" SG_ 549 IPC_New_Attn_Event 1;
BA_ "U_P702_MY2021_Tx" SG_ 549 IPC_New_Attn_Event 1;
BA_ "U_CD542_MY2021_Rx" SG_ 549 IPC_New_Attn_Event 1;
BA_ "U_T6_MCA_MY2020_Rx" SG_ 549 IPC_New_Attn_Event 1;
BA_ "U_P702_MY2021_Rx" SG_ 549 IPC_New_Attn_Event 1;
BA_ "GenSigSendType" SG_ 549 IPC_New_Attn_Event 3;
BA_ "U_CD542_MY2021_Tx" SG_ 549 MetricActv_B_Dsply 1;
BA_ "U_T6_MCA_MY2020_Tx" SG_ 549 MetricActv_B_Dsply 1;
BA_ "U_P702_MY2021_Tx" SG_ 549 MetricActv_B_Dsply 1;
BA_ "U_T6_MCA_MY2020_Rx" SG_ 549 MetricActv_B_Dsply 1;
BA_ "GenSigSendType" SG_ 549 MetricActv_B_Dsply 3;
BA_ "U_CD542_MY2021_Tx" SG_ 765 BalrSwtch_D_Stat 1;
BA_ "U_T6_MCA_MY2020_Tx" SG_ 765 BalrSwtch_D_Stat 1;
BA_ "U_P702_MY2021_Tx" SG_ 765 BalrSwtch_D_Stat 1;
BA_ "GenSigSendType" SG_ 765 BalrSwtch_D_Stat 3;
BA_ "GenSigStartValue" SG_ 765 BalrSwtch_D_Stat 1;
BA_ "GenSigStartValueInteger" SG_ 765 BalrSwtch_D_Stat 1;
BA_ "U_CD542_MY2021_Tx" SG_ 765 BalrMde_D_Rq 1;
BA_ "U_T6_MCA_MY2020_Tx" SG_ 765 BalrMde_D_Rq 1;
BA_ "U_P702_MY2021_Tx" SG_ 765 BalrMde_D_Rq 1;
BA_ "GenSigSendType" SG_ 765 BalrMde_D_Rq 3;
BA_ "U_CD542_MY2021_Tx" SG_ 765 RstrnOnPsngr_D_RqMnu 1;
BA_ "U_T6_MCA_MY2020_Tx" SG_ 765 RstrnOnPsngr_D_RqMnu 1;
BA_ "GenSigSendType" SG_ 765 RstrnOnPsngr_D_RqMnu 3;
BA_ "U_CD542_MY2021_Tx" SG_ 765 WaitToStartLamp_D_Falt 1;
BA_ "U_T6_MCA_MY2020_Tx" SG_ 765 WaitToStartLamp_D_Falt 1;
BA_ "U_P702_MY2021_Tx" SG_ 765 WaitToStartLamp_D_Falt 1;
BA_ "GenSigSendType" SG_ 765 WaitToStartLamp_D_Falt 3;
BA_ "GenSigStartValue" SG_ 765 WaitToStartLamp_D_Falt 1;
BA_ "GenSigStartValueInteger" SG_ 765 WaitToStartLamp_D_Falt 1;
BA_ "U_CD542_MY2021_Tx" SG_ 765 EsaOn_B_Rq 1;
BA_ "U_T6_MCA_MY2020_Tx" SG_ 765 EsaOn_B_Rq 1;
BA_ "U_P702_MY2021_Tx" SG_ 765 EsaOn_B_Rq 1;
BA_ "GenSigSendType" SG_ 765 EsaOn_B_Rq 3;
BA_ "GenSigStartValue" SG_ 765 EsaOn_B_Rq 1;
BA_ "GenSigStartValueInteger" SG_ 765 EsaOn_B_Rq 1;
BA_ "U_CD542_MY2021_Tx" SG_ 765 BttOn_B_Rq 1;
BA_ "U_T6_MCA_MY2020_Tx" SG_ 765 BttOn_B_Rq 1;
BA_ "U_P702_MY2021_Tx" SG_ 765 BttOn_B_Rq 1;
BA_ "GenSigSendType" SG_ 765 BttOn_B_Rq 3;
BA_ "U_CD542_MY2021_Tx" SG_ 765 Btt_L_Actl 1;
BA_ "U_T6_MCA_MY2020_Tx" SG_ 765 Btt_L_Actl 1;
BA_ "U_P702_MY2021_Tx" SG_ 765 Btt_L_Actl 1;
BA_ "GenSigStartValue" SG_ 765 Btt_L_Actl 126;
BA_ "GenSigStartValueInteger" SG_ 765 Btt_L_Actl 126;
BA_ "U_T6_MCA_MY2020_Tx" SG_ 765 RearDiffLck_D_RqArb 1;
BA_ "GenSigSendType" SG_ 765 RearDiffLck_D_RqArb 3;
BA_ "GenSigStartValue" SG_ 765 RearDiffLck_D_RqArb 3;
BA_ "GenSigStartValueInteger" SG_ 765 RearDiffLck_D_RqArb 3;
BA_ "U_T6_MCA_MY2020_Tx" SG_ 765 AwdMde_D_RqArb 1;
BA_ "GenSigSendType" SG_ 765 AwdMde_D_RqArb 3;
BA_ "GenSigStartValue" SG_ 765 AwdMde_D_RqArb 5;
BA_ "GenSigStartValueInteger" SG_ 765 AwdMde_D_RqArb 5;
BA_ "U_CD542_MY2021_Tx" SG_ 765 SelDrvMdeTxtReset_B_Rq 1;
BA_ "U_T6_MCA_MY2020_Tx" SG_ 765 SelDrvMdeTxtReset_B_Rq 1;
BA_ "U_P702_MY2021_Tx" SG_ 765 SelDrvMdeTxtReset_B_Rq 1;
BA_ "GenSigSendType" SG_ 765 SelDrvMdeTxtReset_B_Rq 3;
BA_ "U_CD542_MY2021_Tx" SG_ 765 AutoTowAllw_D_RqMnu 1;
BA_ "U_T6_MCA_MY2020_Tx" SG_ 765 AutoTowAllw_D_RqMnu 1;
BA_ "GenSigSendType" SG_ 765 AutoTowAllw_D_RqMnu 3;
BA_ "U_CD542_MY2021_Tx" SG_ 765 DrvInputRequired_B_Rq 1;
BA_ "U_T6_MCA_MY2020_Tx" SG_ 765 DrvInputRequired_B_Rq 1;
BA_ "U_P702_MY2021_Tx" SG_ 765 DrvInputRequired_B_Rq 1;
BA_ "GenSigSendType" SG_ 765 DrvInputRequired_B_Rq 3;
BA_ "WakeupSignal" SG_ 765 DrvInputRequired_B_Rq 1;
BA_ "U_CD542_MY2021_Tx" SG_ 765 SelDrvMdeDsply_B_Avail 1;
BA_ "U_T6_MCA_MY2020_Tx" SG_ 765 SelDrvMdeDsply_B_Avail 1;
BA_ "U_P702_MY2021_Tx" SG_ 765 SelDrvMdeDsply_B_Avail 1;
BA_ "GenSigSendType" SG_ 765 SelDrvMdeDsply_B_Avail 3;
BA_ "U_T6_MCA_MY2020_Tx" SG_ 765 EngExhMdeQuiet_D_Rq 1;
BA_ "GenSigSendType" SG_ 765 EngExhMdeQuiet_D_Rq 3;
BA_ "GenSigStartValue" SG_ 765 EngExhMdeQuiet_D_Rq 2;
BA_ "GenSigStartValueInteger" SG_ 765 EngExhMdeQuiet_D_Rq 2;
BA_ "U_T6_MCA_MY2020_Tx" SG_ 765 AirSusp_D_RqDrv 1;
BA_ "GenSigSendType" SG_ 765 AirSusp_D_RqDrv 3;
BA_ "U_CD542_MY2021_Tx" SG_ 765 Mc_VehUntTrpCoUsrSel_St 1;
BA_ "U_T6_MCA_MY2020_Tx" SG_ 765 Mc_VehUntTrpCoUsrSel_St 1;
BA_ "U_P702_MY2021_Tx" SG_ 765 Mc_VehUntTrpCoUsrSel_St 1;
BA_ "U_CD542_MY2021_Rx" SG_ 765 Mc_VehUntTrpCoUsrSel_St 1;
BA_ "U_P702_MY2021_Rx" SG_ 765 Mc_VehUntTrpCoUsrSel_St 1;
BA_ "U_U55X_MY2022_Rx" SG_ 765 Mc_VehUntTrpCoUsrSel_St 1;
BA_ "ECGUsedRxSignal" SG_ 765 Mc_VehUntTrpCoUsrSel_St 1;
BA_ "U_T6_MCA_MY2020_Rx" SG_ 765 Mc_VehUntTrpCoUsrSel_St 1;
BA_ "GenSigSendType" SG_ 765 Mc_VehUntTrpCoUsrSel_St 3;
BA_ "U_CD542_MY2021_Tx" SG_ 765 Mc_VehUnitTempUsrSel_St 1;
BA_ "U_T6_MCA_MY2020_Tx" SG_ 765 Mc_VehUnitTempUsrSel_St 1;
BA_ "U_P702_MY2021_Tx" SG_ 765 Mc_VehUnitTempUsrSel_St 1;
BA_ "U_CD542_MY2021_Rx" SG_ 765 Mc_VehUnitTempUsrSel_St 1;
BA_ "U_P702_MY2021_Rx" SG_ 765 Mc_VehUnitTempUsrSel_St 1;
BA_ "U_T6_MCA_MY2020_Rx" SG_ 765 Mc_VehUnitTempUsrSel_St 1;
BA_ "GenSigSendType" SG_ 765 Mc_VehUnitTempUsrSel_St 3;
BA_ "U_CD542_MY2021_Tx" SG_ 765 Mc_VehDayNightUsrSel_St 1;
BA_ "U_T6_MCA_MY2020_Tx" SG_ 765 Mc_VehDayNightUsrSel_St 1;
BA_ "U_CD542_MY2021_Rx" SG_ 765 Mc_VehDayNightUsrSel_St 1;
BA_ "U_T6_MCA_MY2020_Rx" SG_ 765 Mc_VehDayNightUsrSel_St 1;
BA_ "U_P702_MY2021_Rx" SG_ 765 Mc_VehDayNightUsrSel_St 1;
BA_ "GenSigSendType" SG_ 765 Mc_VehDayNightUsrSel_St 3;
BA_ "U_CD542_MY2021_Tx" SG_ 765 Mc_VehTimeFrmtUsrSel_St 1;
BA_ "U_T6_MCA_MY2020_Tx" SG_ 765 Mc_VehTimeFrmtUsrSel_St 1;
BA_ "U_CD542_MY2021_Rx" SG_ 765 Mc_VehTimeFrmtUsrSel_St 1;
BA_ "U_P702_MY2021_Rx" SG_ 765 Mc_VehTimeFrmtUsrSel_St 1;
BA_ "U_T6_MCA_MY2020_Rx" SG_ 765 Mc_VehTimeFrmtUsrSel_St 1;
BA_ "GenSigSendType" SG_ 765 Mc_VehTimeFrmtUsrSel_St 3;
BA_ "U_CD542_MY2021_Tx" SG_ 765 Mc_VehThemeUsrSel_St 1;
BA_ "U_T6_MCA_MY2020_Tx" SG_ 765 Mc_VehThemeUsrSel_St 1;
BA_ "U_CD542_MY2021_Rx" SG_ 765 Mc_VehThemeUsrSel_St 1;
BA_ "U_T6_MCA_MY2020_Rx" SG_ 765 Mc_VehThemeUsrSel_St 1;
BA_ "U_P702_MY2021_Rx" SG_ 765 Mc_VehThemeUsrSel_St 1;
BA_ "GenSigSendType" SG_ 765 Mc_VehThemeUsrSel_St 3;
BA_ "U_CD542_MY2021_Tx" SG_ 765 Mc_VehLangUsrSel_St 1;
BA_ "U_T6_MCA_MY2020_Tx" SG_ 765 Mc_VehLangUsrSel_St 1;
BA_ "U_P702_MY2021_Tx" SG_ 765 Mc_VehLangUsrSel_St 1;
BA_ "U_CD542_MY2021_Rx" SG_ 765 Mc_VehLangUsrSel_St 1;
BA_ "U_T6_MCA_MY2020_Rx" SG_ 765 Mc_VehLangUsrSel_St 1;
BA_ "U_P702_MY2021_Rx" SG_ 765 Mc_VehLangUsrSel_St 1;
BA_ "GenSigSendType" SG_ 765 Mc_VehLangUsrSel_St 3;
BA_ "U_T6_MCA_MY2020_Tx" SG_ 765 AwdRnge_D_ActlIpc 1;
BA_ "U_P702_MY2021_Tx" SG_ 765 AwdRnge_D_ActlIpc 1;
BA_ "GenSigSendType" SG_ 765 AwdRnge_D_ActlIpc 3;
BA_ "GenSigStartValue" SG_ 765 AwdRnge_D_ActlIpc 7;
BA_ "GenSigStartValueInteger" SG_ 765 AwdRnge_D_ActlIpc 7;
BA_ "U_CD542_MY2021_Tx" SG_ 765 AwdDrvMde_D_Rq 1;
BA_ "U_T6_MCA_MY2020_Tx" SG_ 765 AwdDrvMde_D_Rq 1;
BA_ "GenSigSendType" SG_ 765 AwdDrvMde_D_Rq 3;
BA_ "U_T6_MCA_MY2020_Tx" SG_ 765 EngExhMdeQuiet_D2_Rq 1;
BA_ "GenSigSendType" SG_ 765 EngExhMdeQuiet_D2_Rq 3;
BA_ "U_T6_MCA_MY2020_Tx" SG_ 765 BrkLineLck_D_Rq 1;
BA_ "GenSigSendType" SG_ 765 BrkLineLck_D_Rq 3;
BA_ "U_CD542_MY2021_Tx" SG_ 765 EdmSailMde_B_RqDrv 1;
BA_ "U_T6_MCA_MY2020_Tx" SG_ 765 EdmSailMde_B_RqDrv 1;
BA_ "GenSigSendType" SG_ 765 EdmSailMde_B_RqDrv 3;
BA_ "U_T6_MCA_MY2020_Tx" SG_ 765 Running_Board_Cmd 1;
BA_ "GenSigSendType" SG_ 765 Running_Board_Cmd 3;
BA_ "U_T6_MCA_MY2020_Tx" SG_ 508 Mc_DB1GetInfStartInd_Rq 1;
BA_ "U_T6_MCA_MY2020_Rx" SG_ 508 Mc_DB1GetInfStartInd_Rq 1;
BA_ "GenSigSendType" SG_ 508 Mc_DB1GetInfStartInd_Rq 1;
BA_ "U_T6_MCA_MY2020_Tx" SG_ 508 Mc_DB1GtInfNbrOfItms_Rq 1;
BA_ "U_T6_MCA_MY2020_Rx" SG_ 508 Mc_DB1GtInfNbrOfItms_Rq 1;
BA_ "U_T6_MCA_MY2020_Tx" SG_ 508 Mc_DB1GetInfSetConf_Rq 1;
BA_ "U_T6_MCA_MY2020_Rx" SG_ 508 Mc_DB1GetInfSetConf_Rq 1;
BA_ "U_T6_MCA_MY2020_Tx" SG_ 508 Mc_DB1GetInfSetFilt3_Rq 1;
BA_ "U_T6_MCA_MY2020_Rx" SG_ 508 Mc_DB1GetInfSetFilt3_Rq 1;
BA_ "U_T6_MCA_MY2020_Tx" SG_ 508 Mc_DB1GetInfSetFilt2_Rq 1;
BA_ "U_T6_MCA_MY2020_Rx" SG_ 508 Mc_DB1GetInfSetFilt2_Rq 1;
BA_ "U_T6_MCA_MY2020_Tx" SG_ 508 Mc_DB1GetInfSetFilt1_Rq 1;
BA_ "U_T6_MCA_MY2020_Rx" SG_ 508 Mc_DB1GetInfSetFilt1_Rq 1;
BA_ "U_T6_MCA_MY2020_Tx" SG_ 507 Mc_DB1SetTrkItmIndex_Rq 1;
BA_ "U_T6_MCA_MY2020_Rx" SG_ 507 Mc_DB1SetTrkItmIndex_Rq 1;
BA_ "GenSigSendType" SG_ 507 Mc_DB1SetTrkItmIndex_Rq 1;
BA_ "U_T6_MCA_MY2020_Tx" SG_ 507 Mc_DB1SetTrkSetConf_Rq 1;
BA_ "U_T6_MCA_MY2020_Rx" SG_ 507 Mc_DB1SetTrkSetConf_Rq 1;
BA_ "U_T6_MCA_MY2020_Tx" SG_ 507 Mc_DB1SetTrkSetFilt3_Rq 1;
BA_ "U_T6_MCA_MY2020_Rx" SG_ 507 Mc_DB1SetTrkSetFilt3_Rq 1;
BA_ "U_T6_MCA_MY2020_Tx" SG_ 507 Mc_DB1SetTrkSetFilt2_Rq 1;
BA_ "U_T6_MCA_MY2020_Rx" SG_ 507 Mc_DB1SetTrkSetFilt2_Rq 1;
BA_ "U_T6_MCA_MY2020_Tx" SG_ 507 Mc_DB1SetTrkSetFilt1_Rq 1;
BA_ "U_T6_MCA_MY2020_Rx" SG_ 507 Mc_DB1SetTrkSetFilt1_Rq 1;
BA_ "U_T6_MCA_MY2020_Tx" SG_ 506 Mc_AudioSourceSel3_Rq 1;
BA_ "U_T6_MCA_MY2020_Rx" SG_ 506 Mc_AudioSourceSel3_Rq 1;
BA_ "GenSigSendType" SG_ 506 Mc_AudioSourceSel3_Rq 3;
BA_ "U_T6_MCA_MY2020_Tx" SG_ 506 Mc_PlayFrstTrInFldr_Rq 1;
BA_ "U_T6_MCA_MY2020_Rx" SG_ 506 Mc_PlayFrstTrInFldr_Rq 1;
BA_ "U_T6_MCA_MY2020_Tx" SG_ 506 Mc_ItemIndex_Rq 1;
BA_ "U_T6_MCA_MY2020_Rx" SG_ 506 Mc_ItemIndex_Rq 1;
BA_ "U_T6_MCA_MY2020_Tx" SG_ 506 Mc_FolderNumber3_Rq 1;
BA_ "U_T6_MCA_MY2020_Rx" SG_ 506 Mc_FolderNumber3_Rq 1;
BA_ "U_T6_MCA_MY2020_Tx" SG_ 505 Mc_AudioSourceSel2_Rq 1;
BA_ "U_T6_MCA_MY2020_Rx" SG_ 505 Mc_AudioSourceSel2_Rq 1;
BA_ "GenSigSendType" SG_ 505 Mc_AudioSourceSel2_Rq 3;
BA_ "U_T6_MCA_MY2020_Tx" SG_ 505 Mc_StartItemIndexRq 1;
BA_ "U_T6_MCA_MY2020_Rx" SG_ 505 Mc_StartItemIndexRq 1;
BA_ "U_T6_MCA_MY2020_Tx" SG_ 505 Mc_NbrOfItems2_Rq 1;
BA_ "U_T6_MCA_MY2020_Rx" SG_ 505 Mc_NbrOfItems2_Rq 1;
BA_ "U_T6_MCA_MY2020_Tx" SG_ 505 Mc_ItemNameLength2_Rq 1;
BA_ "U_T6_MCA_MY2020_Rx" SG_ 505 Mc_ItemNameLength2_Rq 1;
BA_ "U_T6_MCA_MY2020_Tx" SG_ 505 Mc_CutItem2_Rq 1;
BA_ "U_T6_MCA_MY2020_Rx" SG_ 505 Mc_CutItem2_Rq 1;
BA_ "U_T6_MCA_MY2020_Tx" SG_ 505 Mc_FolderNumber2_Rq 1;
BA_ "U_T6_MCA_MY2020_Rx" SG_ 505 Mc_FolderNumber2_Rq 1;
BA_ "U_T6_MCA_MY2020_Tx" SG_ 505 Mc_FolderContent_Rq 1;
BA_ "U_T6_MCA_MY2020_Rx" SG_ 505 Mc_FolderContent_Rq 1;
BA_ "U_CD542_MY2021_Tx" SG_ 403 McLangSel2_Rq 1;
BA_ "U_T6_MCA_MY2020_Tx" SG_ 403 McLangSel2_Rq 1;
BA_ "U_T6_MCA_MY2020_Rx" SG_ 403 McLangSel2_Rq 1;
BA_ "U_P702_MY2021_Rx" SG_ 403 McLangSel2_Rq 1;
BA_ "GenSigSendType" SG_ 403 McLangSel2_Rq 3;
BA_ "U_CD542_MY2021_Tx" SG_ 403 DealerCall_B_Rq 1;
BA_ "U_T6_MCA_MY2020_Tx" SG_ 403 DealerCall_B_Rq 1;
BA_ "U_T6_MCA_MY2020_Rx" SG_ 403 DealerCall_B_Rq 1;
BA_ "GenSigSendType" SG_ 403 DealerCall_B_Rq 3;
BA_ "U_CD542_MY2021_Tx" SG_ 403 Mc_RepeatGuidance_Rq 1;
BA_ "U_T6_MCA_MY2020_Tx" SG_ 403 Mc_RepeatGuidance_Rq 1;
BA_ "U_CD542_MY2021_Rx" SG_ 403 Mc_RepeatGuidance_Rq 1;
BA_ "U_T6_MCA_MY2020_Rx" SG_ 403 Mc_RepeatGuidance_Rq 1;
BA_ "U_P702_MY2021_Rx" SG_ 403 Mc_RepeatGuidance_Rq 1;
BA_ "GenSigSendType" SG_ 403 Mc_RepeatGuidance_Rq 3;
BA_ "U_CD542_MY2021_Tx" SG_ 403 Mc_CancelRoute_Rq 1;
BA_ "U_T6_MCA_MY2020_Tx" SG_ 403 Mc_CancelRoute_Rq 1;
BA_ "U_CD542_MY2021_Rx" SG_ 403 Mc_CancelRoute_Rq 1;
BA_ "U_T6_MCA_MY2020_Rx" SG_ 403 Mc_CancelRoute_Rq 1;
BA_ "U_P702_MY2021_Rx" SG_ 403 Mc_CancelRoute_Rq 1;
BA_ "GenSigSendType" SG_ 403 Mc_CancelRoute_Rq 3;
BA_ "U_CD542_MY2021_Tx" SG_ 403 Mc_CancelCurrWaypt_Rq 1;
BA_ "U_T6_MCA_MY2020_Tx" SG_ 403 Mc_CancelCurrWaypt_Rq 1;
BA_ "U_CD542_MY2021_Rx" SG_ 403 Mc_CancelCurrWaypt_Rq 1;
BA_ "U_T6_MCA_MY2020_Rx" SG_ 403 Mc_CancelCurrWaypt_Rq 1;
BA_ "U_P702_MY2021_Rx" SG_ 403 Mc_CancelCurrWaypt_Rq 1;
BA_ "GenSigSendType" SG_ 403 Mc_CancelCurrWaypt_Rq 3;
BA_ "U_CD542_MY2021_Tx" SG_ 403 Mc_TextMessage_Rq 1;
BA_ "U_T6_MCA_MY2020_Tx" SG_ 403 Mc_TextMessage_Rq 1;
BA_ "U_T6_MCA_MY2020_Rx" SG_ 403 Mc_TextMessage_Rq 1;
BA_ "U_P702_MY2021_Rx" SG_ 403 Mc_TextMessage_Rq 1;
BA_ "GenSigSendType" SG_ 403 Mc_TextMessage_Rq 3;
BA_ "U_CD542_MY2021_Tx" SG_ 403 Mc_BTInCallOptions_Rq 1;
BA_ "U_T6_MCA_MY2020_Tx" SG_ 403 Mc_BTInCallOptions_Rq 1;
BA_ "U_CD542_MY2021_Rx" SG_ 403 Mc_BTInCallOptions_Rq 1;
BA_ "U_T6_MCA_MY2020_Rx" SG_ 403 Mc_BTInCallOptions_Rq 1;
BA_ "U_P702_MY2021_Rx" SG_ 403 Mc_BTInCallOptions_Rq 1;
BA_ "GenSigSendType" SG_ 403 Mc_BTInCallOptions_Rq 3;
BA_ "U_CD542_MY2021_Tx" SG_ 403 Mc_PhMicrophoneMute_Rq 1;
BA_ "U_T6_MCA_MY2020_Tx" SG_ 403 Mc_PhMicrophoneMute_Rq 1;
BA_ "U_CD542_MY2021_Rx" SG_ 403 Mc_PhMicrophoneMute_Rq 1;
BA_ "U_T6_MCA_MY2020_Rx" SG_ 403 Mc_PhMicrophoneMute_Rq 1;
BA_ "U_P702_MY2021_Rx" SG_ 403 Mc_PhMicrophoneMute_Rq 1;
BA_ "GenSigSendType" SG_ 403 Mc_PhMicrophoneMute_Rq 3;
BA_ "U_CD542_MY2021_Tx" SG_ 403 Mc_LangSel_Rq 1;
BA_ "U_T6_MCA_MY2020_Tx" SG_ 403 Mc_LangSel_Rq 1;
BA_ "U_P702_MY2021_Tx" SG_ 403 Mc_LangSel_Rq 1;
BA_ "U_CD542_MY2021_Rx" SG_ 403 Mc_LangSel_Rq 1;
BA_ "U_T6_MCA_MY2020_Rx" SG_ 403 Mc_LangSel_Rq 1;
BA_ "U_P702_MY2021_Rx" SG_ 403 Mc_LangSel_Rq 1;
BA_ "GenSigSendType" SG_ 403 Mc_LangSel_Rq 3;
BA_ "U_CD542_MY2021_Tx" SG_ 401 Bezel_Beeps_Rq 1;
BA_ "U_T6_MCA_MY2020_Tx" SG_ 401 Bezel_Beeps_Rq 1;
BA_ "U_P702_MY2021_Tx" SG_ 401 Bezel_Beeps_Rq 1;
BA_ "GenSigSendType" SG_ 401 Bezel_Beeps_Rq 3;
BA_ "WakeupSignal" SG_ 401 Bezel_Beeps_Rq 1;
BA_ "U_CD542_MY2021_Tx" SG_ 401 Disp_VehUntTripCoUsrSel 1;
BA_ "U_T6_MCA_MY2020_Tx" SG_ 401 Disp_VehUntTripCoUsrSel 1;
BA_ "U_P702_MY2021_Tx" SG_ 401 Disp_VehUntTripCoUsrSel 1;
BA_ "U_CD542_MY2021_Rx" SG_ 401 Disp_VehUntTripCoUsrSel 1;
BA_ "U_T6_MCA_MY2020_Rx" SG_ 401 Disp_VehUntTripCoUsrSel 1;
BA_ "U_P702_MY2021_Rx" SG_ 401 Disp_VehUntTripCoUsrSel 1;
BA_ "GenSigSendType" SG_ 401 Disp_VehUntTripCoUsrSel 3;
BA_ "GenSigStartValue" SG_ 401 Disp_VehUntTripCoUsrSel 3;
BA_ "GenSigStartValueInteger" SG_ 401 Disp_VehUntTripCoUsrSel 3;
BA_ "U_CD542_MY2021_Tx" SG_ 401 Disp_VehUnitTempUsrSel 1;
BA_ "U_T6_MCA_MY2020_Tx" SG_ 401 Disp_VehUnitTempUsrSel 1;
BA_ "U_P702_MY2021_Tx" SG_ 401 Disp_VehUnitTempUsrSel 1;
BA_ "U_CD542_MY2021_Rx" SG_ 401 Disp_VehUnitTempUsrSel 1;
BA_ "U_T6_MCA_MY2020_Rx" SG_ 401 Disp_VehUnitTempUsrSel 1;
BA_ "U_P702_MY2021_Rx" SG_ 401 Disp_VehUnitTempUsrSel 1;
BA_ "GenSigSendType" SG_ 401 Disp_VehUnitTempUsrSel 3;
BA_ "GenSigStartValue" SG_ 401 Disp_VehUnitTempUsrSel 3;
BA_ "GenSigStartValueInteger" SG_ 401 Disp_VehUnitTempUsrSel 3;
BA_ "U_CD542_MY2021_Tx" SG_ 401 Disp_LangSel_Rq 1;
BA_ "U_T6_MCA_MY2020_Tx" SG_ 401 Disp_LangSel_Rq 1;
BA_ "U_P702_MY2021_Tx" SG_ 401 Disp_LangSel_Rq 1;
BA_ "U_CD542_MY2021_Rx" SG_ 401 Disp_LangSel_Rq 1;
BA_ "U_T6_MCA_MY2020_Rx" SG_ 401 Disp_LangSel_Rq 1;
BA_ "U_P702_MY2021_Rx" SG_ 401 Disp_LangSel_Rq 1;
BA_ "GenSigSendType" SG_ 401 Disp_LangSel_Rq 3;
BA_ "U_CD542_MY2021_Tx" SG_ 401 Disp_LangSel2_Rq 1;
BA_ "U_T6_MCA_MY2020_Tx" SG_ 401 Disp_LangSel2_Rq 1;
BA_ "U_P702_MY2021_Tx" SG_ 401 Disp_LangSel2_Rq 1;
BA_ "U_CD542_MY2021_Rx" SG_ 401 Disp_LangSel2_Rq 1;
BA_ "U_T6_MCA_MY2020_Rx" SG_ 401 Disp_LangSel2_Rq 1;
BA_ "U_P702_MY2021_Rx" SG_ 401 Disp_LangSel2_Rq 1;
BA_ "GenSigSendType" SG_ 401 Disp_LangSel2_Rq 3;
BA_ "U_CD542_MY2021_Rx" SG_ 1143 ConsTipUnitPt_D_Dsply 1;
BA_ "U_T6_MCA_MY2020_Rx" SG_ 1143 ConsTipUnitPt_D_Dsply 1;
BA_ "U_P702_MY2021_Rx" SG_ 1143 ConsTipUnitPt_D_Dsply 1;
BA_ "GenSigStartValue" SG_ 1143 ConsTipTot_Pc_Dsply 1022;
BA_ "GenSigStartValueInteger" SG_ 1143 ConsTipTot_Pc_Dsply 1022;
BA_ "U_CD542_MY2021_Rx" SG_ 1143 ChrgCompltMsgTxt_D_Rq 1;
BA_ "U_T6_MCA_MY2020_Rx" SG_ 1143 ChrgCompltMsgTxt_D_Rq 1;
BA_ "U_P702_MY2021_Rx" SG_ 1143 ChrgCompltMsgTxt_D_Rq 1;
BA_ "U_CD542_MY2021_Rx" SG_ 1142 ConsTipV_No_Dsply 1;
BA_ "U_T6_MCA_MY2020_Rx" SG_ 1142 ConsTipV_No_Dsply 1;
BA_ "U_P702_MY2021_Rx" SG_ 1142 ConsTipV_No_Dsply 1;
BA_ "U_CD542_MY2021_Rx" SG_ 1142 ConsTipMsg3_D_Dsply 1;
BA_ "U_T6_MCA_MY2020_Rx" SG_ 1142 ConsTipMsg3_D_Dsply 1;
BA_ "U_P702_MY2021_Rx" SG_ 1142 ConsTipMsg3_D_Dsply 1;
BA_ "U_CD542_MY2021_Rx" SG_ 1142 ConsTipMsg2_D_Dsply 1;
BA_ "U_T6_MCA_MY2020_Rx" SG_ 1142 ConsTipMsg2_D_Dsply 1;
BA_ "U_P702_MY2021_Rx" SG_ 1142 ConsTipMsg2_D_Dsply 1;
BA_ "U_CD542_MY2021_Rx" SG_ 1142 ConsTipMsg1_D_Dsply 1;
BA_ "U_T6_MCA_MY2020_Rx" SG_ 1142 ConsTipMsg1_D_Dsply 1;
BA_ "U_P702_MY2021_Rx" SG_ 1142 ConsTipMsg1_D_Dsply 1;
BA_ "U_CD542_MY2021_Rx" SG_ 1142 ConsTipDecel_No_Dsply 1;
BA_ "U_T6_MCA_MY2020_Rx" SG_ 1142 ConsTipDecel_No_Dsply 1;
BA_ "U_P702_MY2021_Rx" SG_ 1142 ConsTipDecel_No_Dsply 1;
BA_ "U_CD542_MY2021_Rx" SG_ 1142 ConsTipA_No_Dsply 1;
BA_ "U_T6_MCA_MY2020_Rx" SG_ 1142 ConsTipA_No_Dsply 1;
BA_ "U_P702_MY2021_Rx" SG_ 1142 ConsTipA_No_Dsply 1;
BA_ "U_P702_MY2021_Rx" SG_ 947 Outside_Air_Temp_Stat_UB 1;
BA_ "U_CD542_MY2021_Rx" SG_ 947 Outside_Air_Temp_Stat_UB 1;
BA_ "U_T6_MCA_MY2020_Rx" SG_ 947 Outside_Air_Temp_Stat_UB 1;
BA_ "U_P702_MY2021_Rx" SG_ 947 Outside_Air_Temp_Stat 1;
BA_ "U_CD542_MY2021_Rx" SG_ 947 Outside_Air_Temp_Stat 1;
BA_ "U_T6_MCA_MY2020_Rx" SG_ 947 Outside_Air_Temp_Stat 1;
BA_ "GenSigSendType" SG_ 947 Outside_Air_Temp_Stat 3;
BA_ "GenSigStartValue" SG_ 947 Outside_Air_Temp_Stat 254;
BA_ "GenSigStartValueInteger" SG_ 947 Outside_Air_Temp_Stat 254;
BA_ "U_T6_MCA_MY2020_Rx" SG_ 973 LaSysOffStat_D_Dsply 1;
BA_ "U_CD542_MY2021_Rx" SG_ 973 TsrVl1RstrcMsgTxt2_D_Rq 1;
BA_ "U_T6_MCA_MY2020_Rx" SG_ 973 TsrVl1RstrcMsgTxt2_D_Rq 1;
BA_ "U_P702_MY2021_Rx" SG_ 973 TsrVl1RstrcMsgTxt2_D_Rq 1;
BA_ "GenSigStartValue" SG_ 973 TsrVl1RstrcMsgTxt2_D_Rq 1;
BA_ "GenSigStartValueInteger" SG_ 973 TsrVl1RstrcMsgTxt2_D_Rq 1;
BA_ "U_CD542_MY2021_Rx" SG_ 973 TsrVl2RstrcMsgTxt2_D_Rq 1;
BA_ "U_T6_MCA_MY2020_Rx" SG_ 973 TsrVl2RstrcMsgTxt2_D_Rq 1;
BA_ "U_P702_MY2021_Rx" SG_ 973 TsrVl2RstrcMsgTxt2_D_Rq 1;
BA_ "GenSigStartValue" SG_ 973 TsrVl2RstrcMsgTxt2_D_Rq 1;
BA_ "GenSigStartValueInteger" SG_ 973 TsrVl2RstrcMsgTxt2_D_Rq 1;
BA_ "U_CD542_MY2021_Rx" SG_ 973 TsrVl2PrmntMsgTxt_D_Rq 1;
BA_ "U_T6_MCA_MY2020_Rx" SG_ 973 TsrVl2PrmntMsgTxt_D_Rq 1;
BA_ "U_P702_MY2021_Rx" SG_ 973 TsrVl2PrmntMsgTxt_D_Rq 1;
BA_ "U_CD542_MY2021_Rx" SG_ 973 TsrVl1PrmntMsgTxt_D_Rq 1;
BA_ "U_T6_MCA_MY2020_Rx" SG_ 973 TsrVl1PrmntMsgTxt_D_Rq 1;
BA_ "U_P702_MY2021_Rx" SG_ 973 TsrVl1PrmntMsgTxt_D_Rq 1;
BA_ "U_CD542_MY2021_Rx" SG_ 973 TsrOvtkMsgTxt2_D_Rq 1;
BA_ "U_T6_MCA_MY2020_Rx" SG_ 973 TsrOvtkMsgTxt2_D_Rq 1;
BA_ "U_P702_MY2021_Rx" SG_ 973 TsrOvtkMsgTxt2_D_Rq 1;
BA_ "U_CD542_MY2021_Rx" SG_ 973 WwaWarn_B_Rq 1;
BA_ "U_T6_MCA_MY2020_Rx" SG_ 973 WwaWarn_B_Rq 1;
BA_ "U_CD542_MY2021_Rx" SG_ 973 TsrVlUnitMsgTxt_D_Rq 1;
BA_ "U_T6_MCA_MY2020_Rx" SG_ 973 TsrVlUnitMsgTxt_D_Rq 1;
BA_ "U_P702_MY2021_Rx" SG_ 973 TsrVlUnitMsgTxt_D_Rq 1;
BA_ "GenSigStartValue" SG_ 973 TsrVlUnitMsgTxt_D_Rq 2;
BA_ "GenSigStartValueInteger" SG_ 973 TsrVlUnitMsgTxt_D_Rq 2;
BA_ "U_CD542_MY2021_Rx" SG_ 973 TsrVLim2MsgTxt_D_Rq 1;
BA_ "U_T6_MCA_MY2020_Rx" SG_ 973 TsrVLim2MsgTxt_D_Rq 1;
BA_ "U_P702_MY2021_Rx" SG_ 973 TsrVLim2MsgTxt_D_Rq 1;
BA_ "GenSigStartValue" SG_ 973 TsrVLim2MsgTxt_D_Rq 255;
BA_ "GenSigStartValueInteger" SG_ 973 TsrVLim2MsgTxt_D_Rq 255;
BA_ "U_CD542_MY2021_Rx" SG_ 973 TsrVLim1MsgTxt_D_Rq 1;
BA_ "U_T6_MCA_MY2020_Rx" SG_ 973 TsrVLim1MsgTxt_D_Rq 1;
BA_ "U_P702_MY2021_Rx" SG_ 973 TsrVLim1MsgTxt_D_Rq 1;
BA_ "GenSigStartValue" SG_ 973 TsrVLim1MsgTxt_D_Rq 255;
BA_ "GenSigStartValueInteger" SG_ 973 TsrVLim1MsgTxt_D_Rq 255;
BA_ "U_CD542_MY2021_Rx" SG_ 973 TsrVl2StatMsgTxt_D_Rq 1;
BA_ "U_T6_MCA_MY2020_Rx" SG_ 973 TsrVl2StatMsgTxt_D_Rq 1;
BA_ "U_P702_MY2021_Rx" SG_ 973 TsrVl2StatMsgTxt_D_Rq 1;
BA_ "U_CD542_MY2021_Rx" SG_ 973 TsrVl2RstrcMsgTxt_D_Rq 1;
BA_ "U_T6_MCA_MY2020_Rx" SG_ 973 TsrVl2RstrcMsgTxt_D_Rq 1;
BA_ "U_CD542_MY2021_Rx" SG_ 973 TsrVl1StatMsgTxt_D_Rq 1;
BA_ "U_T6_MCA_MY2020_Rx" SG_ 973 TsrVl1StatMsgTxt_D_Rq 1;
BA_ "U_P702_MY2021_Rx" SG_ 973 TsrVl1StatMsgTxt_D_Rq 1;
BA_ "U_CD542_MY2021_Rx" SG_ 973 TsrVl1RstrcMsgTxt_D_Rq 1;
BA_ "U_T6_MCA_MY2020_Rx" SG_ 973 TsrVl1RstrcMsgTxt_D_Rq 1;
BA_ "U_CD542_MY2021_Rx" SG_ 973 TsrStatMsgTxt_D_Rq 1;
BA_ "U_T6_MCA_MY2020_Rx" SG_ 973 TsrStatMsgTxt_D_Rq 1;
BA_ "U_CD542_MY2021_Rx" SG_ 973 TsrOvtkStatMsgTxt_D_Rq 1;
BA_ "U_T6_MCA_MY2020_Rx" SG_ 973 TsrOvtkStatMsgTxt_D_Rq 1;
BA_ "U_P702_MY2021_Rx" SG_ 973 TsrOvtkStatMsgTxt_D_Rq 1;
BA_ "U_CD542_MY2021_Rx" SG_ 973 TsrOvtkMsgTxt_D_Rq 1;
BA_ "U_T6_MCA_MY2020_Rx" SG_ 973 TsrOvtkMsgTxt_D_Rq 1;
BA_ "U_P702_MY2021_Rx" SG_ 973 TsrOvtkMsgTxt_D_Rq 1;
BA_ "GenSigStartValue" SG_ 973 TsrOvtkMsgTxt_D_Rq 1;
BA_ "GenSigStartValueInteger" SG_ 973 TsrOvtkMsgTxt_D_Rq 1;
BA_ "U_CD542_MY2021_Rx" SG_ 973 TsrOswWarnMsgTxt_D_Rq 1;
BA_ "U_T6_MCA_MY2020_Rx" SG_ 973 TsrOswWarnMsgTxt_D_Rq 1;
BA_ "GenSigStartValue" SG_ 973 TsrOswWarnMsgTxt_D_Rq 1;
BA_ "GenSigStartValueInteger" SG_ 973 TsrOswWarnMsgTxt_D_Rq 1;
BA_ "U_CD542_MY2021_Rx" SG_ 973 TsrMsgTxt_D_Rq 1;
BA_ "U_T6_MCA_MY2020_Rx" SG_ 973 TsrMsgTxt_D_Rq 1;
BA_ "U_P702_MY2021_Rx" SG_ 973 TsrMsgTxt_D_Rq 1;
BA_ "GenSigStartValue" SG_ 973 TsrMsgTxt_D_Rq 1;
BA_ "GenSigStartValueInteger" SG_ 973 TsrMsgTxt_D_Rq 1;
BA_ "U_CD542_MY2021_Tx" SG_ 405 LBC1_StartItemInd 1;
BA_ "U_T6_MCA_MY2020_Tx" SG_ 405 LBC1_StartItemInd 1;
BA_ "U_CD542_MY2021_Rx" SG_ 405 LBC1_StartItemInd 1;
BA_ "U_T6_MCA_MY2020_Rx" SG_ 405 LBC1_StartItemInd 1;
BA_ "U_P702_MY2021_Rx" SG_ 405 LBC1_StartItemInd 1;
BA_ "GenSigSendType" SG_ 405 LBC1_StartItemInd 3;
BA_ "U_CD542_MY2021_Tx" SG_ 405 LBC1_SetListServ 1;
BA_ "U_T6_MCA_MY2020_Tx" SG_ 405 LBC1_SetListServ 1;
BA_ "U_CD542_MY2021_Rx" SG_ 405 LBC1_SetListServ 1;
BA_ "U_T6_MCA_MY2020_Rx" SG_ 405 LBC1_SetListServ 1;
BA_ "U_P702_MY2021_Rx" SG_ 405 LBC1_SetListServ 1;
BA_ "GenSigSendType" SG_ 405 LBC1_SetListServ 3;
BA_ "U_CD542_MY2021_Tx" SG_ 405 LBC1_Opcode 1;
BA_ "U_T6_MCA_MY2020_Tx" SG_ 405 LBC1_Opcode 1;
BA_ "U_CD542_MY2021_Rx" SG_ 405 LBC1_Opcode 1;
BA_ "U_T6_MCA_MY2020_Rx" SG_ 405 LBC1_Opcode 1;
BA_ "U_P702_MY2021_Rx" SG_ 405 LBC1_Opcode 1;
BA_ "GenSigSendType" SG_ 405 LBC1_Opcode 3;
BA_ "U_CD542_MY2021_Tx" SG_ 405 LBC1_NbrOfItems 1;
BA_ "U_T6_MCA_MY2020_Tx" SG_ 405 LBC1_NbrOfItems 1;
BA_ "U_CD542_MY2021_Rx" SG_ 405 LBC1_NbrOfItems 1;
BA_ "U_T6_MCA_MY2020_Rx" SG_ 405 LBC1_NbrOfItems 1;
BA_ "U_P702_MY2021_Rx" SG_ 405 LBC1_NbrOfItems 1;
BA_ "GenSigSendType" SG_ 405 LBC1_NbrOfItems 3;
BA_ "U_CD542_MY2021_Tx" SG_ 405 LBC1_ItemIndex 1;
BA_ "U_T6_MCA_MY2020_Tx" SG_ 405 LBC1_ItemIndex 1;
BA_ "U_CD542_MY2021_Rx" SG_ 405 LBC1_ItemIndex 1;
BA_ "U_T6_MCA_MY2020_Rx" SG_ 405 LBC1_ItemIndex 1;
BA_ "U_P702_MY2021_Rx" SG_ 405 LBC1_ItemIndex 1;
BA_ "GenSigSendType" SG_ 405 LBC1_ItemIndex 3;
BA_ "U_CD542_MY2021_Tx" SG_ 405 LBC1_ActiveListID 1;
BA_ "U_T6_MCA_MY2020_Tx" SG_ 405 LBC1_ActiveListID 1;
BA_ "U_CD542_MY2021_Rx" SG_ 405 LBC1_ActiveListID 1;
BA_ "U_T6_MCA_MY2020_Rx" SG_ 405 LBC1_ActiveListID 1;
BA_ "U_P702_MY2021_Rx" SG_ 405 LBC1_ActiveListID 1;
BA_ "GenSigSendType" SG_ 405 LBC1_ActiveListID 3;
BA_ "U_CD542_MY2021_Tx" SG_ 756 AdjustableChimeVol2_Rq 1;
BA_ "U_T6_MCA_MY2020_Tx" SG_ 756 AdjustableChimeVol2_Rq 1;
BA_ "U_T6_MCA_MY2020_Rx" SG_ 756 AdjustableChimeVol2_Rq 1;
BA_ "GenSigSendType" SG_ 756 AdjustableChimeVol2_Rq 3;
BA_ "U_CD542_MY2021_Tx" SG_ 756 Off_Time_Btwn_Chime2 1;
BA_ "U_T6_MCA_MY2020_Tx" SG_ 756 Off_Time_Btwn_Chime2 1;
BA_ "U_P702_MY2021_Tx" SG_ 756 Off_Time_Btwn_Chime2 1;
BA_ "U_CD542_MY2021_Rx" SG_ 756 Off_Time_Btwn_Chime2 1;
BA_ "U_T6_MCA_MY2020_Rx" SG_ 756 Off_Time_Btwn_Chime2 1;
BA_ "U_P702_MY2021_Rx" SG_ 756 Off_Time_Btwn_Chime2 1;
BA_ "U_CD542_MY2021_Tx" SG_ 756 Chime_Vol_Level2 1;
BA_ "U_T6_MCA_MY2020_Tx" SG_ 756 Chime_Vol_Level2 1;
BA_ "U_P702_MY2021_Tx" SG_ 756 Chime_Vol_Level2 1;
BA_ "U_CD542_MY2021_Rx" SG_ 756 Chime_Vol_Level2 1;
BA_ "U_T6_MCA_MY2020_Rx" SG_ 756 Chime_Vol_Level2 1;
BA_ "U_P702_MY2021_Rx" SG_ 756 Chime_Vol_Level2 1;
BA_ "U_CD542_MY2021_Tx" SG_ 756 Chime_Time_Criticality2 1;
BA_ "U_T6_MCA_MY2020_Tx" SG_ 756 Chime_Time_Criticality2 1;
BA_ "U_P702_MY2021_Tx" SG_ 756 Chime_Time_Criticality2 1;
BA_ "U_CD542_MY2021_Rx" SG_ 756 Chime_Time_Criticality2 1;
BA_ "U_T6_MCA_MY2020_Rx" SG_ 756 Chime_Time_Criticality2 1;
BA_ "U_P702_MY2021_Rx" SG_ 756 Chime_Time_Criticality2 1;
BA_ "GenSigSendType" SG_ 756 Chime_Time_Criticality2 3;
BA_ "U_CD542_MY2021_Tx" SG_ 756 Chime_Occurence2 1;
BA_ "U_T6_MCA_MY2020_Tx" SG_ 756 Chime_Occurence2 1;
BA_ "U_P702_MY2021_Tx" SG_ 756 Chime_Occurence2 1;
BA_ "U_CD542_MY2021_Rx" SG_ 756 Chime_Occurence2 1;
BA_ "U_T6_MCA_MY2020_Rx" SG_ 756 Chime_Occurence2 1;
BA_ "U_P702_MY2021_Rx" SG_ 756 Chime_Occurence2 1;
BA_ "GenSigSendType" SG_ 756 Chime_Occurence2 3;
BA_ "U_CD542_MY2021_Tx" SG_ 756 Chime_Directionality2 1;
BA_ "U_T6_MCA_MY2020_Tx" SG_ 756 Chime_Directionality2 1;
BA_ "U_P702_MY2021_Tx" SG_ 756 Chime_Directionality2 1;
BA_ "U_CD542_MY2021_Rx" SG_ 756 Chime_Directionality2 1;
BA_ "U_T6_MCA_MY2020_Rx" SG_ 756 Chime_Directionality2 1;
BA_ "U_P702_MY2021_Rx" SG_ 756 Chime_Directionality2 1;
BA_ "GenSigSendType" SG_ 756 Chime_Directionality2 3;
BA_ "U_CD542_MY2021_Tx" SG_ 756 Chime2 1;
BA_ "U_T6_MCA_MY2020_Tx" SG_ 756 Chime2 1;
BA_ "U_P702_MY2021_Tx" SG_ 756 Chime2 1;
BA_ "U_CD542_MY2021_Rx" SG_ 756 Chime2 1;
BA_ "U_T6_MCA_MY2020_Rx" SG_ 756 Chime2 1;
BA_ "U_P702_MY2021_Rx" SG_ 756 Chime2 1;
BA_ "U_CD542_MY2021_Tx" SG_ 756 Chime2Id_No_Rq 1;
BA_ "U_T6_MCA_MY2020_Tx" SG_ 756 Chime2Id_No_Rq 1;
BA_ "U_P702_MY2021_Tx" SG_ 756 Chime2Id_No_Rq 1;
BA_ "U_P702_MY2021_Rx" SG_ 756 Chime2Id_No_Rq 1;
BA_ "U_T6_MCA_MY2020_Rx" SG_ 756 Chime2Id_No_Rq 1;
BA_ "GenSigSendType" SG_ 756 Chime2Id_No_Rq 3;
BA_ "U_CD542_MY2021_Tx" SG_ 544 ChimeId_No_Rq 1;
BA_ "U_T6_MCA_MY2020_Tx" SG_ 544 ChimeId_No_Rq 1;
BA_ "U_T6_MCA_MY2020_Rx" SG_ 544 ChimeId_No_Rq 1;
BA_ "GenSigSendType" SG_ 544 ChimeId_No_Rq 3;
BA_ "U_CD542_MY2021_Tx" SG_ 544 AdjustableChimeVol_Rq 1;
BA_ "U_T6_MCA_MY2020_Tx" SG_ 544 AdjustableChimeVol_Rq 1;
BA_ "U_T6_MCA_MY2020_Rx" SG_ 544 AdjustableChimeVol_Rq 1;
BA_ "GenSigSendType" SG_ 544 AdjustableChimeVol_Rq 3;
BA_ "U_CD542_MY2021_Tx" SG_ 544 Chime_Occurence 1;
BA_ "U_T6_MCA_MY2020_Tx" SG_ 544 Chime_Occurence 1;
BA_ "U_P702_MY2021_Tx" SG_ 544 Chime_Occurence 1;
BA_ "U_CD542_MY2021_Rx" SG_ 544 Chime_Occurence 1;
BA_ "U_T6_MCA_MY2020_Rx" SG_ 544 Chime_Occurence 1;
BA_ "U_P702_MY2021_Rx" SG_ 544 Chime_Occurence 1;
BA_ "GenSigSendType" SG_ 544 Chime_Occurence 3;
BA_ "U_CD542_MY2021_Tx" SG_ 544 Off_Time_Btwn_Chime 1;
BA_ "U_T6_MCA_MY2020_Tx" SG_ 544 Off_Time_Btwn_Chime 1;
BA_ "U_P702_MY2021_Tx" SG_ 544 Off_Time_Btwn_Chime 1;
BA_ "U_CD542_MY2021_Rx" SG_ 544 Off_Time_Btwn_Chime 1;
BA_ "U_T6_MCA_MY2020_Rx" SG_ 544 Off_Time_Btwn_Chime 1;
BA_ "U_P702_MY2021_Rx" SG_ 544 Off_Time_Btwn_Chime 1;
BA_ "U_CD542_MY2021_Tx" SG_ 544 Chime_Time_Criticality 1;
BA_ "U_T6_MCA_MY2020_Tx" SG_ 544 Chime_Time_Criticality 1;
BA_ "U_P702_MY2021_Tx" SG_ 544 Chime_Time_Criticality 1;
BA_ "U_CD542_MY2021_Rx" SG_ 544 Chime_Time_Criticality 1;
BA_ "U_T6_MCA_MY2020_Rx" SG_ 544 Chime_Time_Criticality 1;
BA_ "U_P702_MY2021_Rx" SG_ 544 Chime_Time_Criticality 1;
BA_ "GenSigSendType" SG_ 544 Chime_Time_Criticality 3;
BA_ "U_CD542_MY2021_Tx" SG_ 544 Chime_Directionality 1;
BA_ "U_T6_MCA_MY2020_Tx" SG_ 544 Chime_Directionality 1;
BA_ "U_P702_MY2021_Tx" SG_ 544 Chime_Directionality 1;
BA_ "U_CD542_MY2021_Rx" SG_ 544 Chime_Directionality 1;
BA_ "U_T6_MCA_MY2020_Rx" SG_ 544 Chime_Directionality 1;
BA_ "U_P702_MY2021_Rx" SG_ 544 Chime_Directionality 1;
BA_ "GenSigSendType" SG_ 544 Chime_Directionality 3;
BA_ "U_CD542_MY2021_Tx" SG_ 544 Chime_Vol_Level 1;
BA_ "U_T6_MCA_MY2020_Tx" SG_ 544 Chime_Vol_Level 1;
BA_ "U_P702_MY2021_Tx" SG_ 544 Chime_Vol_Level 1;
BA_ "U_CD542_MY2021_Rx" SG_ 544 Chime_Vol_Level 1;
BA_ "U_T6_MCA_MY2020_Rx" SG_ 544 Chime_Vol_Level 1;
BA_ "U_P702_MY2021_Rx" SG_ 544 Chime_Vol_Level 1;
BA_ "U_CD542_MY2021_Tx" SG_ 544 Chime 1;
BA_ "U_T6_MCA_MY2020_Tx" SG_ 544 Chime 1;
BA_ "U_P702_MY2021_Tx" SG_ 544 Chime 1;
BA_ "U_CD542_MY2021_Rx" SG_ 544 Chime 1;
BA_ "U_T6_MCA_MY2020_Rx" SG_ 544 Chime 1;
BA_ "U_P702_MY2021_Rx" SG_ 544 Chime 1;
BA_ "WakeupSignal" SG_ 544 Chime 1;
BA_ "U_CD542_MY2021_Tx" SG_ 291 LangUpdate_Rsp 1;
BA_ "U_T6_MCA_MY2020_Tx" SG_ 291 LangUpdate_Rsp 1;
BA_ "U_P702_MY2021_Tx" SG_ 291 LangUpdate_Rsp 1;
BA_ "U_CD542_MY2021_Rx" SG_ 291 LangUpdate_Rsp 1;
BA_ "U_T6_MCA_MY2020_Rx" SG_ 291 LangUpdate_Rsp 1;
BA_ "GenSigSendType" SG_ 291 LangUpdate_Rsp 3;
BA_ "U_T6_MCA_MY2020_Rx" SG_ 400 Mc_SetCurrStatMCCh_Rq 1;
BA_ "U_T6_MCA_MY2020_Rx" SG_ 400 Mc_SetCurrntStatFreq_Rq 1;
BA_ "U_T6_MCA_MY2020_Rx" SG_ 400 Mc_SetCurrentStatOp_Rq 1;
BA_ "GenSigSendType" SG_ 400 Mc_SetCurrentStatOp_Rq 3;
BA_ "U_T6_MCA_MY2020_Tx" SG_ 400 Mc_PerTUStartIndex2_Rq 1;
BA_ "U_CD542_MY2021_Rx" SG_ 400 Mc_PerTUStartIndex2_Rq 1;
BA_ "U_T6_MCA_MY2020_Rx" SG_ 400 Mc_PerTUStartIndex2_Rq 1;
BA_ "U_T6_MCA_MY2020_Tx" SG_ 400 Mc_PerTUPresetArea_Rq 1;
BA_ "U_CD542_MY2021_Rx" SG_ 400 Mc_PerTUPresetArea_Rq 1;
BA_ "U_T6_MCA_MY2020_Rx" SG_ 400 Mc_PerTUPresetArea_Rq 1;
BA_ "GenSigSendType" SG_ 400 Mc_PerTUPresetArea_Rq 3;
BA_ "U_T6_MCA_MY2020_Tx" SG_ 400 Mc_PerTUNbrOfPresets_Rq 1;
BA_ "U_CD542_MY2021_Rx" SG_ 400 Mc_PerTUNbrOfPresets_Rq 1;
BA_ "U_T6_MCA_MY2020_Rx" SG_ 400 Mc_PerTUNbrOfPresets_Rq 1;
BA_ "U_T6_MCA_MY2020_Rx" SG_ 647 HEC_BTIncomingCall_Rq 1;
BA_ "GenSigSendType" SG_ 647 HEC_BTIncomingCall_Rq 3;
BA_ "U_T6_MCA_MY2020_Rx" SG_ 647 HEC_BTEndTelService_Rq 1;
BA_ "GenSigSendType" SG_ 647 HEC_BTEndTelService_Rq 3;
VAL_ 1056 AutoEpbButtnOn_B_Stat 1 "On" 0 "Off" ;
VAL_ 1056 PrkBrkElRleas_B_RqApa 1 "Yes" 0 "No" ;
VAL_ 1056 AutoEpbMsgTxt_D_Rq 7 "Message7" 6 "Message6" 5 "Message5" 4 "Message4" 3 "Message3" 2 "Message2" 1 "Message1" 0 "NoMessage" ;
VAL_ 1056 AutoEpbDsply_D_Stat 3 "NotUsed" 2 "GreyedOut" 1 "Available" 0 "NotAvailable" ;
VAL_ 1056 SelDrvMdePos12_B_Avail 1 "Available" 0 "NotAvailable" ;
VAL_ 1056 SelDrvMdePos11_B_Avail 1 "Available" 0 "NotAvailable" ;
VAL_ 1056 SelDrvMdePos10_B_Avail 1 "Available" 0 "NotAvailable" ;
VAL_ 1056 SelDrvMdePos09_B_Avail 1 "Available" 0 "NotAvailable" ;
VAL_ 1056 SelDrvMdePos08_B_Avail 1 "Available" 0 "NotAvailable" ;
VAL_ 1056 SelDrvMdePos07_B_Avail 1 "Available" 0 "NotAvailable" ;
VAL_ 1056 SelDrvMdePos06_B_Avail 1 "Available" 0 "NotAvailable" ;
VAL_ 1056 SelDrvMdePos05_B_Avail 1 "Available" 0 "NotAvailable" ;
VAL_ 1056 SelDrvMdePos04_B_Avail 1 "Available" 0 "NotAvailable" ;
VAL_ 1056 SelDrvMdePos03_B_Avail 1 "Available" 0 "NotAvailable" ;
VAL_ 1056 SelDrvMdePos02_B_Avail 1 "Available" 0 "NotAvailable" ;
VAL_ 1056 SelDrvMdePos01_B_Avail 1 "Available" 0 "NotAvailable" ;
VAL_ 1056 ActvDrvMde_D2_Stat 31 "Faulty" 30 "SelDrvMde31" 29 "SelDrvMde30" 28 "SelDrvMde29" 27 "SelDrvMde28" 26 "SelDrvMde27" 25 "SelDrvMde26" 24 "SelDrvMde25" 23 "SelDrvMde24" 22 "SelDrvMde23" 21 "SelDrvMde22" 20 "SelDrvMde21" 19 "SelDrvMde20" 18 "SelDrvMde19" 17 "SelDrvMde18" 16 "SelDrvMde17" 15 "SelDrvMde16" 14 "SelDrvMde15" 13 "SelDrvMde14" 12 "SelDrvMde13" 11 "SelDrvMde12" 10 "SelDrvMde11" 9 "SelDrvMde10" 8 "SelDrvMde09" 7 "SelDrvMde08" 6 "SelDrvMde07" 5 "SelDrvMde06" 4 "SelDrvMde05" 3 "SelDrvMde04" 2 "SelDrvMde03" 1 "SelDrvMde02" 0 "SelDrvMde01" ;
VAL_ 1056 SelDrvMde_D2_Rq 31 "Faulty" 30 "SelDrvMde31" 29 "SelDrvMde30" 28 "SelDrvMde29" 27 "SelDrvMde28" 26 "SelDrvMde27" 25 "SelDrvMde26" 24 "SelDrvMde25" 23 "SelDrvMde24" 22 "SelDrvMde23" 21 "SelDrvMde22" 20 "SelDrvMde21" 19 "SelDrvMde20" 18 "SelDrvMde19" 17 "SelDrvMde18" 16 "SelDrvMde17" 15 "SelDrvMde16" 14 "SelDrvMde15" 13 "SelDrvMde14" 12 "SelDrvMde13" 11 "SelDrvMde12" 10 "SelDrvMde11" 9 "SelDrvMde10" 8 "SelDrvMde09" 7 "SelDrvMde08" 6 "SelDrvMde07" 5 "SelDrvMde06" 4 "SelDrvMde05" 3 "SelDrvMde04" 2 "SelDrvMde03" 1 "SelDrvMde02" 0 "SelDrvMde01" ;
VAL_ 1056 AwdMde_D_RqBrk 7 "Faulty" 6 "NotUsed2" 5 "NoRequest" 4 "Neutral" 3 "FourByFourLow" 2 "FourByFourHigh" 1 "FourByFourAuto" 0 "FourByTwo" ;
VAL_ 1056 SelDrvMdeHmi03_D_Rq 31 "Faulty" 30 "SelDrvMde31" 29 "SelDrvMde30" 28 "SelDrvMde29" 27 "SelDrvMde28" 26 "SelDrvMde27" 25 "SelDrvMde26" 24 "SelDrvMde25" 23 "SelDrvMde24" 22 "SelDrvMde23" 21 "SelDrvMde22" 20 "SelDrvMde21" 19 "SelDrvMde20" 18 "SelDrvMde19" 17 "SelDrvMde18" 16 "SelDrvMde17" 15 "SelDrvMde16" 14 "SelDrvMde15" 13 "SelDrvMde14" 12 "SelDrvMde13" 11 "SelDrvMde12" 10 "SelDrvMde11" 9 "SelDrvMde10" 8 "SelDrvMde09" 7 "SelDrvMde08" 6 "SelDrvMde07" 5 "SelDrvMde06" 4 "SelDrvMde05" 3 "SelDrvMde04" 2 "SelDrvMde03" 1 "SelDrvMde02" 0 "SelDrvMde01" ;
VAL_ 1056 SelDrvMdeMsgTxt2_D_Rq 15 "Message15" 14 "Message14" 13 "Message13" 12 "Message12" 11 "Message11" 10 "Message10" 9 "Message9" 8 "Message8" 7 "Message7" 6 "Message6" 5 "Message5" 4 "Message4" 3 "Message3" 2 "Message2" 1 "Message1" 0 "NoMessage" ;
VAL_ 1056 SelDrvMdePt_D_Rq 31 "Faulty" 30 "NotUsed15" 29 "NotUsed14" 28 "NotUsed13" 27 "NotUsed12" 26 "NotUsed11" 25 "NotUsed10" 24 "NotUsed9" 23 "NotUsed8" 22 "NotUsed7" 21 "NotUsed6" 20 "TrackMode" 19 "OnePedalDrive" 18 "EvLaterChargerMode" 17 "EvNowMode" 16 "DragMode" 15 "HighSpeedDesertMode_Baja" 14 "SportAdaptiveMode" 13 "NotAvailable_13" 12 "NotAvailable_12" 11 "NotAvailable_11" 10 "NotAvailable_10" 9 "RockCrawlMode" 8 "MudRutsMode" 7 "SandMode" 6 "EconomyMode" 5 "GrassGravelSnow" 4 "NotAvailable_04" 3 "TowHaulMode" 2 "NotAvailable_02" 1 "SportMode" 0 "NormalMode" ;
VAL_ 1056 SelDrvMdeMsgTxt_D_Rq 15 "Message15" 14 "Message14" 13 "Message13" 12 "Message12" 11 "Message11" 10 "Message10" 9 "Message9" 8 "Message8" 7 "Message7" 6 "Message6" 5 "Message5" 4 "Message4" 3 "Message3" 2 "Message2" 1 "Message1" 0 "NoMessage" ;
VAL_ 1056 SelDrvMde_D_Stat 3 "NotUsed" 2 "DriveModeChangeRequest" 1 "DriveModeChangeSelection" 0 "NoDriveModeChangeRequest" ;
VAL_ 1060 FuelLvlWarn_D_ActlEng 7 "DteLevel5Lowest" 6 "DteLevel4" 5 "DteLevel3" 4 "DteLevel2NonMyKey" 3 "DteLevel1MyKey" 2 "VeryLow" 1 "Low" 0 "OK" ;
VAL_ 1060 RearDiffOilTeWarn_B_Rq 1 "On" 0 "Off" ;
VAL_ 1060 EngExhMdeQuiet_D_Stat 3 "Faulty" 2 "QuietExhaust" 1 "LoudExhaust" 0 "Null" ;
VAL_ 1060 RearDiffOil_Te_Actl 511 "Faulty" ;
VAL_ 1060 BpedDrvMsgTxt_B_Dsply 1 "On" 0 "Off" ;
VAL_ 1060 SelDrvMdePt_D_Stat 0 "NotAvailable" 1 "Available" 2 "TemporarilyNotAvailable" 3 "Faulty" ;
VAL_ 118 StePinCompAnEst_D_Qf 3 "OK" 2 "Degraded" 1 "No_Data_Exists" 0 "Faulty" ;
VAL_ 118 StePinComp_An_Est_UB 1 "Fresh_data" 0 "Unchanged_data" ;
VAL_ 118 SteWhlComp_An_Est_UB 1 "Fresh_data" 0 "Unchanged_data" ;
VAL_ 118 SteWhlCompAnEst_D_Qf 3 "OK" 2 "Not_Within_Specifications" 1 "No_Data_Exists" 0 "Faulty" ;
VAL_ 118 WiprFront_D_Stat_UB 1 "Fresh_data" 0 "Unchanged_data" ;
VAL_ 118 WiprFront_D_Stat 15 "NO_DATA_EXISTS" 14 "STALLED" 13 "RESERVED" 12 "AUTO_ADJUST" 11 "COURTESYWIPE" 10 "AUTO_HIGH" 9 "AUTO_LOW" 8 "WASH" 7 "MIST_FLICK" 6 "MAN_HIGH" 5 "MAN_LOW" 4 "MAN_INT_ON" 3 "MAN_INT_OFF" 2 "OFF_MOVING" 1 "AUTO_OFF" 0 "OFF" ;
VAL_ 135 McGlblClkAdj_B_Rq 1 "Request" 0 "NoRequest" ;
VAL_ 134 DispGlblClkAdj_B_Rq 1 "Request" 0 "NoRequest" ;
VAL_ 766 McCntrStckNotfn_B_Stat 1 "On" 0 "Off" ;
VAL_ 766 McSelMsgId_B_Stat 1 "Valid" 0 "Invalid" ;
VAL_ 766 McSelChoice_D_Stat 7 "Choice7" 6 "Choice6" 5 "Choice5" 4 "Choice4" 3 "Choice3" 2 "Choice2" 1 "Choice1" 0 "Ok" ;
VAL_ 766 McPrsntMsgId_B_Stat 1 "Valid" 0 "Invalid" ;
VAL_ 766 McPrsntActv_D_Stat 7 "NotUsed_4" 6 "NotUsed_3" 5 "NotUsed_2" 4 "NotUsed_1" 3 "Deactivated" 2 "UpdateGranted" 1 "ActiveGranted" 0 "Inactive" ;
VAL_ 838 FohStrtDay_T_Rq 7 "Sunday" 6 "Saturday" 5 "Friday" 4 "Thursday" 3 "Wednesday" 2 "Tuesday" 1 "Monday" 0 "NotUsed" ;
VAL_ 838 FohStop_B_Rq 3 "Unknown" 2 "NotUsed" 1 "Enable" 0 "Disable" ;
VAL_ 838 FohTAllEnable_B_Rq 3 "Unknown" 2 "NotUsed" 1 "Enable" 0 "Disable" ;
VAL_ 838 FohT2Enable_B_Rq 1 "Enable" 0 "Disable" ;
VAL_ 838 FohT1Enable_B_Rq 1 "Enable" 0 "Disable" ;
VAL_ 838 FohStrtEnable_B_Rq 1 "Enable" 0 "Disable" ;
VAL_ 838 FohContOn_B_Rq 3 "Unknown" 2 "NotUsed" 1 "Enable" 0 "Disable" ;
VAL_ 939 PrkAidSnsRlSide_D_Stat 15 "Zone_15" 14 "Zone_14" 13 "Zone_13" 12 "Zone_12" 11 "Zone_11" 10 "Zone_10" 9 "Zone_9" 8 "Zone_8" 7 "Zone_7" 6 "Zone_6" 5 "Zone_5" 4 "Zone_4" 3 "Zone_3" 2 "Zone_2" 1 "Zone_1" 0 "Off" ;
VAL_ 939 SidePrkSnsR4_D_Stat 15 "NotUsed" 14 "NotFullyScannedYet" 13 "NoObjectInSector" 12 "Zone12" 11 "Zone11" 10 "Zone10" 9 "Zone9" 8 "Zone8" 7 "Zone7" 6 "Zone6" 5 "Zone5" 4 "Zone4" 3 "Zone3" 2 "Zone2" 1 "Zone1" 0 "Off" ;
VAL_ 939 SidePrkSnsR3_D_Stat 15 "NotUsed" 14 "NotFullyScannedYet" 13 "NoObjectInSector" 12 "Zone12" 11 "Zone11" 10 "Zone10" 9 "Zone9" 8 "Zone8" 7 "Zone7" 6 "Zone6" 5 "Zone5" 4 "Zone4" 3 "Zone3" 2 "Zone2" 1 "Zone1" 0 "Off" ;
VAL_ 939 SidePrkSnsL4_D_Stat 15 "NotUsed" 14 "NotFullyScannedYet" 13 "NoObjectInSector" 12 "Zone12" 11 "Zone11" 10 "Zone10" 9 "Zone9" 8 "Zone8" 7 "Zone7" 6 "Zone6" 5 "Zone5" 4 "Zone4" 3 "Zone3" 2 "Zone2" 1 "Zone1" 0 "Off" ;
VAL_ 939 SidePrkSnsL3_D_Stat 15 "NotUsed" 14 "NotFullyScannedYet" 13 "NoObjectInSector" 12 "Zone12" 11 "Zone11" 10 "Zone10" 9 "Zone9" 8 "Zone8" 7 "Zone7" 6 "Zone6" 5 "Zone5" 4 "Zone4" 3 "Zone3" 2 "Zone2" 1 "Zone1" 0 "Off" ;
VAL_ 939 PrkAidChime_D_Stat 3 "Fault" 2 "No_Data_Exists" 1 "On" 0 "Off" ;
VAL_ 939 PrkAidSnsRlCntr_D_Stat 15 "Zone_15" 14 "Zone_14" 13 "Zone_13" 12 "Zone_12" 11 "Zone_11" 10 "Zone_10" 9 "Zone_9" 8 "Zone_8" 7 "Zone_7" 6 "Zone_6" 5 "Zone_5" 4 "Zone_4" 3 "Zone_3" 2 "Zone_2" 1 "Zone_1" 0 "Off" ;
VAL_ 939 PrkAidSnsRrCrnr_D_Stat 15 "Zone_15" 14 "Zone_14" 13 "Zone_13" 12 "Zone_12" 11 "Zone_11" 10 "Zone_10" 9 "Zone_9" 8 "Zone_8" 7 "Zone_7" 6 "Zone_6" 5 "Zone_5" 4 "Zone_4" 3 "Zone_3" 2 "Zone_2" 1 "Zone_1" 0 "Off" ;
VAL_ 939 PrkAidSnsRrCntr_D_Stat 15 "Zone_15" 14 "Zone_14" 13 "Zone_13" 12 "Zone_12" 11 "Zone_11" 10 "Zone_10" 9 "Zone_9" 8 "Zone_8" 7 "Zone_7" 6 "Zone_6" 5 "Zone_5" 4 "Zone_4" 3 "Zone_3" 2 "Zone_2" 1 "Zone_1" 0 "Off" ;
VAL_ 939 PrkAidSnsRlCrnr_D_Stat 15 "Zone_15" 14 "Zone_14" 13 "Zone_13" 12 "Zone_12" 11 "Zone_11" 10 "Zone_10" 9 "Zone_9" 8 "Zone_8" 7 "Zone_7" 6 "Zone_6" 5 "Zone_5" 4 "Zone_4" 3 "Zone_3" 2 "Zone_2" 1 "Zone_1" 0 "Off" ;
VAL_ 939 PrkAidRear_D_Stat 3 "Faulted" 2 "Unused" 1 "Enabled" 0 "Disabled" ;
VAL_ 939 PrkAidFront_D_Stat 3 "Faulted" 2 "Unused" 1 "Enabled" 0 "Disabled" ;
VAL_ 939 PrkAid_D_Falt 7 "NotUsed2" 6 "NotUsed1" 5 "Failure_Front_PSM_Sensors" 4 "No_Data_Exists" 3 "Failure_Rear_Sensors" 2 "Speaker_Fault" 1 "ECU_Fault" 0 "No_Fault" ;
VAL_ 939 PrkAidSnsRrSide_D_Stat 15 "Zone_15" 14 "Zone_14" 13 "Zone_13" 12 "Zone_12" 11 "Zone_11" 10 "Zone_10" 9 "Zone_9" 8 "Zone_8" 7 "Zone_7" 6 "Zone_6" 5 "Zone_5" 4 "Zone_4" 3 "Zone_3" 2 "Zone_2" 1 "Zone_1" 0 "Off" ;
VAL_ 939 PrkAidLamp_D_Rq 3 "Not_Used" 2 "Flash" 1 "On" 0 "Off" ;
VAL_ 939 ApaLongCtrlEnbl_D_Rq 1 "Enable" 0 "Disable" ;
VAL_ 939 ApaBrk_D_Rq 3 "NotUsed" 2 "LowDecel" 1 "HighDecel" 0 "NoRequest" ;
VAL_ 938 SidePrkSnsR2_D_Stat 15 "NotUsed" 14 "NotFullyScannedYet" 13 "NoObjectInSector" 12 "Zone12" 11 "Zone11" 10 "Zone10" 9 "Zone9" 8 "Zone8" 7 "Zone7" 6 "Zone6" 5 "Zone5" 4 "Zone4" 3 "Zone3" 2 "Zone2" 1 "Zone1" 0 "Off" ;
VAL_ 938 SidePrkSnsR1_D_Stat 15 "NotUsed" 14 "NotFullyScannedYet" 13 "NoObjectInSector" 12 "Zone12" 11 "Zone11" 10 "Zone10" 9 "Zone9" 8 "Zone8" 7 "Zone7" 6 "Zone6" 5 "Zone5" 4 "Zone4" 3 "Zone3" 2 "Zone2" 1 "Zone1" 0 "Off" ;
VAL_ 938 SidePrkSnsL2_D_Stat 15 "NotUsed" 14 "NotFullyScannedYet" 13 "NoObjectInSector" 12 "Zone12" 11 "Zone11" 10 "Zone10" 9 "Zone9" 8 "Zone8" 7 "Zone7" 6 "Zone6" 5 "Zone5" 4 "Zone4" 3 "Zone3" 2 "Zone2" 1 "Zone1" 0 "Off" ;
VAL_ 938 SidePrkSnsL1_D_Stat 15 "NotUsed" 14 "NotFullyScannedYet" 13 "NoObjectInSector" 12 "Zone12" 11 "Zone11" 10 "Zone10" 9 "Zone9" 8 "Zone8" 7 "Zone7" 6 "Zone6" 5 "Zone5" 4 "Zone4" 3 "Zone3" 2 "Zone2" 1 "Zone1" 0 "Off" ;
VAL_ 938 ApaMde_D_Stat 7 "NotUsed3" 6 "NotUsed2" 5 "NotUsed1" 4 "POA" 3 "PPA" 2 "SAPP" 1 "Off" 0 "Null" ;
VAL_ 938 ApaActvSd_D_Actl 3 "Dirver_Side" 2 "Passenger_Side" 1 "No_Side" 0 "Null" ;
VAL_ 938 PrkAidSwtch_B_Stat 1 "Pressed" 0 "Not_Pressed" ;
VAL_ 938 PrkAidMsgTxt_D_Rq 15 "All_Sns_Blk" 14 "R_Sns_ON_F_Sns_Blk" 13 "R_Sns_Blk_F_Sns_ON" 12 "R_Sns_Inactive_Trlr_atch" 11 "Not_Avail_Trlr_attchd" 10 "Fail_Mode_no_Chime" 9 "Fail_Mode_with_Chime" 8 "R_Sns_Trlr_F_Sns_Blk" 7 "NotUsed3" 6 "Park_Sys_Alternate_Mode" 5 "R_Snsrs_On_F_Snsrs_On" 4 "NotUsed2" 3 "Reset_Message_Warn" 2 "R_Snsrs_Off_F_Snsrs_On" 1 "R_Snsrs_On_F_Snsrs_Off" 0 "All_Park_Sensors_Off" ;
VAL_ 938 ApaMde_D_Avail 15 "NotUsed7" 14 "NotUsed6" 13 "NotUsed5" 12 "NotUsed4" 11 "NotUsed3" 10 "NotUsed2" 9 "NotUsed1" 8 "PPA_POA" 7 "SAPP_POA" 6 "POA" 5 "PPA" 4 "SAPP" 3 "SAPP_PPA_POA" 2 "SAPP_PPA" 1 "None" 0 "Null" ;
VAL_ 938 PrkAidSnsFrSide_D_Stat 15 "Zone_15" 14 "Zone_14" 13 "Zone_13" 12 "Zone_12" 11 "Zone_11" 10 "Zone_10" 9 "Zone_9" 8 "Zone_8" 7 "Zone_7" 6 "Zone_6" 5 "Zone_5" 4 "Zone_4" 3 "Zone_3" 2 "Zone_2" 1 "Zone_1" 0 "Off" ;
VAL_ 938 PrkAidSnsFrCrnr_D_Stat 15 "Zone_15" 14 "Zone_14" 13 "Zone_13" 12 "Zone_12" 11 "Zone_11" 10 "Zone_10" 9 "Zone_9" 8 "Zone_8" 7 "Zone_7" 6 "Zone_6" 5 "Zone_5" 4 "Zone_4" 3 "Zone_3" 2 "Zone_2" 1 "Zone_1" 0 "Off" ;
VAL_ 938 PrkAidSnsFrCntr_D_Stat 15 "Zone_15" 14 "Zone_14" 13 "Zone_13" 12 "Zone_12" 11 "Zone_11" 10 "Zone_10" 9 "Zone_9" 8 "Zone_8" 7 "Zone_7" 6 "Zone_6" 5 "Zone_5" 4 "Zone_4" 3 "Zone_3" 2 "Zone_2" 1 "Zone_1" 0 "Off" ;
VAL_ 938 PrkAidSnsFlSide_D_Stat 15 "Zone_15" 14 "Zone_14" 13 "Zone_13" 12 "Zone_12" 11 "Zone_11" 10 "Zone_10" 9 "Zone_9" 8 "Zone_8" 7 "Zone_7" 6 "Zone_6" 5 "Zone_5" 4 "Zone_4" 3 "Zone_3" 2 "Zone_2" 1 "Zone_1" 0 "Off" ;
VAL_ 938 PrkAidSnsFlCrnr_D_Stat 15 "Zone_15" 14 "Zone_14" 13 "Zone_13" 12 "Zone_12" 11 "Zone_11" 10 "Zone_10" 9 "Zone_9" 8 "Zone_8" 7 "Zone_7" 6 "Zone_6" 5 "Zone_5" 4 "Zone_4" 3 "Zone_3" 2 "Zone_2" 1 "Zone_1" 0 "Off" ;
VAL_ 938 PrkAidSnsFlCntr_D_Stat 15 "Zone_15" 14 "Zone_14" 13 "Zone_13" 12 "Zone_12" 11 "Zone_11" 10 "Zone_10" 9 "Zone_9" 8 "Zone_8" 7 "Zone_7" 6 "Zone_6" 5 "Zone_5" 4 "Zone_4" 3 "Zone_3" 2 "Zone_2" 1 "Zone_1" 0 "Off" ;
VAL_ 938 RpaChime_D_Rq 15 "Zone15_Chime" 14 "Zone14_Chime" 13 "Zone13_Chime" 12 "Zone12_Chime" 11 "Zone11_Chime" 10 "Zone10_Chime" 9 "Zone9_Chime" 8 "Zone8_Chime" 7 "Zone7_Chime" 6 "Zone6_Chime" 5 "Zone5_Chime" 4 "Zone4_Chime" 3 "Zone3_Chime" 2 "Zone2_Chime" 1 "Zone1_Chime" 0 "No_Chime" ;
VAL_ 938 FpaChime_D_Rq 15 "Zone15_Chime" 14 "Zone14_Chime" 13 "Zone13_Chime" 12 "Zone12_Chime" 11 "Zone11_Chime" 10 "Zone10_Chime" 9 "Zone9_Chime" 8 "Zone8_Chime" 7 "Zone7_Chime" 6 "Zone6_Chime" 5 "Zone5_Chime" 4 "Zone4_Chime" 3 "Zone3_Chime" 2 "Zone2_Chime" 1 "Zone1_Chime" 0 "No_Chime" ;
VAL_ 938 PrkAidAudioMute_B_Rq 1 "Enable" 0 "Disable" ;
VAL_ 938 PrkBrkEl_B_RqFap 1 "Yes" 0 "No" ;
VAL_ 952 Tire_Press_IRR_Data 65535 "Not_Supported" 65534 "Invalid" 65533 "Unknown" ;
VAL_ 952 Tire_Press_ILR_Data 65535 "Not_Supported" 65534 "Invalid" 65533 "Unknown" ;
VAL_ 845 SeatMasgPsngr_D_Stat 15 "NotUsed_10" 14 "NotUsed_9" 13 "NotUsed_8" 12 "NotUsed_7" 11 "NotUsed_6" 10 "NotUsed_5" 9 "NotUsed_4" 8 "NotUsed_3" 7 "NotUsed_2" 6 "NotUsed_1" 5 "Pattern5" 4 "Pattern4" 3 "Pattern3" 2 "Pattern2" 1 "Pattern1" 0 "Null" ;
VAL_ 845 SeatIntnsPsngr_D_Stat 7 "NotUsed_3" 6 "NotUsed_2" 5 "NotUsed_1" 4 "High" 3 "Medium" 2 "Low" 1 "Off" 0 "Null" ;
VAL_ 845 StmsLmbrPsgr_D_Stat 3 "High" 2 "Low" 1 "Off" 0 "Null" ;
VAL_ 845 StmsCshnPsgr_D_Stat 3 "High" 2 "Low" 1 "Off" 0 "Null" ;
VAL_ 845 SeatSwtchPsgr_B_Stat 1 "On" 0 "Off" ;
VAL_ 845 SeatPPsgr_B_Stat 1 "Updating" 0 "NotUpdating" ;
VAL_ 845 SeatFnPsgr_D_Stat 7 "CushionMassage" 6 "LumbarMassage" 5 "UpperBolster" 4 "LowerBolster" 3 "UpperLumbar" 2 "MiddleLumbar" 1 "LowerLumbar" 0 "Null" ;
VAL_ 845 PsgrMemFeedback_Rsp 8 "Recall_4" 7 "Recall_3" 6 "Recall_2" 5 "Recall_1" 4 "Store_4" 3 "Store_3" 2 "Store_2" 1 "Store_1" 0 "Inactive" ;
VAL_ 1137 RngPerChrgLbl_L_Dsply 4095 "Faulty" 4094 "NoDataExists" ;
VAL_ 1137 RngPerChrgAvg_L_Dsply 4095 "Faulty" 4094 "NoDataExists" ;
VAL_ 1137 RngImpctTot_Pc_Dsply 1023 "Faulty" ;
VAL_ 1137 RngImpctExt_Pc_Dsply 1023 "Faulty" ;
VAL_ 1137 RngImpctDrv_Pc_Dsply 1023 "Faulty" ;
VAL_ 1137 RngImpctClim_Pc_Dsply 1023 "Faulty" ;
VAL_ 1073 AutoHoldMsgTxt_D_Rq 15 "Message15" 14 "Message14" 13 "Message13" 12 "Message12" 11 "Message11" 10 "Message10" 9 "Message9" 8 "Message8" 7 "Message7" 6 "Message6" 5 "Message5" 4 "Message4" 3 "Message3" 2 "Message2" 1 "Message1" 0 "NoMessage" ;
VAL_ 1073 AutoHoldMde_D_Ind 3 "Indication_3" 2 "Indication_2" 1 "Indication_1" 0 "Off" ;
VAL_ 1073 SteEffort_D_Stat 7 "NotUsed_3" 6 "NotUsed_2" 5 "NotUsed_1" 4 "SpecialMode_2" 3 "SpecialMode_1" 2 "Comfort" 1 "Sport" 0 "Normal" ;
VAL_ 1073 TbsLamp_D_RqDsply 3 "Not_Used" 2 "Flash" 1 "On" 0 "Off" ;
VAL_ 1073 TrnMsgTxt_D_Rq 15 "Message_15" 14 "Message_14" 13 "Message_13" 12 "Message_12" 11 "Message_11" 10 "Message_10" 9 "Message_9" 8 "Message_8" 7 "Message_7" 6 "Message_6" 5 "Message_5" 4 "Message_4" 3 "Message_3" 2 "Message_2" 1 "Message_1" 0 "NoMessage" ;
VAL_ 1073 TrnGearNtmAllow_B_Stat 1 "Yes" 0 "No" ;
VAL_ 1073 TrnGearMsgTxt_D_Rq 15 "Message_15" 14 "Message_14" 13 "Message_13" 12 "Message_12" 11 "Message_11" 10 "Message_10" 9 "Message_9" 8 "Message_8" 7 "Message_7" 6 "Message_6" 5 "Message_5" 4 "Message_4" 3 "Message_3" 2 "Message_2" 1 "Message_1" 0 "NoMessage" ;
VAL_ 1073 PdstrnAlrt_B_Falt_UB 1 "Fresh_data" 0 "Unchanged_data" ;
VAL_ 1073 PdstrnAlrt_B_Falt 1 "Yes" 0 "No" ;
VAL_ 1073 TrnMsgTxt_D_Rq_UB 1 "Fresh_data" 0 "Unchanged_data" ;
VAL_ 1073 TrnMsgTxt2_D_Rq_UB 1 "Fresh_data" 0 "Unchanged_data" ;
VAL_ 1073 TrnGearNtmAllow_B_Stat_UB 1 "Fresh_data" 0 "Unchanged_data" ;
VAL_ 1073 TrnGearMsgTxt_D_Rq_UB 1 "Fresh_data" 0 "Unchanged_data" ;
VAL_ 1073 TbsLamp_D_RqDsply_UB 1 "Fresh_data" 0 "Unchanged_data" ;
VAL_ 1073 SteEffort_D_Stat_UB 1 "Fresh_data" 0 "Unchanged_data" ;
VAL_ 1073 RvrseMirrorChime_B_Rq_UB 1 "Fresh_data" 0 "Unchanged_data" ;
VAL_ 1073 FuelFlw_Vl_ActlFoh_UB 1 "Fresh_data" 0 "Unchanged_data" ;
VAL_ 1073 AutoHoldMsgTxt_D_Rq_UB 1 "Fresh_data" 0 "Unchanged_data" ;
VAL_ 1073 AutoHoldMde_D_Ind_UB 1 "Fresh_data" 0 "Unchanged_data" ;
VAL_ 1073 RvrseMirrorChime_B_Rq 1 "Yes" 0 "No" ;
VAL_ 1073 TrnMsgTxt2_D_Rq 7 "NotUsed3" 6 "NotUsed2" 5 "NotUsed1" 4 "TransTooHot_LoudChime" 3 "PressBrake_LoudChime" 2 "PressBrake_SoftChime" 1 "PressBrake_NoChime" 0 "NoText_NoChime" ;
VAL_ 844 SeatMasgDrv_D_Stat 15 "NotUsed_10" 14 "NotUsed_9" 13 "NotUsed_8" 12 "NotUsed_7" 11 "NotUsed_6" 10 "NotUsed_5" 9 "NotUsed_4" 8 "NotUsed_3" 7 "NotUsed_2" 6 "NotUsed_1" 5 "Pattern5" 4 "Pattern4" 3 "Pattern3" 2 "Pattern2" 1 "Pattern1" 0 "Null" ;
VAL_ 844 SeatIntnsDrv_D_Stat 7 "NotUsed_3" 6 "NotUsed_2" 5 "NotUsed_1" 4 "High" 3 "Medium" 2 "Low" 1 "Off" 0 "Null" ;
VAL_ 844 StmsLmbrDrv_D_Stat 3 "High" 2 "Low" 1 "Off" 0 "Null" ;
VAL_ 844 StmsCshnDrv_D_Stat 3 "High" 2 "Low" 1 "Off" 0 "Null" ;
VAL_ 844 SeatSwtchDrv_B_Stat 1 "On" 0 "Off" ;
VAL_ 844 SeatFnDrv_D_Stat 7 "CushionMassage" 6 "LumbarMassage" 5 "UpperBolster" 4 "LowerBolster" 3 "UpperLumbar" 2 "MiddleLumbar" 1 "LowerLumbar" 0 "Null" ;
VAL_ 844 SeatPDrv_B_Stat 1 "Updating" 0 "NotUpdating" ;
VAL_ 843 SeatBlUpPsgr_Pc_Actl 127 "Null" ;
VAL_ 843 SeatBlLoPsgr_Pc_Actl 127 "Null" ;
VAL_ 842 SeatBlUpDrv_Pc_Actl 127 "Null" ;
VAL_ 842 SeatBlLoDrv_Pc_Actl 127 "Null" ;
VAL_ 846 SeatMasgDrv_D_Rq 15 "NotUsed_10" 14 "NotUsed_9" 13 "NotUsed_8" 12 "NotUsed_7" 11 "NotUsed_6" 10 "NotUsed_5" 9 "NotUsed_4" 8 "NotUsed_3" 7 "NotUsed_2" 6 "NotUsed_1" 5 "Pattern5" 4 "Pattern4" 3 "Pattern3" 2 "Pattern2" 1 "Pattern1" 0 "Null" ;
VAL_ 846 SeatMasgPsngr_D_Rq 15 "NotUsed_10" 14 "NotUsed_9" 13 "NotUsed_8" 12 "NotUsed_7" 11 "NotUsed_6" 10 "NotUsed_5" 9 "NotUsed_4" 8 "NotUsed_3" 7 "NotUsed_2" 6 "NotUsed_1" 5 "Pattern5" 4 "Pattern4" 3 "Pattern3" 2 "Pattern2" 1 "Pattern1" 0 "Null" ;
VAL_ 846 SeatLmbr_D_Rq 15 "NotUsed_7" 14 "NotUsed_6" 13 "NotUsed_5" 12 "NotUsed_4" 11 "NotUsed_3" 10 "NotUsed_2" 9 "NotUsed_1" 8 "PassengerDown" 7 "PassengerUp" 6 "PassengerAft" 5 "PassengerFore" 4 "DriverDown" 3 "DriverUp" 2 "DriverAft" 1 "DriverFore" 0 "Null" ;
VAL_ 846 SeatFnChngPsgr2_D_Rq 15 "Faulty" 14 "NotUsed9" 13 "NotUsed8" 12 "NotUsed7" 11 "NotUsed6" 10 "High_2" 9 "Med_2" 8 "Low_2" 7 "Off_2" 6 "High" 5 "Low" 4 "Off" 3 "Decrease" 2 "Increase" 1 "NotUsed1" 0 "Inactive" ;
VAL_ 846 SeatFnChngDrv2_D_Rq 15 "Faulty" 14 "NotUsed9" 13 "NotUsed8" 12 "NotUsed7" 11 "NotUsed6" 10 "High_2" 9 "Med_2" 8 "Low_2" 7 "Off_2" 6 "High" 5 "Low" 4 "Off" 3 "Decrease" 2 "Increase" 1 "NotUsed1" 0 "Inactive" ;
VAL_ 846 SeatFnPsgr_D_Rq 7 "CushionMassage" 6 "LumbarMassage" 5 "UpperBolster" 4 "LowerBolster" 3 "UpperLumbar" 2 "MiddleLumbar" 1 "LowerLumbar" 0 "Inactive" ;
VAL_ 846 SeatFnDrv_D_Rq 7 "CushionMassage" 6 "LumbarMassage" 5 "UpperBolster" 4 "LowerBolster" 3 "UpperLumbar" 2 "MiddleLumbar" 1 "LowerLumbar" 0 "Inactive" ;
VAL_ 846 SeatFnDfaltPsgr_B_Rq 1 "Active" 0 "Inactive" ;
VAL_ 846 SeatFnDfaltDrv_B_Rq 1 "Active" 0 "Inactive" ;
VAL_ 846 SeatFnChngPsgr_D_Rq 2 "Decrease" 1 "Increase" 0 "Inactive" ;
VAL_ 846 SeatFnChngDrv_D_Rq 2 "Decrease" 1 "Increase" 0 "Inactive" ;
VAL_ 846 PsgrMemory_Rq 8 "Recall_4" 7 "Recall_3" 6 "Recall_2" 5 "Recall_1" 4 "Store_4" 3 "Store_3" 2 "Store_2" 1 "Store_1" 0 "Inactive" ;
VAL_ 935 SodInnrRight_D_Stat 3 "Reporting" 2 "Not_Reporting" 1 "System_Standby" 0 "Initialization" ;
VAL_ 935 RbaCtaRight_D_Stat 7 "Faulty" 6 "NotUsed_2" 5 "NotUsed_1" 4 "Invalid" 3 "Disabled" 2 "On" 1 "Trailer_Tow_Off" 0 "Off" ;
VAL_ 935 LcwaRight_D_Stat 7 "Faulty" 6 "NotUsed_3" 5 "NotUsed_2" 4 "NotUsed_1" 3 "Disabled" 2 "TemporaryUnavailable" 1 "SensorBlocked" 0 "Available" ;
VAL_ 935 LcwaDetctRight2_B_Stat 1 "Yes" 0 "No" ;
VAL_ 935 LcwaDetctRight1_B_Stat 1 "Yes" 0 "No" ;
VAL_ 935 CtaInnrRight_D_Stat 3 "Reporting" 2 "Not_Reporting" 1 "System_Standby" 0 "Initialization" ;
VAL_ 935 CtaAlrtRight2_D_Stat 7 "NotUsed3" 6 "NotUsed2" 5 "NotUsed1" 4 "AlertZone4" 3 "AlertZone3" 2 "AlertZone2" 1 "AlertZone1" 0 "Off" ;
VAL_ 935 BttRight_D_Stat 7 "NotUsed" 6 "Disabled" 5 "Off" 4 "OffTemp" 3 "NotConnected" 2 "Pending" 1 "Connected" 0 "NotDetermined" ;
VAL_ 935 BttRight_D_RqDrv 3 "NotUsed" 2 "Request" 1 "NoRequest" 0 "Null" ;
VAL_ 935 CtaBrkRightMsgTxt_B_Rq 1 "Enable" 0 "Disable" ;
VAL_ 935 CtaRightBrkEnbl_B_Rq 1 "Enable" 0 "Disable" ;
VAL_ 935 CtaSnsRight_D_Stat 3 "Invalid" 2 "System_Failure" 1 "Blocked" 0 "Clear" ;
VAL_ 935 CtaAlrtRight_D_Stat 1 "On" 0 "Off" ;
VAL_ 935 CtaRight_D_Stat 7 "NotUsed_3" 6 "NotUsed_2" 5 "NotUsed_1" 4 "Invalid" 3 "Disabled" 2 "On" 1 "Trailer_Tow_Off" 0 "Off" ;
VAL_ 935 SodRight_D_Stat 7 "NotUsed_3" 6 "NotUsed_2" 5 "NotUsed_1" 4 "Invalid" 3 "Disabled" 2 "On" 1 "Trailer_Tow_Off" 0 "Off" ;
VAL_ 935 SodSnsRight_D_Stat 3 "Second_Warning_Audio" 2 "System_Failure" 1 "Blocked" 0 "Clear" ;
VAL_ 935 CtaRightBrkDecel_B_Rq 1 "Enable" 0 "Disable" ;
VAL_ 935 SodAlrtRight_D_Stat 3 "Bulb_Proveout" 2 "Flash" 1 "On" 0 "Off" ;
VAL_ 935 SodDetctRight_D_Stat 4 "Sensor_Blocked" 3 "Sensor_Fault" 2 "Flash_On" 1 "Alert_On" 0 "AlertOff_FlashOff_SensrClr" ;
VAL_ 934 SodInnrLeft_D_Stat 3 "Reporting" 2 "Not_Reporting" 1 "System_Standby" 0 "Initialization" ;
VAL_ 934 RbaCtaLeft_D_Stat 7 "Faulty" 6 "NotUsed_2" 5 "NotUsed_1" 4 "Invalid" 3 "Disabled" 2 "On" 1 "Trailer_Tow_Off" 0 "Off" ;
VAL_ 934 LcwaDetctLeft2_B_Stat 1 "Yes" 0 "No" ;
VAL_ 934 LcwaDetctLeft1_B_Stat 1 "Yes" 0 "No" ;
VAL_ 934 CtaInnrLeft_D_Stat 3 "Reporting" 2 "Not_Reporting" 1 "System_Standby" 0 "Initialization" ;
VAL_ 934 LcwaLeft_D_Stat 7 "Faulty" 6 "NotUsed_3" 5 "NotUsed_2" 4 "NotUsed_1" 3 "Disabled" 2 "TemporaryUnavailable" 1 "SensorBlocked" 0 "Available" ;
VAL_ 934 CtaAlrtLeft2_D_Stat 7 "NotUsed3" 6 "NotUsed2" 5 "NotUsed1" 4 "AlertZone4" 3 "AlertZone3" 2 "AlertZone2" 1 "AlertZone1" 0 "Off" ;
VAL_ 934 BttLeft_D_Stat 7 "NotUsed" 6 "Disabled" 5 "Off" 4 "OffTemp" 3 "NotConnected" 2 "Pending" 1 "Connected" 0 "NotDetermined" ;
VAL_ 934 BttLeft_D_RqDrv 3 "NotUsed" 2 "Request" 1 "NoRequest" 0 "Null" ;
VAL_ 934 CtaBrkLeftMsgTxt_B_Rq 1 "Enable" 0 "Disable" ;
VAL_ 934 CtaLeftBrkDecel_B_Rq 1 "Enable" 0 "Disable" ;
VAL_ 934 CtaLeftBrkEnbl_B_Rq 1 "Enable" 0 "Disable" ;
VAL_ 934 CtaSnsLeft_D_Stat 3 "Invalid" 2 "System_Failure" 1 "Blocked" 0 "Clear" ;
VAL_ 934 SodDetctLeft_D_Stat 4 "Sensor_Blocked" 3 "Sensor_Fault" 2 "Flash_On" 1 "Alert_On" 0 "AlertOff_FlashOff_SensrClr" ;
VAL_ 934 CtaLeft_D_Stat 7 "NotUsed_3" 6 "NotUsed_2" 5 "NotUsed_1" 4 "Invalid" 3 "Disabled" 2 "On" 1 "Trailer_Tow_Off" 0 "Off" ;
VAL_ 934 CtaAlrtLeft_D_Stat 1 "On" 0 "Off" ;
VAL_ 934 SodLeft_D_Stat 7 "NotUsed_3" 6 "NotUsed_2" 5 "NotUsed_1" 4 "Invalid" 3 "Disabled" 2 "On" 1 "Trailer_Tow_Off" 0 "Off" ;
VAL_ 934 SodSnsLeft_D_Stat 3 "Second_Warning_Audio" 2 "System_Failure" 1 "Blocked" 0 "Clear" ;
VAL_ 934 SodAlrtLeft_D_Stat 3 "Bulb_Proveout" 2 "Flash" 1 "On" 0 "Off" ;
VAL_ 486 ResponseCode_No_Res 3 "NotUsed" 2 "Accepted" 1 "NotAccepted" 0 "Null" ;
VAL_ 486 ACU_ARAudioSource_Rsp 15 "iPod" 14 "USB" 13 "BTAudio" 0 "AmfmRadio" 1 "FrontDisc" 2 "SDARS_DAB" 3 "InDashCdChanger" 4 "VoiceRecogniser" 5 "TelematicUnit" 6 "BluetoothPhone" 7 "RearDisc" 8 "APIM" 9 "FrontAuxInput" 10 "Navigation" 11 "RearAux" 12 "NotReq" ;
VAL_ 486 ACU_AROperationType_Rsp 0 "Inactive" 1 "Requestaudioresource" 2 "Releaseaudioresource" 3 "Releaseallaudioresouces" 4 "Getresourceupdate" 5 "Getallresourceupdates" ;
VAL_ 486 ACU_ARReqstrSystem_Rsp 0 "FrontRequester" 1 "RearRequester" ;
VAL_ 486 ACU_ARResponse_Rsp 0 "Inactive" 1 "RequestAccepted" 2 "RequestAcceptedWoCtrl" 3 "RequestDenied" 4 "RessourceUpdateStatus" ;
VAL_ 486 ACU_ARReqstrPriority_Rp 0 "EmergencyServ" 1 "TelService" 2 "AutoAnswer" 3 "Ta" 4 "PttMutevoice" 5 "NavUserVoiceCmd" 6 "NavSysVoiceCmd" 7 "Radio" 8 "Disc" 9 "Alarm" 10 "Ptynews" 11 "Aux_ExtSource" 12 "MobileNavAndTelMute" 13 "ManualAudioMute" 14 "NotReq" ;
VAL_ 486 ACU_RUAudioSource_St 15 "iPod" 14 "USB" 13 "BTAudio" 0 "AmfmRadio" 1 "FrontDisc" 2 "SDARS_DAB" 3 "InDashCdChanger" 4 "VoiceRecogniser" 5 "TelematicUnit" 6 "BluetoothPhone" 7 "RearDisc" 8 "APIM" 9 "FrontAuxInput" 10 "Navigation" 11 "RearAux" 12 "NotReq" ;
VAL_ 486 ACU_RUReqstrSystem_St 0 "FrontRequester" 1 "RearRequester" ;
VAL_ 486 ACU_RUResReqstStatus_St 0 "NoResourceupdate" 1 "Deallocated" 2 "Allocated" 3 "Stacked" 4 "Granted" 5 "GrantedNoControlOfAudioSrc" ;
VAL_ 486 ACU_RUReqstrPriority_St 0 "EmergencyServ" 1 "TelService" 2 "AutoAnswer" 3 "Ta" 4 "PttMutevoice" 5 "NavUserVoiceCmd" 6 "NavSysVoiceCmd" 7 "Radio" 8 "Disc" 9 "Alarm" 10 "Ptynews" 11 "Aux_ExtSource" 12 "MobileNavAndTelMute" 13 "ManualAudioMute" 14 "NotReq" ;
VAL_ 553 CCOI_PolicyClient_St 15 "NotUsed_4" 14 "NotUsed_3" 13 "NotUsed_2" 12 "NotUsed_1" 11 "DataStorageError" 10 "StateMachineInconsistent" 9 "UnrecoverableSyncError" 8 "On BoardSyncFailed" 7 "OnBoardImplemented" 6 "OnBoardSynchronized" 5 "OnBoardSynchronizing" 4 "OnBoardSyncNeeded" 3 "OffBoardUpdatePending" 2 "OnBoardUpdatePending" 1 "Waiting" 0 "Null" ;
VAL_ 553 DistToChrgrBynd_L_Actl 511 "Faulty" 510 "NoDataExists" ;
VAL_ 553 ResetAvgFe_B_Rq 1 "Reset" 0 "Null" ;
VAL_ 553 ResetTrip2_B_Rq 1 "Reset" 0 "Null" ;
VAL_ 553 SndImmrsnLvl_D_Rq 255 "NotUsed_127" 254 "NotUsed_126" 253 "NotUsed_125" 252 "NotUsed_124" 251 "NotUsed_123" 250 "NotUsed_122" 249 "NotUsed_121" 248 "NotUsed_120" 247 "NotUsed_119" 246 "NotUsed_118" 245 "NotUsed_117" 244 "NotUsed_116" 243 "NotUsed_115" 242 "NotUsed_114" 241 "NotUsed_113" 240 "NotUsed_112" 239 "NotUsed_111" 238 "NotUsed_110" 237 "NotUsed_109" 236 "NotUsed_108" 235 "NotUsed_107" 234 "NotUsed_106" 233 "NotUsed_105" 232 "NotUsed_104" 231 "NotUsed_103" 230 "NotUsed_102" 229 "NotUsed_101" 228 "NotUsed_100" 227 "NotUsed_99" 226 "NotUsed_98" 225 "NotUsed_97" 224 "NotUsed_96" 223 "NotUsed_95" 222 "NotUsed_94" 221 "NotUsed_93" 220 "NotUsed_92" 219 "NotUsed_91" 218 "NotUsed_90" 217 "NotUsed_89" 216 "NotUsed_88" 215 "NotUsed_87" 214 "NotUsed_86" 213 "NotUsed_85" 212 "NotUsed_84" 211 "NotUsed_83" 210 "NotUsed_82" 209 "NotUsed_81" 208 "NotUsed_80" 207 "NotUsed_79" 206 "NotUsed_78" 205 "NotUsed_77" 204 "NotUsed_76" 203 "NotUsed_75" 202 "NotUsed_74" 201 "NotUsed_73" 200 "NotUsed_72" 199 "NotUsed_71" 198 "NotUsed_70" 197 "NotUsed_69" 196 "NotUsed_68" 195 "NotUsed_67" 194 "NotUsed_66" 193 "NotUsed_65" 192 "NotUsed_64" 191 "NotUsed_63" 190 "NotUsed_62" 189 "NotUsed_61" 188 "NotUsed_60" 187 "NotUsed_59" 186 "NotUsed_58" 185 "NotUsed_57" 184 "NotUsed_56" 183 "NotUsed_55" 182 "NotUsed_54" 181 "NotUsed_53" 180 "NotUsed_52" 179 "NotUsed_51" 178 "NotUsed_50" 177 "NotUsed_49" 176 "NotUsed_48" 175 "NotUsed_47" 174 "NotUsed_46" 173 "NotUsed_45" 172 "NotUsed_44" 171 "NotUsed_43" 170 "NotUsed_42" 169 "NotUsed_41" 168 "NotUsed_40" 167 "NotUsed_39" 166 "NotUsed_38" 165 "NotUsed_37" 164 "NotUsed_36" 163 "NotUsed_35" 162 "NotUsed_34" 161 "NotUsed_33" 160 "NotUsed_32" 159 "NotUsed_31" 158 "NotUsed_30" 157 "NotUsed_29" 156 "NotUsed_28" 155 "NotUsed_27" 154 "NotUsed_26" 153 "NotUsed_25" 152 "NotUsed_24" 151 "NotUsed_23" 150 "NotUsed_22" 149 "NotUsed_21" 148 "NotUsed_20" 147 "NotUsed_19" 146 "NotUsed_18" 145 "NotUsed_17" 144 "NotUsed_16" 143 "NotUsed_15" 142 "NotUsed_14" 141 "NotUsed_13" 140 "NotUsed_12" 139 "NotUsed_11" 138 "NotUsed_10" 137 "NotUsed_9" 136 "NotUsed_8" 135 "NotUsed_7" 134 "NotUsed_6" 133 "NotUsed_5" 132 "NotUsed_4" 131 "NotUsed_3" 130 "NotUsed_2" 129 "NotUsed_1" 128 "Level127" 127 "Level126" 126 "Level125" 125 "Level124" 124 "Level123" 123 "Level122" 122 "Level121" 121 "Level120" 120 "Level119" 119 "Level118" 118 "Level117" 117 "Level116" 116 "Level115" 115 "Level114" 114 "Level113" 113 "Level112" 112 "Level111" 111 "Level110" 110 "Level109" 109 "Level108" 108 "Level107" 107 "Level106" 106 "Level105" 105 "Level104" 104 "Level103" 103 "Level102" 102 "Level101" 101 "Level100" 100 "Level99" 99 "Level98" 98 "Level97" 97 "Level96" 96 "Level95" 95 "Level94" 94 "Level93" 93 "Level92" 92 "Level91" 91 "Level90" 90 "Level89" 89 "Level88" 88 "Level87" 87 "Level86" 86 "Level85" 85 "Level84" 84 "Level83" 83 "Level82" 82 "Level81" 81 "Level80" 80 "Level79" 79 "Level78" 78 "Level77" 77 "Level76" 76 "Level75" 75 "Level74" 74 "Level73" 73 "Level72" 72 "Level71" 71 "Level70" 70 "Level69" 69 "Level68" 68 "Level67" 67 "Level66" 66 "Level65" 65 "Level64" 64 "Level63" 63 "Level62" 62 "Level61" 61 "Level60" 60 "Level59" 59 "Level58" 58 "Level57" 57 "Level56" 56 "Level55" 55 "Level54" 54 "Level53" 53 "Level52" 52 "Level51" 51 "Level50" 50 "Level49" 49 "Level48" 48 "Level47" 47 "Level46" 46 "Level45" 45 "Level44" 44 "Level43" 43 "Level42" 42 "Level41" 41 "Level40" 40 "Level39" 39 "Level38" 38 "Level37" 37 "Level36" 36 "Level35" 35 "Level34" 34 "Level33" 33 "Level32" 32 "Level31" 31 "Level30" 30 "Level29" 29 "Level28" 28 "Level27" 27 "Level26" 26 "Level25" 25 "Level24" 24 "Level23" 23 "Level22" 22 "Level21" 21 "Level20" 20 "Level19" 19 "Level18" 18 "Level17" 17 "Level16" 16 "Level15" 15 "Level14" 14 "Level13" 13 "Level12" 12 "Level11" 11 "Level10" 10 "Level9" 9 "Level8" 8 "Level7" 7 "Level6" 6 "Level5" 5 "Level4" 4 "Level3" 3 "Level2" 2 "Level1" 1 "Level0" 0 "Inactive" ;
VAL_ 553 InfoSysMasterPw_D_Stat 7 "NotUsed_6" 6 "NotUsed_5" 5 "NotUsed_4" 4 "NotUsed_3" 0 "Inactive" 1 "On" 2 "NotUsed_1" 3 "NotUsed_2" ;
VAL_ 553 ResetTrip1_B_Rq 1 "Reset" 0 "Null" ;
VAL_ 553 Disp_LangSel2_St 32 "Indian_English" 31 "Thai" 30 "Slovak" 29 "Arabic" 28 "Taiwanese" 27 "Mandarin_Chinese" 26 "Korean" 25 "AU_English" 24 "Japanese" 23 "Braz_Portuguese" 22 "EU_Portuguese" 21 "Finish" 20 "Norwegian" 19 "Danish" 18 "Swedish" 17 "Hungarian" 16 "Greek" 15 "Czech" 14 "Polish" 13 "Flemish" 12 "Dutch" 11 "Russian" 10 "Turkish" 9 "Mex_Spanish" 8 "EU_Spanish" 7 "Cana_French" 6 "EU_French" 5 "Italian" 4 "German" 3 "NA_English" 2 "UK_English" 1 "Unknown" 0 "Invalid" ;
VAL_ 553 Disp_LangSel_St 31 "Thai" 30 "Slovak" 29 "Arabic" 28 "Taiwanese" 27 "Mandarin_Chinese" 26 "Korean" 25 "AU_English" 24 "Japanese" 23 "Braz_Portuguese" 22 "EU_Portuguese" 21 "Finish" 20 "Norwegian" 19 "Danish" 18 "Swedish" 17 "Hungarian" 16 "Greek" 15 "Czech" 14 "Polish" 13 "Flemish" 12 "Dutch" 11 "Russian" 10 "Turkish" 9 "Mex_Spanish" 8 "EU_Spanish" 7 "Cana_French" 6 "EU_French" 5 "Italian" 4 "German" 3 "NA_English" 2 "UK_English" 1 "Unknown" 0 "Invalid" ;
VAL_ 553 Diagnostic_Operation_Rq 7 "SignalStrength" 6 "SDARSESNNumber" 5 "SpeakerWalkAround" 4 "CalibrationPartNumber" 15 "Reserved" 3 "HardwarePartNumber" 2 "SoftwarePartNumber" 1 "GetAllBackgroundDiagRq" 0 "Inactive" ;
VAL_ 553 Bezel_Diag_Module_Rq 15 "Reserved" 3 "EFP" 2 "DSP_AMP" 1 "AHU" 0 "Inactive" ;
VAL_ 553 Audio_Demo_CMND 2 "On" 1 "Off" 0 "Inactive" ;
VAL_ 553 Audio_Visualizer 2 "On" 1 "Off" 0 "Inactive" ;
VAL_ 553 Surround_Sound_Upmix 2 "Surround" 1 "Stereo" 0 "Inactive" ;
VAL_ 553 Bezel_Diag_State_Rq 1 "Active" 0 "Inactive" ;
VAL_ 553 SurndSndUpmix2_D_Rq 4 "Audience" 3 "On_Stage" 2 "Surround" 1 "Stereo" 0 "Inactive" ;
VAL_ 739 EngExhMdeHrStrt_D_Rq 31 "NotUsed_7" 30 "NotUsed_6" 29 "NotUsed_5" 28 "NotUsed_4" 27 "NotUsed_3" 26 "NotUsed_2" 25 "NotUsed_1" 24 "Hour23_11pm" 23 "Hour22_10pm" 22 "Hour21_9pm" 21 "Hour20_8pm" 20 "Hour19_7pm" 19 "Hour18_6pm" 18 "Hour17_5pm" 17 "Hour16_4pm" 16 "Hour15_3pm" 15 "Hour14_2pm" 14 "Hour13_1pm" 13 "Hour12_12pm" 12 "Hour11_11am" 11 "Hour10_10am" 10 "Hour9_9am" 9 "Hour8_8am" 8 "Hour7_7am" 7 "Hour6_6am" 6 "Hour5_5am" 5 "Hour4_4am" 4 "Hour3_3am" 3 "Hour2_2am" 2 "Hour1_1am" 1 "Hour0_12am" 0 "Null" ;
VAL_ 739 EngExhMdeHrEnd_D_Rq 31 "NotUsed_7" 30 "NotUsed_6" 29 "NotUsed_5" 28 "NotUsed_4" 27 "NotUsed_3" 26 "NotUsed_2" 25 "NotUsed_1" 24 "Hour23_11pm" 23 "Hour22_10pm" 22 "Hour21_9pm" 21 "Hour20_8pm" 20 "Hour19_7pm" 19 "Hour18_6pm" 18 "Hour17_5pm" 17 "Hour16_4pm" 16 "Hour15_3pm" 15 "Hour14_2pm" 14 "Hour13_1pm" 13 "Hour12_12pm" 12 "Hour11_11am" 11 "Hour10_10am" 10 "Hour9_9am" 9 "Hour8_8am" 8 "Hour7_7am" 7 "Hour6_6am" 6 "Hour5_5am" 5 "Hour4_4am" 4 "Hour3_3am" 3 "Hour2_2am" 2 "Hour1_1am" 1 "Hour0_12am" 0 "Null" ;
VAL_ 739 EngExhMdeHrEnbl_D_Rq 3 "NotConfigured" 2 "Enabled" 1 "Disabled" 0 "Null" ;
VAL_ 739 Partial_Amp_Shutdown 1 "Active" 0 "Inactive" ;
VAL_ 739 HMI_HMIMode_St 7 "NotUsed2" 6 "NotUsed1" 5 "Load_Shed_Active" 0 "Invalid" 1 "OffMode" 2 "On" 3 "Phone" 4 "Climate" ;
VAL_ 1009 ChrgCordUnlock_B_Rq 1 "Request" 0 "NoRequest" ;
VAL_ 1009 AutoHoldSwtch_D_Stat3 3 "Faulty" 2 "NotUsed" 1 "Pressed" 0 "Not_Pressed" ;
VAL_ 1009 TrlrTrgtAcquire_D_Rq 7 "NotUsed_2" 6 "NotUsed_1" 5 "ActivateRVCforTBA" 4 "CancelAcquisition" 3 "RetryAcquisition" 2 "AcquisitionSuccessful" 1 "StartAcquisition" 0 "Inactive" ;
VAL_ 1009 RearAudioCtlLck_D_Rq 2 "Unlock" 1 "Lock" 0 "Null" ;
VAL_ 1009 TrlrAidCancl_B_Rq 1 "Cancel" 0 "Null" ;
VAL_ 1009 CenterStackRing_D_Actl 3 "LimitedOn" 2 "On" 1 "Off" 0 "Null" ;
VAL_ 1009 ValetMode_D_Stat 3 "NotUsed" 2 "On" 1 "Off" 0 "Null" ;
VAL_ 1009 TrlrAidSetup_D_Stat 7 "Faulty" 6 "NotUsed_3" 5 "NotUsed_2" 4 "NotUsed_1" 3 "EnterParameters" 2 "EndSetup" 1 "BeginSetup" 0 "Null" ;
VAL_ 531 VehStop_D_Stat 3 "Faulty" 2 "NoDataExists" 1 "Yes" 0 "No" ;
VAL_ 531 TracCtlPtActv_B_Actl 1 "Active" 0 "Inactive" ;
VAL_ 531 PrkBrkYwLamp_D_Rq 3 "Fast_Flash" 2 "Slow_Flash" 1 "On" 0 "Off" ;
VAL_ 531 PrkBrkRedLamp_D_Rq 3 "Fast_Flash" 2 "Slow_Flash" 1 "On" 0 "Off" ;
VAL_ 531 PrkBrkMsgTxt_D_Rq 15 "Message15" 14 "Message14" 13 "Message13" 12 "Message12" 11 "Message11" 10 "Message10" 9 "Message9" 8 "Message8" 7 "Message7" 6 "Message6" 5 "Message5" 4 "Message4" 3 "Message3" 2 "Message2" 1 "Message1" 0 "No_Message" ;
VAL_ 531 PrkBrkStatus 7 "GeneralFault_MaintenceMode" 6 "ECD_by_Brake_ECU_Active" 5 "EPB_Limphome_Active" 4 "Rear_Caliper_Open" 3 "RWU_By_EPB_Active" 2 "Rear_Caliper_Transition" 1 "Rear_Caliper_Closed" 0 "Not_Supported" ;
VAL_ 531 LscmbbMntr_B_Err 1 "DisplayMessage" 0 "NoMessage" ;
VAL_ 531 LscmbbBrkDis_B_Actl 1 "Yes" 0 "No" ;
VAL_ 531 StabCtlBrkActv_B_Actl 1 "Yes" 0 "No" ;
VAL_ 531 CmbbBrkPrchg_B_Actl 1 "Yes" 0 "No" ;
VAL_ 531 CmbbBrkDecel_B_Actl 1 "Yes" 0 "No" ;
VAL_ 531 CmbbBaSensInc_B_Actl 1 "Yes" 0 "No" ;
VAL_ 531 AccBrkWarm_B_Actl 1 "Yes" 0 "No" ;
VAL_ 531 AccBrkTotTqMn_B_Actl 1 "Yes" 0 "No" ;
VAL_ 531 AccBrkPrchgActv_B_Actl 1 "Yes" 0 "No" ;
VAL_ 531 AccBrkDis_B_Actl 1 "Yes" 0 "No" ;
VAL_ 531 AccBrkDeny_B_Actl 1 "Yes" 0 "No" ;
VAL_ 531 AccBrkActv_B_Actl 1 "Yes" 0 "No" ;
VAL_ 531 PrplDrgCtlActv_B_Actl 1 "Active" 0 "Inactive" ;
VAL_ 531 AbsActv_B_Actl 1 "Yes" 0 "No" ;
VAL_ 531 CmbbBrkDis_B_Actl 1 "Yes" 0 "No" ;
VAL_ 531 CmbbDeny_B_ActlBrk 1 "Yes" 0 "No" ;
VAL_ 531 CcDis_B_Cmd 1 "Yes" 0 "No" ;
VAL_ 531 VehLongOvrGnd_A_Est 1023 "Fault" 1022 "Unknown" ;
VAL_ 531 AccStopActv_B_ActlBrk 1 "Yes" 0 "No" ;
VAL_ 531 AccDis_B_ActlEpb 1 "Yes" 0 "No" ;
VAL_ 531 LscmbbDeny_B_ActlBrk 1 "Yes" 0 "No" ;
VAL_ 531 LscmbbBrkDecel_B_Actl 1 "Yes" 0 "No" ;
VAL_ 531 LscmbbBaSensInc_B_Actl 1 "Yes" 0 "No" ;
VAL_ 531 LscmbBrkPrchg_B_Actl 1 "Active" 0 "Inactive" ;
VAL_ 531 VehicleStationary 1 "Yes" 0 "No" ;
VAL_ 549 WwaActv_B_Stat 1 "Active" 0 "Inactive" ;
VAL_ 549 StrtInGearOk_D_Stat 3 "NotUsed" 2 "Accepted" 1 "NotAccepted" 0 "Null" ;
VAL_ 549 IPC_MyKeyVolLimit_St 0 "Invalid" 1 "Off" 2 "On" ;
VAL_ 549 HudVertSzMnuOn_B_Rq 1 "On" 0 "Off" ;
VAL_ 549 HudVertMnuOn_B_Rq 1 "Yes" 0 "No" ;
VAL_ 549 HudRotatMnuOn_B_Rq 1 "Yes" 0 "No" ;
VAL_ 549 HudCntntMnuOn_B_Rq 1 "On" 0 "Off" ;
VAL_ 549 HudBrightMnuOn_B_Rq 1 "Yes" 0 "No" ;
VAL_ 549 HdcOn_B_Rq 1 "On" 0 "Off" ;
VAL_ 549 IPC_Attn_Info_Audio 7 "Unknown" 6 "Attenuation_6" 5 "Attenuation_5" 4 "Attenuation_4" 3 "Attenuation_3" 2 "Attenuation_2" 1 "Attenuation_1" 0 "No_Attenuation_of_Audio" ;
VAL_ 549 BeltminderAudioMute 2 "On" 1 "Off" 0 "Invalid" ;
VAL_ 549 Power_Up_Chime_Modules 1 "Active" 0 "Inactive" ;
VAL_ 549 Chime_Source 2 "Cluster" 1 "Infotainment_Sys" 0 "Invalid" ;
VAL_ 549 IPC_New_Attn_Event 1 "Active" 0 "Inactive" ;
VAL_ 549 MetricActv_B_Dsply 1 "Active" 0 "Inactive" ;
VAL_ 765 BalrSwtch_D_Stat 3 "NotUsed" 2 "Pressed" 1 "NotPressed" 0 "Null" ;
VAL_ 765 BalrMde_D_Rq 3 "High" 2 "Medium" 1 "Low" 0 "Null" ;
VAL_ 765 RstrnOnPsngr_D_RqMnu 15 "Faulty" 14 "NotUsed_11" 13 "NotUsed_10" 12 "ConfiguredOff" 11 "NotUsed_9" 10 "On" 9 "NotUsed_8" 8 "NotUsed_7" 7 "NotUsed_6" 6 "NotUsed_5" 5 "Off" 4 "NotUsed_4" 3 "NotUsed_3" 2 "NotUsed_2" 1 "NotUsed_1" 0 "NoAction" ;
VAL_ 765 WaitToStartLamp_D_Falt 3 "NotUsed" 2 "Wait_to_start_lamp_failed" 1 "Diagnosis_not_ready" 0 "Wait_to_start_lamp_OK" ;
VAL_ 765 EsaOn_B_Rq 1 "On" 0 "Off" ;
VAL_ 765 BttOn_B_Rq 1 "On" 0 "Off" ;
VAL_ 765 Btt_L_Actl 127 "Faulty" 126 "NoDataExists" ;
VAL_ 765 RearDiffLck_D_RqArb 3 "Faulty" 2 "NotUsed" 1 "On" 0 "Off" ;
VAL_ 765 AwdMde_D_RqArb 7 "Faulty" 6 "NotUsed2" 5 "NoRequest" 4 "Neutral" 3 "FourByFourLow" 2 "FourByFourHigh" 1 "FourByFourAuto" 0 "FourByTwo" ;
VAL_ 765 SelDrvMdeTxtReset_B_Rq 1 "Yes" 0 "No" ;
VAL_ 765 AutoTowAllw_D_RqMnu 3 "TowHaulCommandedOn" 2 "AutoTowHaulEnabled" 1 "AutoTowHaulDisabled" 0 "NoSelection" ;
VAL_ 765 DrvInputRequired_B_Rq 1 "Yes" 0 "No" ;
VAL_ 765 SelDrvMdeDsply_B_Avail 1 "Available" 0 "NotAvailable" ;
VAL_ 765 EngExhMdeQuiet_D_Rq 3 "Faulty" 2 "QuietExhaust" 1 "LoudExhaust" 0 "Null" ;
VAL_ 765 AirSusp_D_RqDrv 3 "NotUsed" 2 "On" 1 "Off" 0 "NoModeSelected" ;
VAL_ 765 Mc_VehUntTrpCoUsrSel_St 0 "TripComputer_metric" 1 "TripComputer_imperial" ;
VAL_ 765 Mc_VehUnitTempUsrSel_St 0 "Temperature_deg_c" 1 "Temperature_deg_f" ;
VAL_ 765 Mc_VehDayNightUsrSel_St 2 "Night" 1 "Day" 0 "Invalid" ;
VAL_ 765 Mc_VehTimeFrmtUsrSel_St 2 "24h_mode" 1 "12h_mode" 0 "Invalid" ;
VAL_ 765 Mc_VehThemeUsrSel_St 2 "Theme_2" 1 "Theme_1" 0 "Invalid" ;
VAL_ 765 Mc_VehLangUsrSel_St 32 "Indian_English" 31 "Thai" 30 "Slovak" 29 "Arabic" 28 "Taiwanese" 27 "Mandarin_Chinese" 26 "Korean" 25 "AU_English" 24 "Japanese" 23 "Braz_Portuguese" 22 "EU_Portuguese" 21 "Finish" 20 "Norwegian" 19 "Danish" 18 "Swedish" 17 "Hungarian" 16 "Greek" 15 "Czech" 14 "Polish" 13 "Flemish" 12 "Dutch" 11 "Russian" 10 "Turkish" 9 "Mex_Spanish" 8 "EU_Spanish" 7 "Cana_French" 6 "EU_French" 5 "Italian" 4 "German" 3 "NA_English" 2 "UK_English" 1 "Unknown" 0 "Invalid" ;
VAL_ 765 AwdRnge_D_ActlIpc 7 "Unknown" 6 "High_Range_2wd" 5 "High_Range_Auto" 4 "High_Range_Locked" 3 "Neutral" 2 "Low_Range_2wd" 1 "Low_Range_Auto" 0 "Low_Range_Locked" ;
VAL_ 765 AwdDrvMde_D_Rq 7 "Faulty" 6 "NotAvailable" 5 "RockCrawl" 4 "Baja" 3 "MudAndSand" 2 "Weather" 1 "Sport" 0 "Normal" ;
VAL_ 765 EngExhMdeQuiet_D2_Rq 7 "NotUsed_3" 6 "NotUsed_2" 5 "NotUsed_1" 4 "Track" 3 "Sport" 2 "Normal" 1 "Stealth" 0 "Null" ;
VAL_ 765 BrkLineLck_D_Rq 3 "Off" 2 "Engage" 1 "Initiate" 0 "NoRequest" ;
VAL_ 765 EdmSailMde_B_RqDrv 1 "On" 0 "Off" ;
VAL_ 765 Running_Board_Cmd 3 "Unused" 2 "Manually_Deployed" 1 "All_Enabled" 0 "All_Disabled" ;
VAL_ 508 Mc_DB1GtInfNbrOfItms_Rq 1 "OneItem" 0 "Standard" ;
VAL_ 508 Mc_DB1GetInfSetConf_Rq 31 "UnknownActive" 30 "Reserved_last" 9 "Reserved" 8 "Podcast" 7 "Audiobook" 6 "Composer" 5 "Track" 4 "Genre" 3 "Album" 2 "Artist" 1 "Playlist" 0 "Root" ;
VAL_ 508 Mc_DB1GetInfSetFilt3_Rq 1023 "All" 1022 "SIIndex_1022" 1 "SIIndex_1" 0 "NotEngaged" ;
VAL_ 508 Mc_DB1GetInfSetFilt2_Rq 65535 "All" 65534 "SIIndex_65534" 1 "SIIndex_1" 0 "NotEngaged" ;
VAL_ 508 Mc_DB1GetInfSetFilt1_Rq 65535 "All" 65534 "SIIndex_65534" 1 "SIIndex_1" 0 "NotEngaged" ;
VAL_ 507 Mc_DB1SetTrkSetConf_Rq 9 "Reserved" 8 "Podcast" 7 "Audiobook" 6 "Composer" 5 "Track" 4 "Genre" 3 "Album" 2 "Artist" 1 "Playlist" 0 "Root" 31 "UnknownActive" 30 "Reserved_last" ;
VAL_ 507 Mc_DB1SetTrkSetFilt3_Rq 1023 "All" 1022 "SIIndex_1022" 1 "SIIndex_1" 0 "NotEngaged" ;
VAL_ 507 Mc_DB1SetTrkSetFilt2_Rq 65535 "All" 65534 "SIIndex_65534" 1 "SIIndex_1" 0 "NotEngaged" ;
VAL_ 507 Mc_DB1SetTrkSetFilt1_Rq 65535 "All" 65534 "SIIndex_65534" 1 "SIIndex_1" 0 "NotEngaged" ;
VAL_ 506 Mc_AudioSourceSel3_Rq 4 "Reserved" 5 "SDcard" 3 "USB" 2 "BTAudio" 1 "CD" 0 "Inactive" ;
VAL_ 505 Mc_AudioSourceSel2_Rq 4 "Reserved" 5 "SDcard" 3 "USB" 2 "BTAudio" 1 "CD" 0 "Inactive" ;
VAL_ 505 Mc_CutItem2_Rq 3 "Inactive" 2 "ThreeQuarterFromBeginOneQ" 1 "End" 0 "Beginning" ;
VAL_ 505 Mc_FolderContent_Rq 2 "Inactive" 1 "ReqContentParentFolderOf" 0 "ReqContentParameterFolder" ;
VAL_ 403 McLangSel2_Rq 32 "Indian_English" 31 "Thai" 30 "Slovak" 29 "Arabic" 28 "Taiwanese" 27 "Mandarin_Chinese" 26 "Korean" 25 "AU_English" 24 "Japanese" 23 "Braz_Portuguese" 22 "EU_Portuguese" 21 "Finish" 20 "Norwegian" 19 "Danish" 18 "Swedish" 17 "Hungarian" 16 "Greek" 15 "Czech" 14 "Polish" 13 "Flemish" 12 "Dutch" 11 "Russian" 10 "Turkish" 9 "Mex_Spanish" 8 "EU_Spanish" 7 "Cana_French" 6 "EU_French" 5 "Italian" 4 "German" 3 "NA_English" 2 "UK_English" 1 "Unknown" 0 "Invalid" ;
VAL_ 403 DealerCall_B_Rq 1 "Yes" 0 "Null" ;
VAL_ 403 Mc_RepeatGuidance_Rq 1 "Active" 0 "Inactive" ;
VAL_ 403 Mc_CancelRoute_Rq 1 "Cancel" 0 "Inactive" ;
VAL_ 403 Mc_CancelCurrWaypt_Rq 1 "Cancel" 0 "Inactive" ;
VAL_ 403 Mc_TextMessage_Rq 3 "Cancel" 2 "Ignore" 1 "Listen" 0 "Invalid" ;
VAL_ 403 Mc_BTInCallOptions_Rq 6 "EndHoldCall" 5 "HoldCall" 4 "GotoHandsfreeMode" 3 "GotoPrivacyMode" 2 "JoinCalls" 1 "SwitchCalls" 0 "Inactive" ;
VAL_ 403 Mc_PhMicrophoneMute_Rq 3 "Reserved" 2 "MicrophoneUnmute" 1 "MicrophoneMute" 0 "Inactive" ;
VAL_ 403 Mc_LangSel_Rq 31 "Thai" 30 "Slovak" 29 "Arabic" 28 "Taiwanese" 27 "Mandarin_Chinese" 26 "Korean" 25 "AU_English" 24 "Japanese" 23 "Braz_Portuguese" 22 "EU_Portuguese" 21 "Finish" 20 "Norwegian" 19 "Danish" 18 "Swedish" 17 "Hungarian" 16 "Greek" 15 "Czech" 14 "Polish" 13 "Flemish" 12 "Dutch" 11 "Russian" 10 "Turkish" 9 "Mex_Spanish" 8 "EU_Spanish" 7 "Cana_French" 6 "EU_French" 5 "Italian" 4 "German" 3 "NA_English" 2 "UK_English" 1 "Unknown" 0 "Invalid" ;
VAL_ 401 Bezel_Beeps_Rq 0 "Inactive" 2 "Disable" 1 "Enable" ;
VAL_ 401 Disp_VehUntTripCoUsrSel 3 "Inactive" 1 "Imperial" 0 "Metric" ;
VAL_ 401 Disp_VehUnitTempUsrSel 3 "Inactive" 1 "Fahrenheit" 0 "Celsius" ;
VAL_ 401 Disp_LangSel_Rq 31 "Thai" 30 "Slovak" 29 "Arabic" 28 "Taiwanese" 27 "Mandarin_Chinese" 26 "Korean" 25 "AU_English" 24 "Japanese" 23 "Braz_Portuguese" 22 "EU_Portuguese" 21 "Finish" 20 "Norwegian" 19 "Danish" 18 "Swedish" 17 "Hungarian" 16 "Greek" 15 "Czech" 14 "Polish" 13 "Flemish" 12 "Dutch" 11 "Russian" 10 "Turkish" 9 "Mex_Spanish" 8 "EU_Spanish" 7 "Cana_French" 6 "EU_French" 5 "Italian" 4 "German" 3 "NA_English" 2 "UK_English" 1 "Unknown" 0 "Invalid" ;
VAL_ 401 Disp_LangSel2_Rq 32 "Indian_English" 31 "Thai" 30 "Slovak" 29 "Arabic" 28 "Taiwanese" 27 "Mandarin_Chinese" 26 "Korean" 25 "AU_English" 24 "Japanese" 23 "Braz_Portuguese" 22 "EU_Portuguese" 21 "Finish" 20 "Norwegian" 19 "Danish" 18 "Swedish" 17 "Hungarian" 16 "Greek" 15 "Czech" 14 "Polish" 13 "Flemish" 12 "Dutch" 11 "Russian" 10 "Turkish" 9 "Mex_Spanish" 8 "EU_Spanish" 7 "Cana_French" 6 "EU_French" 5 "Italian" 4 "German" 3 "NA_English" 2 "UK_English" 1 "Unknown" 0 "Invalid" ;
VAL_ 1143 ConsTipUnitPt_D_Dsply 3 "NotUsed" 2 "FuelEconomy" 1 "Distance" 0 "Percentage" ;
VAL_ 1143 ConsTipTot_Pc_Dsply 1023 "Faulty" 1022 "NoDataExists" ;
VAL_ 1143 ChrgCompltMsgTxt_D_Rq 3 "NotUsed_1" 2 "ChargeToFull" 1 "ChargeToFastChargeLimit" 0 "DefaultLabel" ;
VAL_ 1142 ConsTipV_No_Dsply 1023 "Faulty" 1022 "NoDataExists" ;
VAL_ 1142 ConsTipMsg3_D_Dsply 15 "NotUsed10" 14 "NotUsed9" 13 "NotUsed8" 12 "NotUsed7" 11 "NotUsed6" 10 "NotUsed5" 9 "NotUsed4" 8 "NotUsed3" 7 "NotUsed2" 6 "NotUsed1" 5 "ReduceIdleTime" 4 "ClimateUsage" 3 "VehicleSpeed" 2 "Deceleration" 1 "Acceleration" 0 "NoDisplay" ;
VAL_ 1142 ConsTipMsg2_D_Dsply 15 "NotUsed10" 14 "NotUsed9" 13 "NotUsed8" 12 "NotUsed7" 11 "NotUsed6" 10 "NotUsed5" 9 "NotUsed4" 8 "NotUsed3" 7 "NotUsed2" 6 "NotUsed1" 5 "ReduceIdleTime" 4 "ClimateUsage" 3 "VehicleSpeed" 2 "Deceleration" 1 "Acceleration" 0 "NoDisplay" ;
VAL_ 1142 ConsTipMsg1_D_Dsply 15 "NotUsed10" 14 "NotUsed9" 13 "NotUsed8" 12 "NotUsed7" 11 "NotUsed6" 10 "NotUsed5" 9 "NotUsed4" 8 "NotUsed3" 7 "NotUsed2" 6 "NotUsed1" 5 "ReduceIdleTime" 4 "ClimateUsage" 3 "VehicleSpeed" 2 "Deceleration" 1 "Acceleration" 0 "NoDisplay" ;
VAL_ 1142 ConsTipDecel_No_Dsply 1023 "Faulty" 1022 "NoDataExists" ;
VAL_ 1142 ConsTipA_No_Dsply 1023 "Faulty" 1022 "NoDataExists" ;
VAL_ 947 Outside_Air_Temp_Stat_UB 1 "Fresh_data" 0 "Unchanged_data" ;
VAL_ 947 Outside_Air_Temp_Stat 255 "Invalid" 254 "Unknown" ;
VAL_ 973 LaSysOffStat_D_Dsply 3 "Level_3" 2 "Level_2" 1 "Level_1" 0 "Level_0" ;
VAL_ 973 TsrVl1RstrcMsgTxt2_D_Rq 7 "NotUsed" 6 "Time" 5 "Trailer" 4 "Snow" 3 "RainWet" 2 "NoRecognizableRestrictn" 1 "NoSpeedLimitRestrictn" 0 "Null" ;
VAL_ 973 TsrVl2RstrcMsgTxt2_D_Rq 7 "NotUsed" 6 "Time" 5 "Trailer" 4 "Snow" 3 "RainWet" 2 "NoRecognizableRestrictn" 1 "NoSpeedLimitRestrictn" 0 "Null" ;
VAL_ 973 TsrVl2PrmntMsgTxt_D_Rq 3 "NotUsed" 2 "ShowPermanentlyWithSupp" 1 "ShowPermanentlyWithoutSupp" 0 "DoNotShowSignPermanent" ;
VAL_ 973 TsrVl1PrmntMsgTxt_D_Rq 3 "NotUsed" 2 "ShowPermanentlyWithSupp" 1 "ShowPermanentlyWithoutSupp" 0 "DoNotShowSignPermanent" ;
VAL_ 973 TsrOvtkMsgTxt2_D_Rq 15 "NotUsed5" 14 "NotUsed4" 13 "NotUsed3" 12 "NotUsed2" 11 "NotUsed1" 10 "LimForTrucksCancelled" 9 "LimForTrucksWoQlfdRstrc" 8 "LimForTrucksWithoutRstrc" 7 "LimAllCancelled" 6 "LimAllWithRstrcTime" 5 "LimAllWithRstrcTrailer" 4 "LimAllWithRstrcSnow" 3 "LimAllWithRstrcRain" 2 "LimAllWithoutQlfdRstrc" 1 "LimAllWithoutRestriction" 0 "OvertakingAllowed" ;
VAL_ 973 WwaWarn_B_Rq 1 "On" 0 "Off" ;
VAL_ 973 TsrVlUnitMsgTxt_D_Rq 3 "NoDataExists" 2 "Mph" 1 "Kph" 0 "Null" ;
VAL_ 973 TsrVLim2MsgTxt_D_Rq 255 "NoLimit" 254 "NotUsed2" 253 "NotUsed1" 252 "NotToBeDisplayed" 251 "LimitCancelled" 31 "1F_FA_Message31_250" 30 "Message30" 29 "Message29" 28 "Message28" 27 "Message27" 26 "Message26" 25 "Message25" 24 "Message24" 23 "Message23" 22 "Message22" 21 "Message21" 20 "Message20" 19 "Message19" 18 "Message18" 17 "Message17" 16 "Message16" 15 "Message15" 14 "Message14" 13 "Message13" 12 "Message12" 11 "Message11" 10 "Message10" 9 "Message9" 8 "Message8" 7 "Message7" 6 "Message6" 5 "Message5" 4 "Message4" 3 "Message3" 2 "Message2" 1 "Message1" 0 "Null" ;
VAL_ 973 TsrVLim1MsgTxt_D_Rq 255 "NoLimit" 254 "NotUsed2" 253 "NotUsed1" 252 "NotToBeDisplayed" 251 "LimitCancelled" 31 "1F_FA_Message31_250" 30 "Message30" 29 "Message29" 28 "Message28" 27 "Message27" 26 "Message26" 25 "Message25" 24 "Message24" 23 "Message23" 22 "Message22" 21 "Message21" 20 "Message20" 19 "Message19" 18 "Message18" 17 "Message17" 16 "Message16" 15 "Message15" 14 "Message14" 13 "Message13" 12 "Message12" 11 "Message11" 10 "Message10" 9 "Message9" 8 "Message8" 7 "Message7" 6 "Message6" 5 "Message5" 4 "Message4" 3 "Message3" 2 "Message2" 1 "Message1" 0 "Null" ;
VAL_ 973 TsrVl2StatMsgTxt_D_Rq 3 "LimitOutdated" 2 "LimitReiable" 1 "LimitChanged" 0 "Null" ;
VAL_ 973 TsrVl2RstrcMsgTxt_D_Rq 3 "NotUsed" 2 "NoRecognizableRestriction" 1 "NoSpeedLimitRestriction" 0 "Null" ;
VAL_ 973 TsrVl1StatMsgTxt_D_Rq 3 "LimitOutdated" 2 "LimitReiable" 1 "LimitChanged" 0 "Null" ;
VAL_ 973 TsrVl1RstrcMsgTxt_D_Rq 3 "NotUsed" 2 "NoRecognizableRestriction" 1 "NoSpeedLimitRestriction" 0 "Null" ;
VAL_ 973 TsrStatMsgTxt_D_Rq 7 "NotUsed" 6 "NoDataExists" 5 "TSR_Error" 4 "Available_NavigationOnly" 3 "Available_CameraOnly" 2 "Available_FusionMode" 1 "TSR_Off" 0 "Null" ;
VAL_ 973 TsrOvtkStatMsgTxt_D_Rq 3 "LimitOutdated" 2 "LimitReiable" 1 "LimitChanged" 0 "Null" ;
VAL_ 973 TsrOvtkMsgTxt_D_Rq 7 "LimForTrucksCancelled" 6 "LimForTrucksWoQlfdRstrc" 5 "LimForTrucksWithoutRstrc" 4 "LimAllCancelled" 3 "LimAllWithoutQlfdRstrc" 2 "LimAllWithoutRestriction" 1 "OvertakingAllowed" 0 "Null" ;
VAL_ 973 TsrOswWarnMsgTxt_D_Rq 3 "NotUsed" 2 "True" 1 "False" 0 "Null" ;
VAL_ 973 TsrMsgTxt_D_Rq 15 "NotUsed6" 14 "NotUsed5" 13 "NotUsed4" 12 "NotUsed3" 11 "NotUsed2" 10 "NotUsed1" 9 "RecgnzdSignNotUsblForDsply" 8 "LimitedSystemPerformance" 7 "OffRoad" 6 "RegionNotSupported" 5 "CountryNotSupported" 4 "WrngNavDatIncompDatCarrier" 3 "NoNavDataAvailable" 2 "NoNavAvailableSwitchedOff" 1 "NoInformationAllOK" 0 "Null" ;
VAL_ 756 AdjustableChimeVol2_Rq 15 "NotUsed_3" 14 "NotUsed_2" 13 "NotUsed_1" 12 "LevelPlus6" 11 "LevelPlus5" 10 "LevelPlus4" 9 "LevelPlus3" 8 "LevelPlus2" 7 "LevelPlus1" 6 "LevelMinus1" 5 "LevelMinus2" 4 "LevelMinus3" 3 "LevelMinus4" 2 "LevelMinus5" 1 "LevelMinus6" 0 "DefaultVolume" ;
VAL_ 756 Chime_Time_Criticality2 2 "Low" 1 "High" 0 "Inactive" ;
VAL_ 756 Chime_Occurence2 15 "Continuous" 14 "14Repititions" 13 "13Repititions" 12 "12Repititions" 11 "11Repititions" 10 "10Repititions" 9 "9Repititions" 8 "8Repititions" 7 "7Repititions" 6 "6Repititions" 5 "5Repititions" 4 "4Repititions" 3 "3Repititions" 2 "2Repititions" 1 "PlayOnce" 0 "Inactive" ;
VAL_ 756 Chime_Directionality2 3 "RearSpeakers" 2 "FrontSpeakers" 1 "ALL" 0 "Inactive" ;
VAL_ 756 Chime2Id_No_Rq 255 "Id255" 250 "Id250" 240 "Id240" 220 "Id220" 200 "Id200" 180 "Id180" 160 "Id160" 140 "Id140" 120 "Id120" 100 "Id100" 90 "Id90" 80 "Id80" 70 "Id70" 60 "Id60" 50 "Id50" 40 "Id40" 30 "Id30" 20 "Id20" 10 "Id10" 1 "Id1" 0 "Inactive" ;
VAL_ 544 ChimeId_No_Rq 255 "Id255" 250 "Id250" 240 "Id240" 220 "Id220" 200 "Id200" 180 "Id180" 160 "Id160" 140 "Id140" 120 "Id120" 100 "Id100" 90 "Id90" 80 "Id80" 70 "Id70" 60 "Id60" 50 "Id50" 40 "Id40" 30 "Id30" 20 "Id20" 10 "Id10" 1 "Id1" 0 "Inactive" ;
VAL_ 544 AdjustableChimeVol_Rq 15 "NotUsed_3" 14 "NotUsed_2" 13 "NotUsed_1" 12 "LevelPlus6" 11 "LevelPlus5" 10 "LevelPlus4" 9 "LevelPlus3" 8 "LevelPlus2" 7 "LevelPlus1" 6 "LevelMinus1" 5 "LevelMinus2" 4 "LevelMinus3" 3 "LevelMinus4" 2 "LevelMinus5" 1 "LevelMinus6" 0 "DefaultVolume" ;
VAL_ 544 Chime_Occurence 15 "Continuous" 14 "14Repititions" 13 "13Repititions" 12 "12Repititions" 11 "11Repititions" 10 "10Repititions" 9 "9Repititions" 8 "8Repititions" 7 "7Repititions" 6 "6Repititions" 5 "5Repititions" 4 "4Repititions" 3 "3Repititions" 2 "2Repititions" 1 "PlayOnce" 0 "Inactive" ;
VAL_ 544 Chime_Time_Criticality 2 "Low" 1 "High" 0 "Inactive" ;
VAL_ 544 Chime_Directionality 3 "RearSpeakers" 2 "FrontSpeakers" 1 "ALL" 0 "Inactive" ;
VAL_ 291 LangUpdate_Rsp 2 "Language_Not_Supported" 1 "Language_Updated" 0 "Inactive" ;
VAL_ 400 Mc_SetCurrStatMCCh_Rq 7 "MCChannel7" 6 "MCChannel6" 5 "MCChannel5" 4 "MCChannel4" 3 "MCChannel3" 2 "MCChannel2" 1 "MCChannel1" 0 "Inactive" ;
VAL_ 400 Mc_SetCurrentStatOp_Rq 0 "Inactive" 1 "SetCurrentFrequency" 2 "SetCurrentPiCode" 3 "SetCurrentStation" ;
VAL_ 400 Mc_PerTUPresetArea_Rq 13 "reserved" 12 "GetSAT3PresetData" 11 "GetSAT2PresetData" 15 "reserved_last" 10 "GetSAT1PresetData" 9 "GetDAB2PresetData" 8 "GetDAB1PresetData" 7 "GetDAB3PresetData" 6 "GetAmPresetData" 5 "GetAmAstPresetData" 4 "GetFmAstPresetData" 3 "GetFm3PresetData" 2 "GetFm2PresetData" 1 "GetFm1PresetData" 0 "Inactive" ;
VAL_ 647 HEC_BTIncomingCall_Rq 0 "Inactive" 1 "AcceptIncomingCall" 2 "DeclineIncomingCall" ;
VAL_ 647 HEC_BTEndTelService_Rq 1 "EndOngoingTelephonyCall" 0 "Inactive" ;
